VERSION "dbc-export 1 2026.26.6.5"

NS_ :

BS_:

BU_: APP BMS CC CMP CMPD CP DAS DI DIF DIR EPBL EPBR EVSE FC GTW HCML HCMR HVP ICR PCS PCS2 PM PMF PMR PTC SCCM SDCR TAS UMC V2G VC VCBATT VCBATT1 VCBATT2 VCFRONT VCFRONT1 VCLEFT VCRIGHT VCSEC

BO_ 680 EPBL_status: 8 EPBL
 SG_ EPBL_systemStatus : 0|4@1+ (1,0) [0|15] "" Vector__XXX
 SG_ EPBL_freeRollModeStatus : 4|2@1+ (1,0) [0|3] "" Vector__XXX
 SG_ EPBL_driverIsLeaving : 6|1@1+ (1,0) [0|1] "" Vector__XXX
 SG_ EPBL_driverIsLeavingAnySpeed : 7|1@1+ (1,0) [0|1] "" Vector__XXX
 SG_ EPBL_systemCdpAvailable : 8|1@1+ (1,0) [0|1] "" Vector__XXX
 SG_ EPBL_chimeRequest : 9|3@1+ (1,0) [0|7] "" Vector__XXX
 SG_ EPBL_telltale : 12|3@1+ (1,0) [0|6] "" Vector__XXX
 SG_ EPBL_contactorCycleNotNeededForW : 15|1@1+ (1,0) [0|1] "" Vector__XXX
 SG_ EPBL_redundantBrakingEnabled : 16|1@1+ (1,0) [0|1] "" Vector__XXX
 SG_ EPBL_summonEnabled : 17|1@1+ (1,0) [0|1] "" Vector__XXX
 SG_ EPBL_brakeLight : 18|1@1+ (1,0) [0|1] "" Vector__XXX
 SG_ EPBL_epbConfigMismatch : 19|1@1+ (1,0) [0|1] "" Vector__XXX
 SG_ EPBL_brakeConfirmedPressed : 20|1@1+ (1,0) [0|1] "" Vector__XXX
 SG_ EPBL_requestUserConfirmation : 21|1@1+ (1,0) [0|1] "" Vector__XXX
 SG_ EPBL_uiWinchModeMiscBlocking : 22|1@1+ (1,0) [0|1] "" Vector__XXX
 SG_ EPBL_winchModeActive : 23|1@1+ (1,0) [0|1] "" Vector__XXX
 SG_ EPBL_updateMode : 24|1@1+ (1,0) [0|1] "" Vector__XXX
 SG_ EPBL_winchModePermissive : 25|1@1+ (1,0) [0|1] "" Vector__XXX
 SG_ EPBL_winchModePending : 26|1@1+ (1,0) [0|1] "" Vector__XXX
 SG_ EPBL_cdpRequest : 27|1@1+ (1,0) [0|1] "" Vector__XXX
 SG_ EPBL_uiParkAvailable : 28|2@1+ (1,0) [0|3] "" Vector__XXX
 SG_ EPBL_brakeDiscWipeRequest : 30|2@1+ (1,0) [0|2] "" Vector__XXX
 SG_ EPBL_showUiGearShifter : 32|1@1+ (1,0) [0|1] "" Vector__XXX
 SG_ EPBL_uiWinchModeLvStatus : 33|2@1+ (1,0) [0|3] "" Vector__XXX
 SG_ EPBL_autonomyBehavior : 43|2@1+ (1,0) [0|3] "" Vector__XXX
 SG_ EPBL_showStalkFaultedOnUi : 45|1@1+ (1,0) [0|1] "" Vector__XXX
 SG_ EPBL_espPowerRequest : 46|1@1+ (1,0) [0|1] "" Vector__XXX
 SG_ EPBL_okToPark : 47|1@1+ (1,0) [0|1] "" Vector__XXX
 SG_ EPBL_hornRequest : 48|1@1+ (1,0) [0|1] "" Vector__XXX
 SG_ EPBL_winchModeAvailable : 49|1@1+ (1,0) [0|1] "" Vector__XXX
 SG_ EPBL_bothDisconnected : 50|1@1+ (1,0) [0|1] "" Vector__XXX
 SG_ EPBL_blockDrive : 51|1@1+ (1,0) [0|1] "" Vector__XXX
 SG_ EPBL_statusCounter : 52|4@1+ (1,0) [0|15] "" Vector__XXX
 SG_ EPBL_statusChecksum : 56|8@1+ (1,0) [0|255] "" Vector__XXX

BO_ 2024 EPBR_info: 8 EPBR
 SG_ EPBR_infoIndex M : 0|8@1+ (1,0) [0|255] "" Vector__XXX
 SG_ EPBR_infoBuildType m10 : 8|3@1+ (1,0) [0|7] "" Vector__XXX
 SG_ EPBR_infoBuildConfigId m10 : 16|16@1+ (1,0) [0|65535] "" Vector__XXX
 SG_ EPBR_infoHardwareId m10 : 32|16@1+ (1,0) [0|65535] "" Vector__XXX
 SG_ EPBR_infoComponentId m10 : 48|16@1+ (1,0) [0|65535] "" Vector__XXX
 SG_ EPBR_infoPcbaId m11 : 8|8@1+ (1,0) [0|255] "" Vector__XXX
 SG_ EPBR_infoAssemblyId m11 : 16|8@1+ (1,0) [0|254] "" Vector__XXX
 SG_ EPBR_infoUsageId m11 : 24|16@1+ (1,0) [0|65535] "" Vector__XXX
 SG_ EPBR_infoSubUsageId m11 : 40|16@1+ (1,0) [0|65535] "" Vector__XXX
 SG_ EPBR_infoAppCrc m13 : 8|32@1+ (1,0) [0|4294967295] "" Vector__XXX
 SG_ EPBR_infoAppGitHash m17 : 8|56@1+ (1,0) [0|7.20575940379e+16] "" Vector__XXX
 SG_ EPBR_infoBootGitHash m18 : 8|56@1+ (1,0) [0|7.20575940379e+16] "" Vector__XXX
 SG_ EPBR_infoPlatformType m19 : 8|8@1+ (1,0) [0|255] "" Vector__XXX
 SG_ EPBR_infoBootUdsProtoVersion m20 : 8|16@1+ (1,0) [0|65535] "" Vector__XXX
 SG_ EPBR_infoBootCrc m20 : 24|32@1+ (1,0) [0|4294967295] "" Vector__XXX

BO_ 552 EPBR_internalStatus: 8 EPBR
 SG_ EPBR_unitStatus : 0|5@1+ (1,0) [0|31] "" Vector__XXX
 SG_ EPBR_unitFaultStatus : 5|2@1+ (1,0) [0|3] "" Vector__XXX
 SG_ EPBR_summonState : 8|3@1+ (1,0) [0|7] "" Vector__XXX
 SG_ EPBR_disconnected : 11|1@1+ (1,0) [0|1] "" Vector__XXX
 SG_ EPBR_pistonTouchingRotor : 12|1@1+ (1,0) [0|1] "" Vector__XXX
 SG_ EPBR_csmFaultReason : 13|5@1+ (1,0) [0|31] "" Vector__XXX
 SG_ EPBR_esmOperationTrigger : 18|6@1+ (1,0) [0|63] "" Vector__XXX
 SG_ EPBR_summonFaultReason : 24|5@1+ (1,0) [0|31] "" Vector__XXX
 SG_ EPBR_localServiceModeActive : 29|1@1+ (1,0) [0|1] "" Vector__XXX
 SG_ EPBR_localCdpState : 30|2@1+ (1,0) [0|3] "" Vector__XXX
 SG_ EPBR_chimeRequestLocal : 33|3@1+ (1,0) [0|7] "" Vector__XXX
 SG_ EPBR_telltaleLocal : 39|3@1+ (1,0) [0|6] "" Vector__XXX
 SG_ EPBR_driverIsLeavingLocal : 42|1@1+ (1,0) [0|1] "" Vector__XXX
 SG_ EPBR_driverIsLeavingAnySpeedLoca : 43|1@1+ (1,0) [0|1] "" Vector__XXX
 SG_ EPBR_internalCDPRequest : 44|1@1+ (1,0) [0|1] "" Vector__XXX
 SG_ EPBR_esmSpeedClass : 45|3@1+ (1,0) [0|7] "" Vector__XXX
 SG_ EPBR_learnedEpbConfig : 48|4@1+ (1,0) [0|15] "" Vector__XXX
 SG_ EPBR_internalStatusCounter : 52|4@1+ (1,0) [0|15] "" Vector__XXX
 SG_ EPBR_internalStatusChecksum : 56|8@1+ (1,0) [0|255] "" Vector__XXX

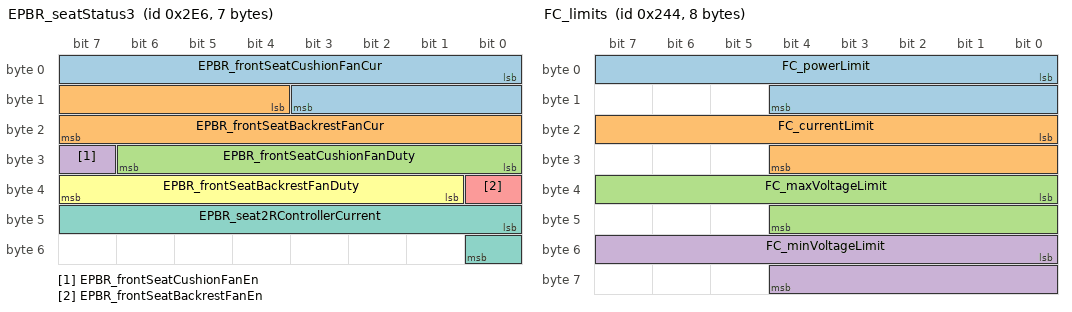
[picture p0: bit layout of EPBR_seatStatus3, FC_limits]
BO_ 742 EPBR_seatStatus3: 7 EPBR
 SG_ EPBR_frontSeatCushionFanCur : 0|12@1+ (0.01,0) [0|40.95] "A" Vector__XXX
 SG_ EPBR_frontSeatBackrestFanCur : 12|12@1+ (0.01,0) [0|40.95] "A" Vector__XXX
 SG_ EPBR_frontSeatCushionFanDuty : 24|7@1+ (1,0) [0|100] "%" Vector__XXX
 SG_ EPBR_frontSeatCushionFanEn : 31|1@1+ (1,0) [0|1] "" Vector__XXX
 SG_ EPBR_frontSeatBackrestFanEn : 32|1@1+ (1,0) [0|1] "" Vector__XXX
 SG_ EPBR_frontSeatBackrestFanDuty : 33|7@1+ (1,0) [0|100] "%" Vector__XXX
 SG_ EPBR_seat2RControllerCurrent : 40|9@1+ (0.2,0) [0|102] "A" Vector__XXX

BO_ 744 EPBR_status: 8 EPBR
 SG_ EPBR_systemStatus : 0|4@1+ (1,0) [0|15] "" Vector__XXX
 SG_ EPBR_freeRollModeStatus : 4|2@1+ (1,0) [0|3] "" Vector__XXX
 SG_ EPBR_driverIsLeaving : 6|1@1+ (1,0) [0|1] "" Vector__XXX
 SG_ EPBR_driverIsLeavingAnySpeed : 7|1@1+ (1,0) [0|1] "" Vector__XXX
 SG_ EPBR_systemCdpAvailable : 8|1@1+ (1,0) [0|1] "" Vector__XXX
 SG_ EPBR_chimeRequest : 9|3@1+ (1,0) [0|7] "" Vector__XXX
 SG_ EPBR_telltale : 12|3@1+ (1,0) [0|6] "" Vector__XXX
 SG_ EPBR_audioCurrentSpikeDetected : 15|1@1+ (1,0) [0|1] "" Vector__XXX
 SG_ EPBR_redundantBrakingEnabled : 16|1@1+ (1,0) [0|1] "" Vector__XXX
 SG_ EPBR_summonEnabled : 17|1@1+ (1,0) [0|1] "" Vector__XXX
 SG_ EPBR_brakeLight : 18|1@1+ (1,0) [0|1] "" Vector__XXX
 SG_ EPBR_epbConfigMismatch : 19|1@1+ (1,0) [0|1] "" Vector__XXX
 SG_ EPBR_brakeConfirmedPressed : 20|1@1+ (1,0) [0|1] "" Vector__XXX
 SG_ EPBR_requestUserConfirmation : 21|1@1+ (1,0) [0|1] "" Vector__XXX
 SG_ EPBR_uiWinchModeMiscBlocking : 22|1@1+ (1,0) [0|1] "" Vector__XXX
 SG_ EPBR_winchModeActive : 23|1@1+ (1,0) [0|1] "" Vector__XXX
 SG_ EPBR_updateMode : 24|1@1+ (1,0) [0|1] "" Vector__XXX
 SG_ EPBR_winchModePermissive : 25|1@1+ (1,0) [0|1] "" Vector__XXX
 SG_ EPBR_winchModePending : 26|1@1+ (1,0) [0|1] "" Vector__XXX
 SG_ EPBR_cdpRequest : 27|1@1+ (1,0) [0|1] "" Vector__XXX
 SG_ EPBR_uiParkAvailable : 28|2@1+ (1,0) [0|3] "" Vector__XXX
 SG_ EPBR_brakeDiscWipeRequest : 30|2@1+ (1,0) [0|2] "" Vector__XXX
 SG_ EPBR_showUiGearShifter : 32|1@1+ (1,0) [0|1] "" Vector__XXX
 SG_ EPBR_uiWinchModeLvStatus : 33|2@1+ (1,0) [0|3] "" Vector__XXX
 SG_ EPBR_contactorCycleNotNeededForW : 35|1@1+ (1,0) [0|1] "" Vector__XXX
 SG_ EPBR_autonomyBehavior : 43|2@1+ (1,0) [0|3] "" Vector__XXX
 SG_ EPBR_showStalkFaultedOnUi : 45|1@1+ (1,0) [0|1] "" Vector__XXX
 SG_ EPBR_espPowerRequest : 46|1@1+ (1,0) [0|1] "" Vector__XXX
 SG_ EPBR_okToPark : 47|1@1+ (1,0) [0|1] "" Vector__XXX
 SG_ EPBR_hornRequest : 48|1@1+ (1,0) [0|1] "" Vector__XXX
 SG_ EPBR_winchModeAvailable : 49|1@1+ (1,0) [0|1] "" Vector__XXX
 SG_ EPBR_bothDisconnected : 50|1@1+ (1,0) [0|1] "" Vector__XXX
 SG_ EPBR_blockDrive : 51|1@1+ (1,0) [0|1] "" Vector__XXX
 SG_ EPBR_statusCounter : 52|4@1+ (1,0) [0|15] "" Vector__XXX
 SG_ EPBR_statusChecksum : 56|8@1+ (1,0) [0|255] "" Vector__XXX

BO_ 1662 EVSE_isoTpToVeh: 8 EVSE
 SG_ EVSE_isoTpToVehData : 0|64@1+ (1,0) [0|1.84467440737e+19] "" Vector__XXX

BO_ 1117 FC_evseBilling: 8 FC
 SG_ FC_evseBillingDataSelect M : 0|1@1+ (1,0) [0|1] "" Vector__XXX
 SG_ FC_evseBillingEnergy m0 : 4|20@1+ (0.001,0) [0|1048.575] "kWh" Vector__XXX
 SG_ FC_evseMeterPower m0 : 24|20@1+ (0.001,0) [0|1048.575] "kW" Vector__XXX
 SG_ FC_evseMeterCurrent m0 : 44|10@1+ (1,0) [0|1023] "A" Vector__XXX
 SG_ FC_evseMeterVoltage m0 : 54|10@1+ (1,0) [0|1023] "V" Vector__XXX
 SG_ FC_evseMeterFwGitHash m1 : 4|56@1+ (1,0) [0|7.20575940379e+16] "" Vector__XXX

BO_ 1334 FC_evseBilling2: 8 FC
 SG_ FC_evseBilling2DataSelect M : 0|4@1+ (1,0) [0|15] "" Vector__XXX
 SG_ FC_evsePpuEnabled m0 : 4|1@1+ (1,0) [0|1] "" Vector__XXX
 SG_ FC_evseBillingEnergyHighRes m0 : 8|24@1+ (0.0001,0) [0|1677.7214] "kWh" Vector__XXX

BO_ 1303 FC_identifier: 8 FC
 SG_ FC_id : 0|32@1+ (1,0) [0|4294967295] "" Vector__XXX
 SG_ FC_sessionId : 32|32@1+ (1,0) [0|4294967295] "" Vector__XXX

BO_ 1310 FC_info: 8 FC
 SG_ FC_infoIndex M : 0|8@1+ (1,0) [0|255] "" Vector__XXX
 SG_ FC_infoBuildType m10 : 8|8@1+ (1,0) [0|255] "" Vector__XXX
 SG_ FC_infoBuildConfigID m10 : 16|16@1+ (1,0) [0|65535] "" Vector__XXX
 SG_ FC_infoHardwareID m10 : 32|16@1+ (1,0) [0|65535] "" Vector__XXX
 SG_ FC_infoComponentID m10 : 48|16@1+ (1,0) [0|65535] "" Vector__XXX
 SG_ FC_infoPcbaID m11 : 16|8@1+ (1,0) [0|255] "" Vector__XXX
 SG_ FC_infoAssemblyID m11 : 24|8@1+ (1,0) [0|255] "" Vector__XXX
 SG_ FC_infoUsageID m11 : 32|16@1+ (1,0) [0|65535] "" Vector__XXX
 SG_ FC_infoSubUsageID m11 : 48|16@1+ (1,0) [0|65535] "" Vector__XXX
 SG_ FC_infoApplicationCRC m13 : 32|32@1+ (1,0) [0|4294967295] "" Vector__XXX
 SG_ FC_infoAppGitHashBytes m17 : 8|56@1+ (1,0) [0|7.20575940379e+16] "" Vector__XXX
 SG_ FC_infoBootGitHashBytes m18 : 8|56@1+ (1,0) [0|7.20575940379e+16] "" Vector__XXX
 SG_ FC_infoPlatformType m19 : 8|8@1+ (1,0) [0|255] "" Vector__XXX
 SG_ FC_infoMajorVersion m19 : 16|8@1+ (1,0) [0|255] "" Vector__XXX
 SG_ FC_infoBranchOrigin m19 : 24|8@1+ (1,0) [0|255] "" Vector__XXX
 SG_ FC_infoMaturity m19 : 32|8@1+ (1,0) [0|255] "" Vector__XXX
 SG_ FC_infoHardwareRevision m19 : 40|8@1+ (1,0) [0|255] "" Vector__XXX
 SG_ FC_partNumChar01 m25 : 8|8@1+ (1,0) [0|255] "" Vector__XXX
 SG_ FC_partNumChar02 m25 : 16|8@1+ (1,0) [0|255] "" Vector__XXX
 SG_ FC_partNumChar03 m25 : 24|8@1+ (1,0) [0|255] "" Vector__XXX
 SG_ FC_partNumChar04 m25 : 32|8@1+ (1,0) [0|255] "" Vector__XXX
 SG_ FC_partNumChar05 m25 : 40|8@1+ (1,0) [0|255] "" Vector__XXX
 SG_ FC_partNumChar06 m25 : 48|8@1+ (1,0) [0|255] "" Vector__XXX
 SG_ FC_partNumChar07 m25 : 56|8@1+ (1,0) [0|255] "" Vector__XXX
 SG_ FC_partNumChar08 m26 : 8|8@1+ (1,0) [0|255] "" Vector__XXX
 SG_ FC_partNumChar09 m26 : 16|8@1+ (1,0) [0|255] "" Vector__XXX
 SG_ FC_partNumChar10 m26 : 24|8@1+ (1,0) [0|255] "" Vector__XXX
 SG_ FC_partNumChar11 m26 : 32|8@1+ (1,0) [0|255] "" Vector__XXX
 SG_ FC_partNumChar12 m26 : 40|8@1+ (1,0) [0|255] "" Vector__XXX
 SG_ FC_partNumChar13 m26 : 48|8@1+ (1,0) [0|255] "" Vector__XXX
 SG_ FC_partNumChar14 m26 : 56|8@1+ (1,0) [0|255] "" Vector__XXX
 SG_ FC_partNumChar15 m27 : 8|8@1+ (1,0) [0|255] "" Vector__XXX
 SG_ FC_partNumChar16 m27 : 16|8@1+ (1,0) [0|255] "" Vector__XXX
 SG_ FC_partNumChar17 m27 : 24|8@1+ (1,0) [0|255] "" Vector__XXX
 SG_ FC_partNumChar18 m27 : 32|8@1+ (1,0) [0|255] "" Vector__XXX
 SG_ FC_partNumChar19 m27 : 40|8@1+ (1,0) [0|255] "" Vector__XXX
 SG_ FC_partNumChar20 m27 : 48|8@1+ (1,0) [0|255] "" Vector__XXX

BO_ 580 FC_limits: 8 FC
 SG_ FC_powerLimit : 0|13@1+ (0.06225586,0) [0|509.8754934] "kW" Vector__XXX
 SG_ FC_currentLimit : 16|13@1+ (0.07324219,0) [0|599.8535361] "A" Vector__XXX
 SG_ FC_maxVoltageLimit : 32|13@1+ (0.07324219,0) [0|599.8535361] "V" Vector__XXX
 SG_ FC_minVoltageLimit : 48|13@1+ (0.07324219,0) [0|599.8535361] "V" Vector__XXX

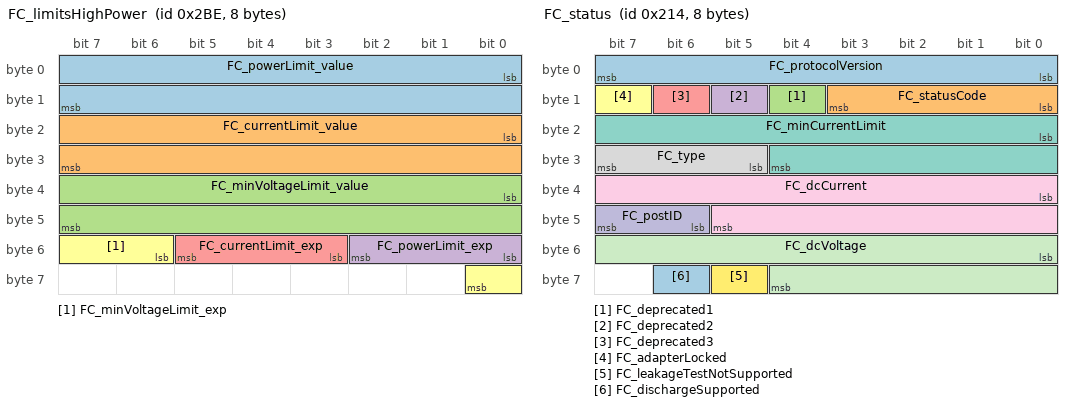
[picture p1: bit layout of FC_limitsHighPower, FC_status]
BO_ 702 FC_limitsHighPower: 8 FC
 SG_ FC_powerLimit_value : 0|16@1- (1,0) [-32767|32767] "*10^exp kW" Vector__XXX
 SG_ FC_currentLimit_value : 16|16@1- (1,0) [-32767|32767] "*10^exp A" Vector__XXX
 SG_ FC_minVoltageLimit_value : 32|16@1- (1,0) [-32767|32767] "*10^exp V" Vector__XXX
 SG_ FC_powerLimit_exp : 48|3@1- (1,0) [-4|3] "" Vector__XXX
 SG_ FC_currentLimit_exp : 51|3@1- (1,0) [-4|3] "" Vector__XXX
 SG_ FC_minVoltageLimit_exp : 54|3@1- (1,0) [-4|3] "" Vector__XXX

BO_ 1345 FC_maxLimits: 8 FC
 SG_ FC_maxPowerLimit : 0|13@1+ (0.06225586,0) [0|509.8754934] "kW" Vector__XXX
 SG_ FC_maxCurrentLimit : 16|13@1+ (0.07324219,0) [0|599.8535361] "A" Vector__XXX

BO_ 1300 FC_serial: 8 FC
 SG_ FC_serialDataSelect M : 0|7@1+ (1,0) [0|127] "" Vector__XXX
 SG_ FC_serialChar01 m0 : 8|8@1+ (1,0) [0|255] "" Vector__XXX
 SG_ FC_serialChar02 m0 : 16|8@1+ (1,0) [0|255] "" Vector__XXX
 SG_ FC_serialChar03 m0 : 24|8@1+ (1,0) [0|255] "" Vector__XXX
 SG_ FC_serialChar04 m0 : 32|8@1+ (1,0) [0|255] "" Vector__XXX
 SG_ FC_serialChar05 m0 : 40|8@1+ (1,0) [0|255] "" Vector__XXX
 SG_ FC_serialChar06 m0 : 48|8@1+ (1,0) [0|255] "" Vector__XXX
 SG_ FC_serialChar07 m0 : 56|8@1+ (1,0) [0|255] "" Vector__XXX
 SG_ FC_serialChar08 m1 : 8|8@1+ (1,0) [0|255] "" Vector__XXX
 SG_ FC_serialChar09 m1 : 16|8@1+ (1,0) [0|255] "" Vector__XXX
 SG_ FC_serialChar10 m1 : 24|8@1+ (1,0) [0|255] "" Vector__XXX
 SG_ FC_serialChar11 m1 : 32|8@1+ (1,0) [0|255] "" Vector__XXX
 SG_ FC_serialChar12 m1 : 40|8@1+ (1,0) [0|255] "" Vector__XXX
 SG_ FC_serialChar13 m1 : 48|8@1+ (1,0) [0|255] "" Vector__XXX
 SG_ FC_serialChar14 m1 : 56|8@1+ (1,0) [0|255] "" Vector__XXX
 SG_ FC_serialChar15 m2 : 8|8@1+ (1,0) [0|255] "" Vector__XXX
 SG_ FC_serialChar16 m2 : 16|8@1+ (1,0) [0|255] "" Vector__XXX
 SG_ FC_serialChar17 m2 : 24|8@1+ (1,0) [0|255] "" Vector__XXX

BO_ 532 FC_status: 8 FC
 SG_ FC_protocolVersion : 0|8@1+ (1,0) [0|255] "" Vector__XXX
 SG_ FC_statusCode : 8|4@1+ (1,0) [1|15] "" Vector__XXX
 SG_ FC_deprecated1 : 12|1@1+ (1,0) [0|1] "" Vector__XXX
 SG_ FC_deprecated2 : 13|1@1+ (1,0) [0|1] "" Vector__XXX
 SG_ FC_deprecated3 : 14|1@1+ (1,0) [0|1] "" Vector__XXX
 SG_ FC_adapterLocked : 15|1@1+ (1,0) [0|1] "" Vector__XXX
 SG_ FC_minCurrentLimit : 16|13@1+ (0.1,0) [0|600] "A" Vector__XXX
 SG_ FC_type : 29|3@1+ (1,0) [0|6] "" Vector__XXX
 SG_ FC_dcCurrent : 32|14@1- (0.07324219,0) [-600|599.92675781] "A" Vector__XXX
 SG_ FC_postID : 46|2@1+ (1,0) [0|2] "" Vector__XXX
 SG_ FC_dcVoltage : 48|13@1+ (0.07324219,0) [0|599.92675822] "V" Vector__XXX
 SG_ FC_leakageTestNotSupported : 61|1@1+ (1,0) [0|1] "" Vector__XXX
 SG_ FC_dischargeSupported : 62|1@1+ (1,0) [0|1] "" Vector__XXX

BO_ 533 FC_status2: 1 FC
 SG_ FC_externalIsolationResistance : 0|8@1+ (40,0) [0|10160] "kOhm" Vector__XXX

BO_ 535 FC_status3: 8 FC
 SG_ FC_status3DataSelect M : 0|7@1+ (1,0) [0|127] "" Vector__XXX
 SG_ FC_status3DummySig : 7|1@1+ (1,0) [0|1] "" Vector__XXX
 SG_ FC_class m0 : 8|8@1+ (1,0) [1|255] "" Vector__XXX
 SG_ FC_brand m0 : 16|4@1+ (1,0) [1|15] "" Vector__XXX
 SG_ FC_coolingType m0 : 20|4@1+ (1,0) [1|15] "" Vector__XXX
 SG_ FC_uiStopType m0 : 24|4@1+ (1,0) [1|15] "" Vector__XXX
 SG_ FC_emergencyShutdownSupported m0 : 28|1@1+ (1,0) [0|1] "" Vector__XXX
 SG_ FC_generation m0 : 32|8@1+ (1,0) [1|255] "" Vector__XXX

BO_ 1650 HCML_info: 8 HCML
 SG_ VC_hcmlInfoIndex M : 0|4@1+ (1,0) [0|15] "" Vector__XXX
 SG_ VC_infoHCMLBuildConfigId m0 : 8|16@1+ (1,0) [0|65535] "" Vector__XXX
 SG_ VC_leftHeadlampLMMVariant m0 : 24|2@1+ (1,0) [1|3] "" Vector__XXX
 SG_ VC_infoHCMLAssemblyId m1 : 8|16@1+ (1,0) [0|65535] "" Vector__XXX
 SG_ VC_infoHCMLPcbaId m1 : 24|16@1+ (1,0) [0|65535] "" Vector__XXX
 SG_ VC_infoHCMLUsageId m1 : 40|16@1+ (1,0) [0|65535] "" Vector__XXX

BO_ 1980 HCMR_info: 8 HCMR
 SG_ VC_hcmrInfoIndex M : 0|4@1+ (1,0) [0|15] "" Vector__XXX
 SG_ VC_infoHCMRBuildConfigId m0 : 8|16@1+ (1,0) [0|65535] "" Vector__XXX
 SG_ VC_rightHeadlampLMMVariant m0 : 24|2@1+ (1,0) [1|3] "" Vector__XXX
 SG_ VC_infoHCMRAssemblyId m1 : 8|16@1+ (1,0) [0|65535] "" Vector__XXX
 SG_ VC_infoHCMRPcbaId m1 : 24|16@1+ (1,0) [0|65535] "" Vector__XXX
 SG_ VC_infoHCMRUsageId m1 : 40|16@1+ (1,0) [0|65535] "" Vector__XXX

BO_ 522 HVP_contactorState: 6 HVP
 SG_ HVP_packContNegativeState : 0|3@1+ (1,0) [1|7] "" Vector__XXX
 SG_ HVP_packContPositiveState : 3|3@1+ (1,0) [1|7] "" Vector__XXX
 SG_ HVP_fcContPositiveAuxOpen : 6|1@1+ (1,0) [0|1] "" Vector__XXX
 SG_ HVP_fcContNegativeAuxOpen : 7|1@1+ (1,0) [0|1] "" Vector__XXX
 SG_ HVP_packContactorSetState : 8|4@1+ (1,0) [1|15] "" Vector__XXX
 SG_ HVP_fcContNegativeState : 12|3@1+ (1,0) [1|7] "" Vector__XXX
 SG_ HVP_contactorsBlocked : 15|1@1+ (1,0) [0|1] "" Vector__XXX
 SG_ HVP_fcContPositiveState : 16|3@1+ (1,0) [1|7] "" Vector__XXX
 SG_ HVP_fcContactorSetState : 19|4@1+ (1,0) [1|15] "" Vector__XXX
 SG_ HVP_fcCtrsRequestStatus : 24|2@1+ (1,0) [0|3] "" Vector__XXX
 SG_ HVP_fcCtrsResetRequestRequired : 26|1@1+ (1,0) [0|1] "" Vector__XXX
 SG_ HVP_fcCtrsOpenNowRequested : 27|1@1+ (1,0) [0|1] "" Vector__XXX
 SG_ HVP_fcCtrsOpenRequested : 28|1@1+ (1,0) [0|1] "" Vector__XXX
 SG_ HVP_fcCtrsClosingAllowed : 29|1@1+ (1,0) [0|1] "" Vector__XXX
 SG_ HVP_packCtrsRequestStatus : 30|2@1+ (1,0) [0|3] "" Vector__XXX
 SG_ HVP_packCtrsResetRequestRequired : 32|1@1+ (1,0) [0|1] "" Vector__XXX
 SG_ HVP_packCtrsOpenNowRequested : 33|1@1+ (1,0) [0|1] "" Vector__XXX
 SG_ HVP_packCtrsOpenRequested : 34|1@1+ (1,0) [0|1] "" Vector__XXX
 SG_ HVP_packCtrsClosingAllowed : 35|1@1+ (1,0) [0|1] "" Vector__XXX
 SG_ HVP_dcLinkAllowedToEnergize : 36|1@1+ (1,0) [0|1] "" Vector__XXX
 SG_ HVP_pyroTestInProgress : 37|1@1+ (1,0) [0|1] "" Vector__XXX
 SG_ HVP_hvilDiag : 40|4@1+ (1,0) [0|15] "" Vector__XXX
 SG_ HVP_fcLinkAllowedToEnergize : 44|2@1+ (1,0) [0|3] "" Vector__XXX

BO_ 1962 HVP_debugMessage: 8 HVP
 SG_ HVP_debugMessageMultiplexer M : 0|4@1+ (1,0) [0|15] "" Vector__XXX
 SG_ HVP_ecuLogUploadRequest m1 : 4|2@1+ (1,0) [0|3] "" Vector__XXX
 SG_ HVP_dcLinkVoltage m1 : 8|16@1- (0.1,0) [-3276.8|3276.7] "V" Vector__XXX
 SG_ HVP_packVoltage m1 : 24|16@1- (0.1,0) [-3276.8|3276.7] "V" Vector__XXX
 SG_ HVP_fcLinkVoltage m1 : 40|16@1- (0.1,0) [-3276.8|3276.7] "V" Vector__XXX
 SG_ HVP_10HzTask_stackUsage m1 : 56|7@1+ (1,0) [0|100] "%" Vector__XXX
 SG_ HVP_packContVoltage m2 : 4|12@1+ (0.1,0) [0|30] "V" Vector__XXX
 SG_ HVP_packNegativeV m2 : 16|16@1- (0.1,0) [-550|550] "V" Vector__XXX
 SG_ HVP_packPositiveV m2 : 32|16@1- (0.1,0) [-550|550] "V" Vector__XXX
 SG_ HVP_pyroAnalog m2 : 48|12@1+ (0.1,0) [0|3] "V" Vector__XXX
 SG_ HVP_shuntSetTCRCoeffA m2 : 60|1@1+ (1,0) [0|1] "" Vector__XXX
 SG_ HVP_shuntSetTCRCoeffB m2 : 61|1@1+ (1,0) [0|1] "" Vector__XXX
 SG_ HVP_shuntSetTCRCoeffC m2 : 62|1@1+ (1,0) [0|1] "" Vector__XXX
 SG_ HVP_shuntSetTCRCoeffD m2 : 63|1@1+ (1,0) [0|1] "" Vector__XXX
 SG_ HVP_fcContCoilCurrent m4 : 4|12@1+ (0.1,0) [0|7.5] "A" Vector__XXX
 SG_ HVP_fcContVoltage m4 : 16|12@1+ (0.1,0) [0|30] "V" Vector__XXX
 SG_ HVP_hvilInVoltage m4 : 28|12@1+ (0.1,0) [0|30] "V" Vector__XXX
 SG_ HVP_hvilOutVoltage m4 : 40|12@1+ (0.1,0) [0|30] "V" Vector__XXX
 SG_ HVP_shuntGainInvalidCountDbg m4 : 56|8@1+ (1,0) [0|255] "counts" Vector__XXX
 SG_ HVP_passivePyroRefVoltageMax m5 : 4|10@1+ (0.001,0.7) [0.7|1.722] "V" Vector__XXX
 SG_ HVP_passivePyroRefVoltageMin m5 : 14|10@1+ (0.001,0.7) [0.7|1.722] "V" Vector__XXX
 SG_ HVP_packContCoilCurrent m5 : 24|12@1+ (0.1,0) [0|7.5] "A" Vector__XXX
 SG_ HVP_battery12V m5 : 36|12@1+ (0.1,0) [0|30] "V" Vector__XXX
 SG_ HVP_fcLinkPositiveV m5 : 48|16@1- (0.1,0) [-550|550] "V" Vector__XXX

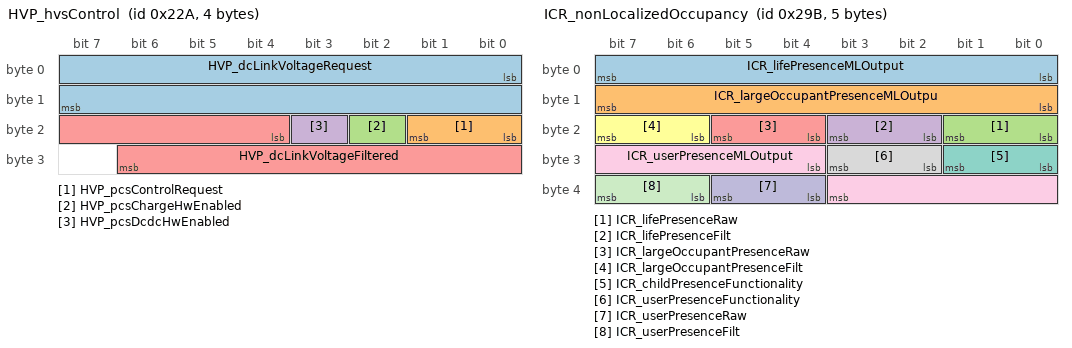
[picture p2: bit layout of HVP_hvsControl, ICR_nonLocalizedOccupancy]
BO_ 554 HVP_hvsControl: 4 HVP
 SG_ HVP_dcLinkVoltageRequest : 0|16@1- (0.1,0) [-550|550] "V" Vector__XXX
 SG_ HVP_pcsControlRequest : 16|2@1+ (1,0) [0|3] "" Vector__XXX
 SG_ HVP_pcsChargeHwEnabled : 18|1@1+ (1,0) [0|1] "" Vector__XXX
 SG_ HVP_pcsDcdcHwEnabled : 19|1@1+ (1,0) [0|1] "" Vector__XXX
 SG_ HVP_dcLinkVoltageFiltered : 20|11@1- (1,0) [-550|550] "V" Vector__XXX

BO_ 784 HVP_info: 8 HVP
 SG_ HVP_infoIndex M : 0|8@1+ (1,0) [0|255] "" Vector__XXX
 SG_ HVP_buildType m10 : 8|3@1+ (1,0) [0|7] "" Vector__XXX
 SG_ HVP_buildConfigId m10 : 16|16@1+ (1,0) [0|65535] "" Vector__XXX
 SG_ HVP_hardwareId m10 : 32|16@1+ (1,0) [0|65535] "" Vector__XXX
 SG_ HVP_componentId m10 : 48|16@1+ (1,0) [0|65535] "" Vector__XXX
 SG_ HVP_pcbaId m11 : 16|8@1+ (1,0) [0|255] "" Vector__XXX
 SG_ HVP_assemblyId m11 : 24|8@1+ (1,0) [0|255] "" Vector__XXX
 SG_ HVP_usageId m11 : 32|16@1+ (1,0) [0|65535] "" Vector__XXX
 SG_ HVP_subUsageId m11 : 48|16@1+ (1,0) [0|65535] "" Vector__XXX
 SG_ HVP_platformType m13 : 8|8@1+ (1,0) [0|255] "" Vector__XXX
 SG_ HVP_appCrc m13 : 32|32@1+ (1,0) [0|4294967295] "" Vector__XXX
 SG_ HVP_appGitHash m17 : 8|56@1+ (1,0) [0|7.20575940379e+16] "" Vector__XXX
 SG_ HVP_bootGitHash m18 : 8|56@1+ (1,0) [0|7.20575940379e+16] "" Vector__XXX
 SG_ HVP_bootUdsProtoVersion m20 : 8|8@1+ (1,0) [0|255] "" Vector__XXX
 SG_ HVP_bootCrc m20 : 32|32@1+ (1,0) [0|4294967295] "" Vector__XXX

BO_ 1914 HVP_log1hz: 8 HVP
 SG_ HVP_log1HzIndex M : 0|3@1+ (1,0) [0|7] "" Vector__XXX
 SG_ HVP_bmbAsicType m0 : 3|2@1+ (1,0) [0|3] "" Vector__XXX
 SG_ HVP_shuntCurrentAuxLog m0 : 8|24@1- (0.001,0) [-8388.607|8388.607] "A" Vector__XXX
 SG_ HVP_pyroSquibResistance m0 : 32|16@1+ (0.001,0) [0|65.534] "Ohm" Vector__XXX
 SG_ HVP_shuntAsicChipXCoordinate m0 : 48|8@1+ (1,0) [0|255] "" Vector__XXX
 SG_ HVP_shuntAsicChipYCoordinate m0 : 56|8@1+ (1,0) [0|255] "" Vector__XXX
 SG_ HVP_hvilCalType m1 : 3|2@1+ (1,0) [0|3] "" Vector__XXX
 SG_ HVP_gpioPcsDcdcPwmEnable m1 : 5|1@1+ (1,0) [0|1] "" Vector__XXX
 SG_ HVP_gpioPcsChargePwmEnable m1 : 6|1@1+ (1,0) [0|1] "" Vector__XXX
 SG_ HVP_gpioPcsEnable m1 : 7|1@1+ (1,0) [0|1] "" Vector__XXX
 SG_ HVP_shuntAsicChipWaferNumber m1 : 8|8@1+ (1,0) [0|255] "" Vector__XXX
 SG_ HVP_energyReserveMin m1 : 16|16@1- (0.001,0) [-32.768|32.767] "V" Vector__XXX
 SG_ HVP_energyReserveMax m1 : 32|16@1- (0.001,0) [-32.768|32.767] "V" Vector__XXX
 SG_ HVP_energyReserveAvg m1 : 48|16@1- (0.001,0) [-32.768|32.767] "V" Vector__XXX

BO_ 941 ICR_info: 8 ICR
 SG_ ICR_infoIndex M : 0|8@1+ (1,0) [0|255] "" Vector__XXX
 SG_ ICR_infoBuildType m10 : 8|3@1+ (1,0) [0|7] "" Vector__XXX
 SG_ ICR_infoPcbaId m11 : 32|8@1+ (1,0) [0|255] "" Vector__XXX
 SG_ ICR_infoAssemblyId m11 : 40|8@1+ (1,0) [0|255] "" Vector__XXX
 SG_ ICR_infoUsageId m11 : 48|16@1+ (1,0) [0|65535] "" Vector__XXX
 SG_ ICR_infoAppCrc m13 : 8|32@1+ (1,0) [0|4294967295] "" Vector__XXX
 SG_ ICR_infoBoardPartNumber17 m25 : 8|56@1+ (1,0) [0|7.20575940379e+16] "" Vector__XXX
 SG_ ICR_infoBoardPartNumber814 m26 : 8|56@1+ (1,0) [0|7.20575940379e+16] "" Vector__XXX
 SG_ ICR_infoBoardPartNumber1520 m27 : 8|48@1+ (1,0) [0|281474976710655] "" Vector__XXX

BO_ 667 ICR_nonLocalizedOccupancy: 5 ICR
 SG_ ICR_lifePresenceMLOutput : 0|8@1+ (0.004,0) [0|1.016] "points" Vector__XXX
 SG_ ICR_largeOccupantPresenceMLOutpu : 8|8@1+ (0.004,0) [0|1.016] "points" Vector__XXX
 SG_ ICR_lifePresenceRaw : 16|2@1+ (1,0) [1|3] "" Vector__XXX
 SG_ ICR_lifePresenceFilt : 18|2@1+ (1,0) [1|3] "" Vector__XXX
 SG_ ICR_largeOccupantPresenceRaw : 20|2@1+ (1,0) [0|2] "" Vector__XXX
 SG_ ICR_largeOccupantPresenceFilt : 22|2@1+ (1,0) [0|2] "" Vector__XXX
 SG_ ICR_childPresenceFunctionality : 24|2@1+ (1,0) [0|3] "" Vector__XXX
 SG_ ICR_userPresenceFunctionality : 26|2@1+ (1,0) [0|3] "" Vector__XXX
 SG_ ICR_userPresenceMLOutput : 28|8@1+ (0.004,0) [0|1.016] "points" Vector__XXX
 SG_ ICR_userPresenceRaw : 36|2@1+ (1,0) [0|2] "" Vector__XXX
 SG_ ICR_userPresenceFilt : 38|2@1+ (1,0) [0|2] "" Vector__XXX

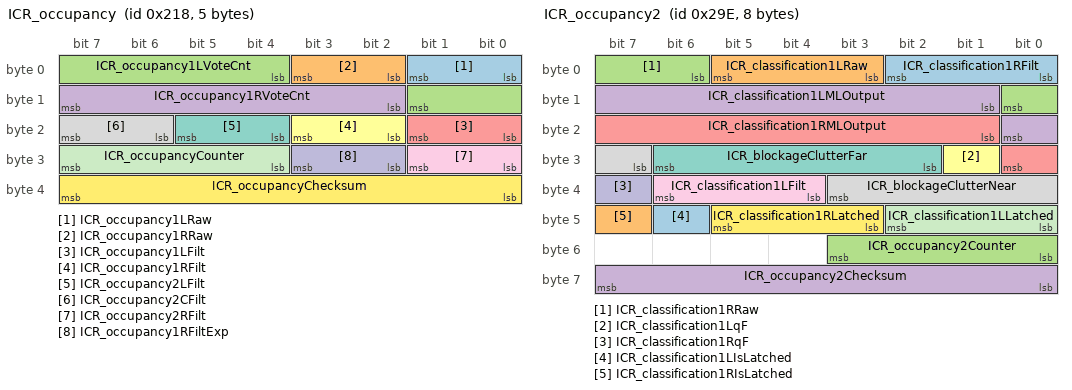
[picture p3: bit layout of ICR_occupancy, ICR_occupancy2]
BO_ 536 ICR_occupancy: 5 ICR
 SG_ ICR_occupancy1LRaw : 0|2@1+ (1,0) [0|2] "" Vector__XXX
 SG_ ICR_occupancy1RRaw : 2|2@1+ (1,0) [0|2] "" Vector__XXX
 SG_ ICR_occupancy1LVoteCnt : 4|6@1- (1,0) [-32|31] "" Vector__XXX
 SG_ ICR_occupancy1RVoteCnt : 10|6@1- (1,0) [-32|31] "" Vector__XXX
 SG_ ICR_occupancy1LFilt : 16|2@1+ (1,0) [0|2] "" Vector__XXX
 SG_ ICR_occupancy1RFilt : 18|2@1+ (1,0) [0|2] "" Vector__XXX
 SG_ ICR_occupancy2LFilt : 20|2@1+ (1,0) [0|2] "" Vector__XXX
 SG_ ICR_occupancy2CFilt : 22|2@1+ (1,0) [0|2] "" Vector__XXX
 SG_ ICR_occupancy2RFilt : 24|2@1+ (1,0) [0|2] "" Vector__XXX
 SG_ ICR_occupancy1RFiltExp : 26|2@1+ (1,0) [0|2] "" Vector__XXX
 SG_ ICR_occupancyCounter : 28|4@1+ (1,0) [0|15] "" Vector__XXX
 SG_ ICR_occupancyChecksum : 32|8@1+ (1,0) [0|255] "" Vector__XXX

BO_ 670 ICR_occupancy2: 8 ICR
 SG_ ICR_classification1RFilt : 0|3@1+ (1,0) [1|7] "" Vector__XXX
 SG_ ICR_classification1LRaw : 3|3@1+ (1,0) [1|7] "" Vector__XXX
 SG_ ICR_classification1RRaw : 6|3@1+ (1,0) [1|7] "" Vector__XXX
 SG_ ICR_classification1LMLOutput : 9|8@1+ (0.004,0) [0|1.016] "points" Vector__XXX
 SG_ ICR_classification1RMLOutput : 17|8@1+ (0.004,0) [0|1.016] "points" Vector__XXX
 SG_ ICR_classification1LqF : 25|1@1+ (1,0) [0|1] "" Vector__XXX
 SG_ ICR_blockageClutterFar : 26|5@1- (0.5,-1.5) [-9|6] "dB" Vector__XXX
 SG_ ICR_blockageClutterNear : 31|5@1- (0.5,-1.5) [-9|6] "dB" Vector__XXX
 SG_ ICR_classification1LFilt : 36|3@1+ (1,0) [1|7] "" Vector__XXX
 SG_ ICR_classification1RqF : 39|1@1+ (1,0) [0|1] "" Vector__XXX
 SG_ ICR_classification1LLatched : 40|3@1+ (1,0) [1|7] "" Vector__XXX
 SG_ ICR_classification1RLatched : 43|3@1+ (1,0) [1|7] "" Vector__XXX
 SG_ ICR_classification1LIsLatched : 46|1@1+ (1,0) [0|1] "" Vector__XXX
 SG_ ICR_classification1RIsLatched : 47|1@1+ (1,0) [0|1] "" Vector__XXX
 SG_ ICR_occupancy2Counter : 48|4@1+ (1,0) [0|15] "" Vector__XXX
 SG_ ICR_occupancy2Checksum : 56|8@1+ (1,0) [0|255] "" Vector__XXX

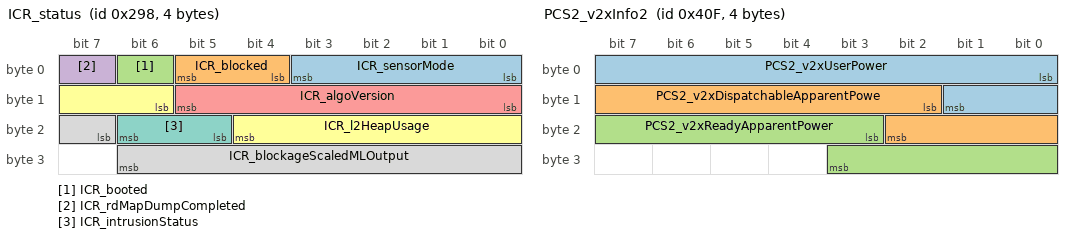
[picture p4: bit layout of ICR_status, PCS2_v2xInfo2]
BO_ 664 ICR_status: 4 ICR
 SG_ ICR_sensorMode : 0|4@1+ (1,0) [0|15] "" Vector__XXX
 SG_ ICR_blocked : 4|2@1+ (1,0) [1|3] "" Vector__XXX
 SG_ ICR_booted : 6|1@1+ (1,0) [0|1] "" Vector__XXX
 SG_ ICR_rdMapDumpCompleted : 7|1@1+ (1,0) [0|1] "" Vector__XXX
 SG_ ICR_algoVersion : 8|6@1+ (1,0) [0|63] "" Vector__XXX
 SG_ ICR_l2HeapUsage : 14|7@1+ (1,0) [0|127] "PCT" Vector__XXX
 SG_ ICR_intrusionStatus : 21|2@1+ (1,0) [0|3] "" Vector__XXX
 SG_ ICR_blockageScaledMLOutput : 23|8@1+ (0.004,0) [0|1.02] "points" Vector__XXX

BO_ 1012 LS_lightShow: 8 GTW
 SG_ LS_lightShowIndex M : 0|5@1+ (1,0) [0|31] "" Vector__XXX
 SG_ LS_lightLeftRampedChannel1Reques m0 : 5|1@1+ (1,0) [0|1] "" Vector__XXX
 SG_ LS_lightLeftRampedChannel1Durati m0 : 6|2@1+ (1,0) [0|3] "" Vector__XXX
 SG_ LS_lightLeftRampedChannel2Reques m0 : 8|1@1+ (1,0) [0|1] "" Vector__XXX
 SG_ LS_lightLeftRampedChannel2Durati m0 : 9|2@1+ (1,0) [0|3] "" Vector__XXX
 SG_ LS_lightLeftRampedChannel3Reques m0 : 11|1@1+ (1,0) [0|1] "" Vector__XXX
 SG_ LS_lightLeftRampedChannel3Durati m0 : 12|2@1+ (1,0) [0|3] "" Vector__XXX
 SG_ LS_lightLeftRampedChannel4Reques m0 : 14|1@1+ (1,0) [0|1] "" Vector__XXX
 SG_ LS_lightLeftRampedChannel4Durati m0 : 16|2@1+ (1,0) [0|3] "" Vector__XXX
 SG_ LS_lightLeftRampedChannel5Reques m0 : 18|1@1+ (1,0) [0|1] "" Vector__XXX
 SG_ LS_lightLeftRampedChannel5Durati m0 : 19|2@1+ (1,0) [0|3] "" Vector__XXX
 SG_ LS_lightLeftRampedChannel6Reques m0 : 21|1@1+ (1,0) [0|1] "" Vector__XXX
 SG_ LS_lightLeftRampedChannel6Durati m0 : 22|2@1+ (1,0) [0|3] "" Vector__XXX
 SG_ LS_lightLeftRampedChannel7Reques m0 : 24|1@1+ (1,0) [0|1] "" Vector__XXX
 SG_ LS_lightLeftRampedChannel7Durati m0 : 25|2@1+ (1,0) [0|3] "" Vector__XXX
 SG_ LS_lightRightRampedChannel1Reque m0 : 27|1@1+ (1,0) [0|1] "" Vector__XXX
 SG_ LS_lightRightRampedChannel1Durat m0 : 28|2@1+ (1,0) [0|3] "" Vector__XXX
 SG_ LS_lightRightRampedChannel2Reque m0 : 30|1@1+ (1,0) [0|1] "" Vector__XXX
 SG_ LS_lightRightRampedChannel2Durat m0 : 31|2@1+ (1,0) [0|3] "" Vector__XXX
 SG_ LS_lightRightRampedChannel3Reque m0 : 33|1@1+ (1,0) [0|1] "" Vector__XXX
 SG_ LS_lightRightRampedChannel3Durat m0 : 34|2@1+ (1,0) [0|3] "" Vector__XXX
 SG_ LS_lightRightRampedChannel4Reque m0 : 36|1@1+ (1,0) [0|1] "" Vector__XXX
 SG_ LS_lightRightRampedChannel4Durat m0 : 37|2@1+ (1,0) [0|3] "" Vector__XXX
 SG_ LS_lightRightRampedChannel5Reque m0 : 39|1@1+ (1,0) [0|1] "" Vector__XXX
 SG_ LS_lightRightRampedChannel5Durat m0 : 40|2@1+ (1,0) [0|3] "" Vector__XXX
 SG_ LS_lightRightRampedChannel6Reque m0 : 42|1@1+ (1,0) [0|1] "" Vector__XXX
 SG_ LS_lightRightRampedChannel6Durat m0 : 43|2@1+ (1,0) [0|3] "" Vector__XXX
 SG_ LS_lightRightRampedChannel7Reque m0 : 45|1@1+ (1,0) [0|1] "" Vector__XXX
 SG_ LS_lightRightRampedChannel7Durat m0 : 46|2@1+ (1,0) [0|3] "" Vector__XXX
 SG_ LS_lightRearTurnLeftRequest m0 : 48|1@1+ (1,0) [0|1] "" Vector__XXX
 SG_ LS_lightRearTurnRightRequest m0 : 49|1@1+ (1,0) [0|1] "" Vector__XXX
 SG_ LS_lightSideRepeaterLeftRequest m0 : 50|1@1+ (1,0) [0|1] "" Vector__XXX
 SG_ LS_lightSideRepeaterRightRequest m0 : 51|1@1+ (1,0) [0|1] "" Vector__XXX
 SG_ LS_lightSideMarkerLeftRequest m0 : 52|1@1+ (1,0) [0|1] "" Vector__XXX
 SG_ LS_lightSideMarkerRightRequest m0 : 53|1@1+ (1,0) [0|1] "" Vector__XXX
 SG_ LS_lightFrontFogLeftRequest m0 : 54|1@1+ (1,0) [0|1] "" Vector__XXX
 SG_ LS_lightFrontFogRightRequest m0 : 55|1@1+ (1,0) [0|1] "" Vector__XXX
 SG_ LS_lightRearFogRequest m0 : 56|1@1+ (1,0) [0|1] "" Vector__XXX
 SG_ LS_lightBrakeRequest m0 : 57|1@1+ (1,0) [0|1] "" Vector__XXX
 SG_ LS_lightTailLeftRequest m0 : 58|1@1+ (1,0) [0|1] "" Vector__XXX
 SG_ LS_lightTailRightRequest m0 : 59|1@1+ (1,0) [0|1] "" Vector__XXX
 SG_ LS_lightLicensePlateRequest m0 : 60|1@1+ (1,0) [0|1] "" Vector__XXX
 SG_ LS_lightReverseRequest m0 : 61|1@1+ (1,0) [0|1] "" Vector__XXX
 SG_ LS_lightAuxParkLeftRequest m0 : 62|1@1+ (1,0) [0|1] "" Vector__XXX
 SG_ LS_lightAuxParkRightRequest m0 : 63|1@1+ (1,0) [0|1] "" Vector__XXX
 SG_ LS_mirrorRequestLeft m1 : 5|3@1+ (1,0) [0|7] "" Vector__XXX
 SG_ LS_mirrorRequestRight m1 : 8|3@1+ (1,0) [0|7] "" Vector__XXX
 SG_ LS_liftgateRequest m1 : 11|3@1+ (1,0) [0|7] "" Vector__XXX
 SG_ LS_windowRequestLF m1 : 16|3@1+ (1,0) [0|7] "" Vector__XXX
 SG_ LS_windowRequestLR m1 : 19|3@1+ (1,0) [0|7] "" Vector__XXX
 SG_ LS_windowRequestRF m1 : 24|3@1+ (1,0) [0|7] "" Vector__XXX
 SG_ LS_windowRequestRR m1 : 27|3@1+ (1,0) [0|7] "" Vector__XXX
 SG_ LS_presentingHandleRequestLF m1 : 32|3@1+ (1,0) [0|7] "" Vector__XXX
 SG_ LS_presentingHandleRequestLR m1 : 35|3@1+ (1,0) [0|7] "" Vector__XXX
 SG_ LS_presentingHandleRequestRF m1 : 40|3@1+ (1,0) [0|7] "" Vector__XXX
 SG_ LS_presentingHandleRequestRR m1 : 43|3@1+ (1,0) [0|7] "" Vector__XXX
 SG_ LS_powerFrontDoorRequestLeft m1 : 46|3@1+ (1,0) [0|7] "" Vector__XXX
 SG_ LS_powerFrontDoorRequestRight m1 : 49|3@1+ (1,0) [0|7] "" Vector__XXX
 SG_ LS_falconDoorRequestLeft m1 : 52|3@1+ (1,0) [0|7] "" Vector__XXX
 SG_ LS_falconDoorRequestRight m1 : 55|3@1+ (1,0) [0|7] "" Vector__XXX
 SG_ LS_chargePortRequest m1 : 58|2@1+ (1,0) [0|2] "" Vector__XXX
 SG_ LS_chargePortRaveRequest m1 : 60|1@1+ (1,0) [0|1] "" Vector__XXX
 SG_ LS_suspensionRequest m1 : 61|2@1+ (1,0) [0|2] "" Vector__XXX
 SG_ LS_rgbIPFLRed m2 : 8|8@1+ (1,0) [0|255] "" Vector__XXX
 SG_ LS_rgbIPFLGreen m2 : 16|8@1+ (1,0) [0|255] "" Vector__XXX
 SG_ LS_rgbIPFLBlue m2 : 24|8@1+ (1,0) [0|255] "" Vector__XXX
 SG_ LS_rgbIPFRRed m2 : 32|8@1+ (1,0) [0|255] "" Vector__XXX
 SG_ LS_rgbIPFRGreen m2 : 40|8@1+ (1,0) [0|255] "" Vector__XXX
 SG_ LS_rgbIPFRBlue m2 : 48|8@1+ (1,0) [0|255] "" Vector__XXX
 SG_ LS_rgbDoorFLForeRed m3 : 8|8@1+ (1,0) [0|255] "" Vector__XXX
 SG_ LS_rgbDoorFLForeGreen m3 : 16|8@1+ (1,0) [0|255] "" Vector__XXX
 SG_ LS_rgbDoorFLForeBlue m3 : 24|8@1+ (1,0) [0|255] "" Vector__XXX
 SG_ LS_rgbDoorFLAftRed m3 : 32|8@1+ (1,0) [0|255] "" Vector__XXX
 SG_ LS_rgbDoorFLAftGreen m3 : 40|8@1+ (1,0) [0|255] "" Vector__XXX
 SG_ LS_rgbDoorFLAftBlue m3 : 48|8@1+ (1,0) [0|255] "" Vector__XXX
 SG_ LS_rgbDoorFRForeRed m4 : 8|8@1+ (1,0) [0|255] "" Vector__XXX
 SG_ LS_rgbDoorFRForeGreen m4 : 16|8@1+ (1,0) [0|255] "" Vector__XXX
 SG_ LS_rgbDoorFRForeBlue m4 : 24|8@1+ (1,0) [0|255] "" Vector__XXX
 SG_ LS_rgbDoorFRAftRed m4 : 32|8@1+ (1,0) [0|255] "" Vector__XXX
 SG_ LS_rgbDoorFRAftGreen m4 : 40|8@1+ (1,0) [0|255] "" Vector__XXX
 SG_ LS_rgbDoorFRAftBlue m4 : 48|8@1+ (1,0) [0|255] "" Vector__XXX
 SG_ LS_rgbDoorRLForeRed m5 : 8|8@1+ (1,0) [0|255] "" Vector__XXX
 SG_ LS_rgbDoorRLForeGreen m5 : 16|8@1+ (1,0) [0|255] "" Vector__XXX
 SG_ LS_rgbDoorRLForeBlue m5 : 24|8@1+ (1,0) [0|255] "" Vector__XXX
 SG_ LS_rgbDoorRLAftRed m5 : 32|8@1+ (1,0) [0|255] "" Vector__XXX
 SG_ LS_rgbDoorRLAftGreen m5 : 40|8@1+ (1,0) [0|255] "" Vector__XXX
 SG_ LS_rgbDoorRLAftBlue m5 : 48|8@1+ (1,0) [0|255] "" Vector__XXX
 SG_ LS_rgbDoorRRForeRed m6 : 8|8@1+ (1,0) [0|255] "" Vector__XXX
 SG_ LS_rgbDoorRRForeGreen m6 : 16|8@1+ (1,0) [0|255] "" Vector__XXX
 SG_ LS_rgbDoorRRForeBlue m6 : 24|8@1+ (1,0) [0|255] "" Vector__XXX
 SG_ LS_rgbDoorRRAftRed m6 : 32|8@1+ (1,0) [0|255] "" Vector__XXX
 SG_ LS_rgbDoorRRAftGreen m6 : 40|8@1+ (1,0) [0|255] "" Vector__XXX
 SG_ LS_rgbDoorRRAftBlue m6 : 48|8@1+ (1,0) [0|255] "" Vector__XXX
 SG_ LS_frontMatrix0 m7 : 8|8@1+ (1,0) [0|255] "" Vector__XXX
 SG_ LS_frontMatrix1 m7 : 16|8@1+ (1,0) [0|255] "" Vector__XXX
 SG_ LS_frontMatrix2 m7 : 24|8@1+ (1,0) [0|255] "" Vector__XXX
 SG_ LS_frontMatrix3 m7 : 32|8@1+ (1,0) [0|255] "" Vector__XXX
 SG_ LS_frontMatrix4 m7 : 40|8@1+ (1,0) [0|255] "" Vector__XXX
 SG_ LS_frontMatrix5 m7 : 48|8@1+ (1,0) [0|255] "" Vector__XXX
 SG_ LS_frontMatrix6 m7 : 56|8@1+ (1,0) [0|255] "" Vector__XXX
 SG_ LS_frontMatrix7 m8 : 8|8@1+ (1,0) [0|255] "" Vector__XXX
 SG_ LS_frontMatrix8 m8 : 16|8@1+ (1,0) [0|255] "" Vector__XXX
 SG_ LS_frontMatrix9 m8 : 24|8@1+ (1,0) [0|255] "" Vector__XXX
 SG_ LS_frontMatrix10 m8 : 32|8@1+ (1,0) [0|255] "" Vector__XXX
 SG_ LS_frontMatrix11 m8 : 40|8@1+ (1,0) [0|255] "" Vector__XXX
 SG_ LS_frontMatrix12 m8 : 48|8@1+ (1,0) [0|255] "" Vector__XXX
 SG_ LS_frontMatrix13 m8 : 56|8@1+ (1,0) [0|255] "" Vector__XXX
 SG_ LS_frontMatrix14 m9 : 8|8@1+ (1,0) [0|255] "" Vector__XXX
 SG_ LS_frontMatrix15 m9 : 16|8@1+ (1,0) [0|255] "" Vector__XXX
 SG_ LS_frontMatrix16 m9 : 24|8@1+ (1,0) [0|255] "" Vector__XXX
 SG_ LS_frontMatrix17 m9 : 32|8@1+ (1,0) [0|255] "" Vector__XXX
 SG_ LS_frontMatrix18 m9 : 40|8@1+ (1,0) [0|255] "" Vector__XXX
 SG_ LS_frontMatrix19 m9 : 48|8@1+ (1,0) [0|255] "" Vector__XXX
 SG_ LS_frontMatrix20 m9 : 56|8@1+ (1,0) [0|255] "" Vector__XXX
 SG_ LS_frontMatrix21 m10 : 8|8@1+ (1,0) [0|255] "" Vector__XXX
 SG_ LS_frontMatrix22 m10 : 16|8@1+ (1,0) [0|255] "" Vector__XXX
 SG_ LS_frontMatrix23 m10 : 24|8@1+ (1,0) [0|255] "" Vector__XXX
 SG_ LS_frontMatrix24 m10 : 32|8@1+ (1,0) [0|255] "" Vector__XXX
 SG_ LS_frontMatrix25 m10 : 40|8@1+ (1,0) [0|255] "" Vector__XXX
 SG_ LS_frontMatrix26 m10 : 48|8@1+ (1,0) [0|255] "" Vector__XXX
 SG_ LS_frontMatrix27 m10 : 56|8@1+ (1,0) [0|255] "" Vector__XXX
 SG_ LS_frontMatrix28 m11 : 8|8@1+ (1,0) [0|255] "" Vector__XXX
 SG_ LS_frontMatrix29 m11 : 16|8@1+ (1,0) [0|255] "" Vector__XXX
 SG_ LS_frontMatrix30 m11 : 24|8@1+ (1,0) [0|255] "" Vector__XXX
 SG_ LS_frontMatrix31 m11 : 32|8@1+ (1,0) [0|255] "" Vector__XXX
 SG_ LS_frontMatrix32 m11 : 40|8@1+ (1,0) [0|255] "" Vector__XXX
 SG_ LS_frontMatrix33 m11 : 48|8@1+ (1,0) [0|255] "" Vector__XXX
 SG_ LS_frontMatrix34 m11 : 56|8@1+ (1,0) [0|255] "" Vector__XXX
 SG_ LS_frontMatrix35 m12 : 8|8@1+ (1,0) [0|255] "" Vector__XXX
 SG_ LS_frontMatrix36 m12 : 16|8@1+ (1,0) [0|255] "" Vector__XXX
 SG_ LS_frontMatrix37 m12 : 24|8@1+ (1,0) [0|255] "" Vector__XXX
 SG_ LS_frontMatrix38 m12 : 32|8@1+ (1,0) [0|255] "" Vector__XXX
 SG_ LS_frontMatrix39 m12 : 40|8@1+ (1,0) [0|255] "" Vector__XXX
 SG_ LS_frontMatrix40 m12 : 48|8@1+ (1,0) [0|255] "" Vector__XXX
 SG_ LS_frontMatrix41 m12 : 56|8@1+ (1,0) [0|255] "" Vector__XXX
 SG_ LS_frontMatrix42 m13 : 8|8@1+ (1,0) [0|255] "" Vector__XXX
 SG_ LS_frontMatrix43 m13 : 16|8@1+ (1,0) [0|255] "" Vector__XXX
 SG_ LS_frontMatrix44 m13 : 24|8@1+ (1,0) [0|255] "" Vector__XXX
 SG_ LS_frontMatrix45 m13 : 32|8@1+ (1,0) [0|255] "" Vector__XXX
 SG_ LS_frontMatrix46 m13 : 40|8@1+ (1,0) [0|255] "" Vector__XXX
 SG_ LS_frontMatrix47 m13 : 48|8@1+ (1,0) [0|255] "" Vector__XXX
 SG_ LS_frontMatrix48 m13 : 56|8@1+ (1,0) [0|255] "" Vector__XXX
 SG_ LS_frontMatrix49 m14 : 8|8@1+ (1,0) [0|255] "" Vector__XXX
 SG_ LS_frontMatrix50 m14 : 16|8@1+ (1,0) [0|255] "" Vector__XXX
 SG_ LS_frontMatrix51 m14 : 24|8@1+ (1,0) [0|255] "" Vector__XXX
 SG_ LS_frontMatrix52 m14 : 32|8@1+ (1,0) [0|255] "" Vector__XXX
 SG_ LS_frontMatrix53 m14 : 40|8@1+ (1,0) [0|255] "" Vector__XXX
 SG_ LS_frontMatrix54 m14 : 48|8@1+ (1,0) [0|255] "" Vector__XXX
 SG_ LS_frontMatrix55 m14 : 56|8@1+ (1,0) [0|255] "" Vector__XXX
 SG_ LS_frontMatrix56 m15 : 8|8@1+ (1,0) [0|255] "" Vector__XXX
 SG_ LS_frontMatrix57 m15 : 16|8@1+ (1,0) [0|255] "" Vector__XXX
 SG_ LS_frontMatrix58 m15 : 24|8@1+ (1,0) [0|255] "" Vector__XXX
 SG_ LS_frontMatrix59 m15 : 32|8@1+ (1,0) [0|255] "" Vector__XXX
 SG_ LS_rearMatrix0 m15 : 40|8@1+ (1,0) [0|255] "" Vector__XXX
 SG_ LS_rearMatrix1 m15 : 48|8@1+ (1,0) [0|255] "" Vector__XXX
 SG_ LS_rearMatrix2 m15 : 56|8@1+ (1,0) [0|255] "" Vector__XXX
 SG_ LS_rearMatrix3 m16 : 8|8@1+ (1,0) [0|255] "" Vector__XXX
 SG_ LS_rearMatrix4 m16 : 16|8@1+ (1,0) [0|255] "" Vector__XXX
 SG_ LS_rearMatrix5 m16 : 24|8@1+ (1,0) [0|255] "" Vector__XXX
 SG_ LS_rearMatrix6 m16 : 32|8@1+ (1,0) [0|255] "" Vector__XXX
 SG_ LS_rearMatrix7 m16 : 40|8@1+ (1,0) [0|255] "" Vector__XXX
 SG_ LS_rearMatrix8 m16 : 48|8@1+ (1,0) [0|255] "" Vector__XXX
 SG_ LS_rearMatrix9 m16 : 56|8@1+ (1,0) [0|255] "" Vector__XXX
 SG_ LS_rearMatrix10 m17 : 8|8@1+ (1,0) [0|255] "" Vector__XXX
 SG_ LS_rearMatrix11 m17 : 16|8@1+ (1,0) [0|255] "" Vector__XXX
 SG_ LS_rearMatrix12 m17 : 24|8@1+ (1,0) [0|255] "" Vector__XXX
 SG_ LS_rearMatrix13 m17 : 32|8@1+ (1,0) [0|255] "" Vector__XXX
 SG_ LS_rearMatrix14 m17 : 40|8@1+ (1,0) [0|255] "" Vector__XXX
 SG_ LS_rearMatrix15 m17 : 48|8@1+ (1,0) [0|255] "" Vector__XXX
 SG_ LS_rearMatrix16 m17 : 56|8@1+ (1,0) [0|255] "" Vector__XXX
 SG_ LS_rearMatrix17 m18 : 8|8@1+ (1,0) [0|255] "" Vector__XXX
 SG_ LS_rearMatrix18 m18 : 16|8@1+ (1,0) [0|255] "" Vector__XXX
 SG_ LS_rearMatrix19 m18 : 24|8@1+ (1,0) [0|255] "" Vector__XXX
 SG_ LS_rearMatrix20 m18 : 32|8@1+ (1,0) [0|255] "" Vector__XXX
 SG_ LS_rearMatrix21 m18 : 40|8@1+ (1,0) [0|255] "" Vector__XXX
 SG_ LS_rearMatrix22 m18 : 48|8@1+ (1,0) [0|255] "" Vector__XXX
 SG_ LS_rearMatrix23 m18 : 56|8@1+ (1,0) [0|255] "" Vector__XXX
 SG_ LS_rearMatrix24 m19 : 8|8@1+ (1,0) [0|255] "" Vector__XXX
 SG_ LS_rearMatrix25 m19 : 16|8@1+ (1,0) [0|255] "" Vector__XXX
 SG_ LS_rearMatrix26 m19 : 24|8@1+ (1,0) [0|255] "" Vector__XXX
 SG_ LS_rearMatrix27 m19 : 32|8@1+ (1,0) [0|255] "" Vector__XXX
 SG_ LS_rearMatrix28 m19 : 40|8@1+ (1,0) [0|255] "" Vector__XXX
 SG_ LS_rearMatrix29 m19 : 48|8@1+ (1,0) [0|255] "" Vector__XXX
 SG_ LS_rearMatrix30 m19 : 56|8@1+ (1,0) [0|255] "" Vector__XXX
 SG_ LS_rearMatrix31 m20 : 8|8@1+ (1,0) [0|255] "" Vector__XXX
 SG_ LS_rearMatrix32 m20 : 16|8@1+ (1,0) [0|255] "" Vector__XXX
 SG_ LS_rearMatrix33 m20 : 24|8@1+ (1,0) [0|255] "" Vector__XXX
 SG_ LS_rearMatrix34 m20 : 32|8@1+ (1,0) [0|255] "" Vector__XXX
 SG_ LS_rearMatrix35 m20 : 40|8@1+ (1,0) [0|255] "" Vector__XXX
 SG_ LS_rearMatrix36 m20 : 48|8@1+ (1,0) [0|255] "" Vector__XXX
 SG_ LS_rearMatrix37 m20 : 56|8@1+ (1,0) [0|255] "" Vector__XXX
 SG_ LS_rearMatrix38 m21 : 8|8@1+ (1,0) [0|255] "" Vector__XXX
 SG_ LS_rearMatrix39 m21 : 16|8@1+ (1,0) [0|255] "" Vector__XXX
 SG_ LS_rearMatrix40 m21 : 24|8@1+ (1,0) [0|255] "" Vector__XXX
 SG_ LS_rearMatrix41 m21 : 32|8@1+ (1,0) [0|255] "" Vector__XXX
 SG_ LS_rearMatrix42 m21 : 40|8@1+ (1,0) [0|255] "" Vector__XXX
 SG_ LS_rearMatrix43 m21 : 48|8@1+ (1,0) [0|255] "" Vector__XXX
 SG_ LS_rearMatrix44 m21 : 56|8@1+ (1,0) [0|255] "" Vector__XXX
 SG_ LS_rearMatrix45 m22 : 8|8@1+ (1,0) [0|255] "" Vector__XXX
 SG_ LS_rearMatrix46 m22 : 16|8@1+ (1,0) [0|255] "" Vector__XXX
 SG_ LS_rearMatrix47 m22 : 24|8@1+ (1,0) [0|255] "" Vector__XXX
 SG_ LS_rearMatrix48 m22 : 32|8@1+ (1,0) [0|255] "" Vector__XXX
 SG_ LS_rearMatrix49 m22 : 40|8@1+ (1,0) [0|255] "" Vector__XXX
 SG_ LS_rearMatrix50 m22 : 48|8@1+ (1,0) [0|255] "" Vector__XXX
 SG_ LS_rearMatrix51 m22 : 56|8@1+ (1,0) [0|255] "" Vector__XXX
 SG_ LS_rearMatrix52 m23 : 8|8@1+ (1,0) [0|255] "" Vector__XXX
 SG_ LS_rearMatrix53 m23 : 16|8@1+ (1,0) [0|255] "" Vector__XXX
 SG_ LS_rearMatrix54 m23 : 24|8@1+ (1,0) [0|255] "" Vector__XXX
 SG_ LS_rearMatrix55 m23 : 32|8@1+ (1,0) [0|255] "" Vector__XXX
 SG_ LS_rearMatrix56 m23 : 40|8@1+ (1,0) [0|255] "" Vector__XXX
 SG_ LS_rearMatrix57 m23 : 48|8@1+ (1,0) [0|255] "" Vector__XXX
 SG_ LS_rearMatrix58 m23 : 56|8@1+ (1,0) [0|255] "" Vector__XXX
 SG_ LS_rearMatrix59 m24 : 8|8@1+ (1,0) [0|255] "" Vector__XXX
 SG_ LS_offroadLightBar0 m24 : 16|8@1+ (1,0) [0|255] "" Vector__XXX
 SG_ LS_offroadLightBar1 m24 : 24|8@1+ (1,0) [0|255] "" Vector__XXX
 SG_ LS_offroadLightBar2 m24 : 32|8@1+ (1,0) [0|255] "" Vector__XXX
 SG_ LS_offroadLightBar3 m24 : 40|8@1+ (1,0) [0|255] "" Vector__XXX
 SG_ LS_offroadLightBar4 m24 : 48|8@1+ (1,0) [0|255] "" Vector__XXX
 SG_ LS_offroadLightBar5 m24 : 56|8@1+ (1,0) [0|255] "" Vector__XXX

BO_ 740 PCS2_logging: 8 PCS2
 SG_ PCS2_logMessageSelect M : 0|8@1+ (1,0) [0|255] "" Vector__XXX
 SG_ PCS2_dcdcUsingInternalDefLvTarge m1 : 8|1@1+ (1,0) [0|1] "" Vector__XXX
 SG_ PCS2_dcdcAStateMachineState m1 : 9|3@1+ (1,0) [0|7] "" Vector__XXX
 SG_ PCS2_dcdcBStateMachineState m1 : 12|3@1+ (1,0) [0|7] "" Vector__XXX
 SG_ PCS2_dcdcAStageModeRequest m1 : 16|2@1+ (1,0) [0|3] "" Vector__XXX
 SG_ PCS2_dcdcBStageModeRequest m1 : 18|2@1+ (1,0) [0|3] "" Vector__XXX
 SG_ PCS2_dcdcAHvCurrentCommand m2 : 8|13@1- (0.01,0) [-30|30] "A" Vector__XXX
 SG_ PCS2_dcdcALvCurrentCommand m2 : 24|13@1- (0.1,0) [-409|409] "A" Vector__XXX
 SG_ PCS2_dcdcAPowerLimit m2 : 37|12@1+ (1,0) [0|4095] "W" Vector__XXX
 SG_ PCS2_dcdcALvCurrentEstimated m2 : 49|13@1- (0.1,0) [-400|400] "A" Vector__XXX
 SG_ PCS2_dcdcLvBusVoltageFiltered m3 : 8|13@1+ (0.01,0) [0|81.9] "V" Vector__XXX
 SG_ PCS2_dcdcALifetimekWh m10 : 8|24@1+ (0.01,0) [0|167772.14] "kWh" Vector__XXX
 SG_ PCS2_dcdcBHvCurrentCommand m65 : 8|13@1- (0.01,0) [-30|30] "A" Vector__XXX
 SG_ PCS2_dcdcBLvCurrentCommand m65 : 24|13@1- (0.1,0) [-409|409] "A" Vector__XXX
 SG_ PCS2_dcdcBPowerLimit m65 : 37|12@1+ (1,0) [0|4095] "W" Vector__XXX
 SG_ PCS2_dcdcBLvCurrentEstimated m65 : 49|13@1- (0.1,0) [-400|400] "A" Vector__XXX
 SG_ PCS2_dcdcBLifetimekWh m71 : 8|24@1+ (0.01,0) [0|167772.14] "kWh" Vector__XXX
 SG_ PCS2_dcdcA_lv2Temp m88 : 8|11@1- (0.15,70.05) [-60|200] "C" Vector__XXX
 SG_ PCS2_dcdcA_lv2TempIrrational m88 : 19|1@1+ (1,0) [0|1] "" Vector__XXX
 SG_ PCS2_dcdcB_lv2Temp m88 : 20|11@1- (0.15,70.05) [-60|200] "C" Vector__XXX
 SG_ PCS2_dcdcB_lv2TempIrrational m88 : 31|1@1+ (1,0) [0|1] "" Vector__XXX
 SG_ PCS2_dcdcA_hvTemp m88 : 32|11@1- (0.15,70.05) [-60|200] "C" Vector__XXX
 SG_ PCS2_dcdcA_hvTempIrrational m88 : 43|1@1+ (1,0) [0|1] "" Vector__XXX
 SG_ PCS2_dcdcB_hvTemp m88 : 44|11@1- (0.15,70.05) [-60|200] "C" Vector__XXX
 SG_ PCS2_dcdcB_hvTempIrrational m88 : 55|1@1+ (1,0) [0|1] "" Vector__XXX
 SG_ PCS2_acChargeLifetimekVAh m151 : 8|24@1+ (0.01,0) [0|167772.14] "kVAh" Vector__XXX
 SG_ PCS2_v2xGridFormLifetimekVAh m151 : 32|24@1+ (0.01,0) [0|167772.14] "kVAh" Vector__XXX
 SG_ PCS2_cabinOnlyL2L3LifetimekVAh m152 : 8|24@1+ (0.01,0) [0|167772.14] "kVAh" Vector__XXX
 SG_ PCS2_totalOutletLifetimekVAh m152 : 32|24@1+ (0.01,0) [0|167772.14] "kVAh" Vector__XXX
 SG_ PCS2_cabinAndBedL1L2LifetimekVAh m153 : 8|24@1+ (0.01,0) [0|167772.14] "kVAh" Vector__XXX
 SG_ PCS2_cabinAndBedL2L3LifetimekVAh m153 : 32|24@1+ (0.01,0) [0|167772.14] "kVAh" Vector__XXX

BO_ 1039 PCS2_v2xInfo2: 4 PCS2
 SG_ PCS2_v2xUserPower : 0|10@1- (0.05,0) [-20|20] "kW" Vector__XXX
 SG_ PCS2_v2xDispatchableApparentPowe : 10|9@1+ (0.05,0) [0|20] "kVA" Vector__XXX
 SG_ PCS2_v2xReadyApparentPower : 19|9@1+ (0.05,0) [0|20] "kVA" Vector__XXX

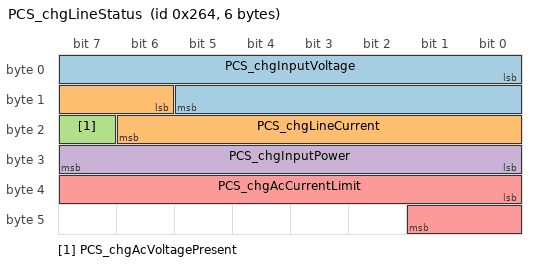
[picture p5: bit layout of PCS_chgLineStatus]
BO_ 612 PCS_chgLineStatus: 6 PCS
 SG_ PCS_chgInputVoltage : 0|14@1+ (0.033,0) [0|540.639] "V" Vector__XXX
 SG_ PCS_chgLineCurrent : 14|9@1+ (0.1,0) [0|50] "A" Vector__XXX
 SG_ PCS_chgAcVoltagePresent : 23|1@1+ (1,0) [0|1] "" Vector__XXX
 SG_ PCS_chgInputPower : 24|8@1+ (0.1,0) [0|20] "kW" Vector__XXX
 SG_ PCS_chgAcCurrentLimit : 32|10@1+ (0.1,0) [0|102.3] "A" Vector__XXX

BO_ 516 PCS_chgStatus: 8 PCS
 SG_ PCS_chgMainState : 0|4@1+ (1,0) [0|15] "" Vector__XXX
 SG_ PCS_powerTransferStatus : 4|2@1+ (1,0) [0|3] "" Vector__XXX
 SG_ PCS_gridConfig : 6|2@1+ (1,0) [1|3] "" Vector__XXX
 SG_ PCS_chgPHAEnable : 8|1@1+ (1,0) [0|1] "" Vector__XXX
 SG_ PCS_chgPHBEnable : 9|1@1+ (1,0) [0|1] "" Vector__XXX
 SG_ PCS_hvInletConductorEnergizedAc : 10|1@1+ (1,0) [0|1] "" Vector__XXX
 SG_ PCS_chgHighPowerActive : 11|1@1+ (1,0) [0|1] "" Vector__XXX
 SG_ PCS_chgPHCEnable : 12|1@1+ (1,0) [0|1] "" Vector__XXX
 SG_ PCS_chgInstantAcPowerAvailable : 16|8@1+ (0.1,0) [0|20] "kW" Vector__XXX
 SG_ PCS_chgMaxAcPowerAvailable : 24|8@1+ (0.1,0) [0|20] "kW" Vector__XXX
 SG_ PCS_chgPHALineCurrentRequest : 32|8@1+ (0.1,0) [0|20] "A" Vector__XXX
 SG_ PCS_chgPHBLineCurrentRequest : 40|8@1+ (0.1,0) [0|20] "A" Vector__XXX
 SG_ PCS_chgPHCLineCurrentRequest : 48|8@1+ (0.1,0) [0|20] "A" Vector__XXX
 SG_ PCS_chgPwmEnableLine : 56|1@1+ (1,0) [0|1] "" Vector__XXX
 SG_ PCS_powerTransferShutdownRequest : 57|2@1+ (1,0) [0|3] "" Vector__XXX
 SG_ PCS_hwVariantType : 59|2@1+ (1,0) [0|2] "" Vector__XXX
 SG_ PCS_dcacBidirectionalAllowed : 61|1@1+ (1,0) [0|1] "" Vector__XXX

BO_TX_BU_ 680 : EPBL;
BO_TX_BU_ 2024 : EPBR;
BO_TX_BU_ 552 : EPBR;
BO_TX_BU_ 742 : EPBR;
BO_TX_BU_ 744 : EPBR;
BO_TX_BU_ 1662 : EVSE;
BO_TX_BU_ 1117 : FC;
BO_TX_BU_ 1334 : FC;
BO_TX_BU_ 1303 : FC;
BO_TX_BU_ 1310 : FC;
BO_TX_BU_ 580 : FC;
BO_TX_BU_ 702 : FC;
BO_TX_BU_ 1345 : FC;
BO_TX_BU_ 1300 : FC;
BO_TX_BU_ 532 : FC;
BO_TX_BU_ 533 : FC;
BO_TX_BU_ 535 : FC;
BO_TX_BU_ 1650 : HCML;
BO_TX_BU_ 1980 : HCMR;
BO_TX_BU_ 522 : HVP;
BO_TX_BU_ 1962 : HVP;
BO_TX_BU_ 554 : HVP;
BO_TX_BU_ 784 : HVP;
BO_TX_BU_ 1914 : HVP;
BO_TX_BU_ 941 : ICR;
BO_TX_BU_ 667 : ICR;
BO_TX_BU_ 536 : ICR;
BO_TX_BU_ 670 : ICR;
BO_TX_BU_ 664 : ICR;
BO_TX_BU_ 1012 : GTW;
BO_TX_BU_ 740 : PCS2;
BO_TX_BU_ 1039 : PCS2;
BO_TX_BU_ 612 : PCS;
BO_TX_BU_ 516 : PCS;
CM_ BO_ 680 "Left electric parking brake message: status";
CM_ SG_ 680 EPBL_systemStatus "Coordinated state representing the vehicle level parking brake state.";
CM_ SG_ 680 EPBL_freeRollModeStatus "Left electric parking brake: free roll mode status";
CM_ SG_ 680 EPBL_driverIsLeaving "Left electric parking brake: driver is leaving";
CM_ SG_ 680 EPBL_driverIsLeavingAnySpeed "Left electric parking brake: driver is leaving any speed";
CM_ SG_ 680 EPBL_systemCdpAvailable "Left electric parking brake: system cdp available";
CM_ SG_ 680 EPBL_chimeRequest "Left electric parking brake: chime request";
CM_ SG_ 680 EPBL_telltale "Controls the telltale illumination on the instrument cluster.; raw 7 = signal not available (SNA)";
CM_ SG_ 680 EPBL_contactorCycleNotNeededForW "Left electric parking brake: contactor cycle not needed for winch entry";
CM_ SG_ 680 EPBL_redundantBrakingEnabled "Left electric parking brake: redundant braking enabled";
CM_ SG_ 680 EPBL_summonEnabled "Left electric parking brake: summon enabled";
CM_ SG_ 680 EPBL_brakeLight "Left electric parking brake: brake light";
CM_ SG_ 680 EPBL_epbConfigMismatch "Left electric parking brake: epb config mismatch";
CM_ SG_ 680 EPBL_brakeConfirmedPressed "Left electric parking brake: brake confirmed pressed";
CM_ SG_ 680 EPBL_requestUserConfirmation "Left electric parking brake: request user confirmation";
CM_ SG_ 680 EPBL_uiWinchModeMiscBlocking "Reports the expected appearance of system error message on User Interface (UI) winch mode panel.";
CM_ SG_ 680 EPBL_winchModeActive "Left electric parking brake: winch mode active";
CM_ SG_ 680 EPBL_updateMode "Left electric parking brake: update mode";
CM_ SG_ 680 EPBL_winchModePermissive "Left electric parking brake: winch mode permissive";
CM_ SG_ 680 EPBL_winchModePending "Left electric parking brake: winch mode pending";
CM_ SG_ 680 EPBL_cdpRequest "Left electric parking brake: cdp request";
CM_ SG_ 680 EPBL_uiParkAvailable "Reports the expected availability and appearance of the park button on User Interface (UI) safety panel.";
CM_ SG_ 680 EPBL_brakeDiscWipeRequest "Left electric parking brake: brake disc wipe request; raw 3 = signal not available (SNA)";
CM_ SG_ 680 EPBL_showUiGearShifter "Left electric parking brake: show ui gear shifter";
CM_ SG_ 680 EPBL_uiWinchModeLvStatus "Reports the expected availability and appearance of Low Voltage (LV) system status on UI winch mode panel.";
CM_ SG_ 680 EPBL_autonomyBehavior "Left electric parking brake: autonomy behavior";
CM_ SG_ 680 EPBL_showStalkFaultedOnUi "Left electric parking brake: show stalk faulted on ui";
CM_ SG_ 680 EPBL_espPowerRequest "Left electric parking brake: esp power request";
CM_ SG_ 680 EPBL_okToPark "Left electric parking brake: ok to park";
CM_ SG_ 680 EPBL_hornRequest "Left electric parking brake: horn request";
CM_ SG_ 680 EPBL_winchModeAvailable "Left electric parking brake: winch mode available";
CM_ SG_ 680 EPBL_bothDisconnected "Left electric parking brake: both disconnected";
CM_ SG_ 680 EPBL_blockDrive "Left electric parking brake: block drive";
CM_ SG_ 680 EPBL_statusCounter "Left electric parking brake: status counter";
CM_ SG_ 680 EPBL_statusChecksum "Left electric parking brake: status checksum";
CM_ BO_ 2024 "Right electric parking brake message: info";
CM_ SG_ 2024 EPBR_infoIndex "Right electric parking brake: info index";
CM_ SG_ 2024 EPBR_infoBuildType "Right electric parking brake: info build type";
CM_ SG_ 2024 EPBR_infoBuildConfigId "Right electric parking brake: info build config id";
CM_ SG_ 2024 EPBR_infoHardwareId "Right electric parking brake: info hardware id";
CM_ SG_ 2024 EPBR_infoComponentId "Right electric parking brake: info component id";
CM_ SG_ 2024 EPBR_infoPcbaId "Right electric parking brake: info pcba id";
CM_ SG_ 2024 EPBR_infoAssemblyId "Right electric parking brake: info assembly id; raw 255 = signal not available (SNA)";
CM_ SG_ 2024 EPBR_infoUsageId "Right electric parking brake: info usage id";
CM_ SG_ 2024 EPBR_infoSubUsageId "Right electric parking brake: info sub usage id";
CM_ SG_ 2024 EPBR_infoAppCrc "Right electric parking brake: info app crc";
CM_ SG_ 2024 EPBR_infoAppGitHash "Right electric parking brake: info app git hash";
CM_ SG_ 2024 EPBR_infoBootGitHash "Right electric parking brake: info boot git hash";
CM_ SG_ 2024 EPBR_infoPlatformType "Right electric parking brake: info platform type";
CM_ SG_ 2024 EPBR_infoBootUdsProtoVersion "Right electric parking brake: info boot uds proto version";
CM_ SG_ 2024 EPBR_infoBootCrc "Right electric parking brake: info boot crc";
CM_ BO_ 552 "Right electric parking brake message: internal status";
CM_ SG_ 552 EPBR_unitStatus "Electronic Parking Brake's unit state.";
CM_ SG_ 552 EPBR_unitFaultStatus "Right electric parking brake: unit fault status";
CM_ SG_ 552 EPBR_summonState "Right electric parking brake: summon state";
CM_ SG_ 552 EPBR_disconnected "Right electric parking brake: disconnected";
CM_ SG_ 552 EPBR_pistonTouchingRotor "Right electric parking brake: piston touching rotor";
CM_ SG_ 552 EPBR_csmFaultReason "Right electric parking brake: csm fault reason";
CM_ SG_ 552 EPBR_esmOperationTrigger "Right electric parking brake: esm operation trigger";
CM_ SG_ 552 EPBR_summonFaultReason "Error code associated with previous summon failure.";
CM_ SG_ 552 EPBR_localServiceModeActive "Signal reported by Right electric parking brake";
CM_ SG_ 552 EPBR_localCdpState "Right electric parking brake: local cdp state";
CM_ SG_ 552 EPBR_chimeRequestLocal "Right electric parking brake: chime request local";
CM_ SG_ 552 EPBR_telltaleLocal "Right electric parking brake: telltale local; raw 7 = signal not available (SNA)";
CM_ SG_ 552 EPBR_driverIsLeavingLocal "Right electric parking brake: driver is leaving local";
CM_ SG_ 552 EPBR_driverIsLeavingAnySpeedLoca "Right electric parking brake: driver is leaving any speed local";
CM_ SG_ 552 EPBR_internalCDPRequest "Right electric parking brake: internal CDP request";
CM_ SG_ 552 EPBR_esmSpeedClass "Right electric parking brake: esm speed class";
CM_ SG_ 552 EPBR_learnedEpbConfig "Right electric parking brake: learned epb config";
CM_ SG_ 552 EPBR_internalStatusCounter "Right electric parking brake: internal status counter";
CM_ SG_ 552 EPBR_internalStatusChecksum "Right electric parking brake: internal status checksum";
CM_ BO_ 742 "Right electric parking brake message: seat status3";
CM_ SG_ 742 EPBR_frontSeatCushionFanCur "Right electric parking brake: front seat cushion fan cur";
CM_ SG_ 742 EPBR_frontSeatBackrestFanCur "Right electric parking brake: front seat backrest fan cur";
CM_ SG_ 742 EPBR_frontSeatCushionFanDuty "Right electric parking brake: front seat cushion fan duty";
CM_ SG_ 742 EPBR_frontSeatCushionFanEn "Right electric parking brake: front seat cushion fan en";
CM_ SG_ 742 EPBR_frontSeatBackrestFanEn "Right electric parking brake: front seat backrest fan en";
CM_ SG_ 742 EPBR_frontSeatBackrestFanDuty "Right electric parking brake: front seat backrest fan duty";
CM_ SG_ 742 EPBR_seat2RControllerCurrent "Right electric parking brake: seat2 r controller current";
CM_ BO_ 744 "Right electric parking brake message: status";
CM_ SG_ 744 EPBR_systemStatus "Coordinated state representing the vehicle level parking brake state.";
CM_ SG_ 744 EPBR_freeRollModeStatus "Right electric parking brake: free roll mode status";
CM_ SG_ 744 EPBR_driverIsLeaving "Right electric parking brake: driver is leaving";
CM_ SG_ 744 EPBR_driverIsLeavingAnySpeed "Right electric parking brake: driver is leaving any speed";
CM_ SG_ 744 EPBR_systemCdpAvailable "Right electric parking brake: system cdp available";
CM_ SG_ 744 EPBR_chimeRequest "Right electric parking brake: chime request";
CM_ SG_ 744 EPBR_telltale "Controls the telltale illumination on the instrument cluster.; raw 7 = signal not available (SNA)";
CM_ SG_ 744 EPBR_audioCurrentSpikeDetected "Right electric parking brake: audio current spike detected";
CM_ SG_ 744 EPBR_redundantBrakingEnabled "Right electric parking brake: redundant braking enabled";
CM_ SG_ 744 EPBR_summonEnabled "Right electric parking brake: summon enabled";
CM_ SG_ 744 EPBR_brakeLight "Right electric parking brake: brake light";
CM_ SG_ 744 EPBR_epbConfigMismatch "Right electric parking brake: epb config mismatch";
CM_ SG_ 744 EPBR_brakeConfirmedPressed "Right electric parking brake: brake confirmed pressed";
CM_ SG_ 744 EPBR_requestUserConfirmation "Right electric parking brake: request user confirmation";
CM_ SG_ 744 EPBR_uiWinchModeMiscBlocking "Reports the expected appearance of system error message on User Interface (UI) winch mode panel.";
CM_ SG_ 744 EPBR_winchModeActive "Right electric parking brake: winch mode active";
CM_ SG_ 744 EPBR_updateMode "Right electric parking brake: update mode";
CM_ SG_ 744 EPBR_winchModePermissive "Right electric parking brake: winch mode permissive";
CM_ SG_ 744 EPBR_winchModePending "Right electric parking brake: winch mode pending";
CM_ SG_ 744 EPBR_cdpRequest "Right electric parking brake: cdp request";
CM_ SG_ 744 EPBR_uiParkAvailable "Reports the expected availability and appearance of the park button on User Interface (UI) safety panel.";
CM_ SG_ 744 EPBR_brakeDiscWipeRequest "Right electric parking brake: brake disc wipe request; raw 3 = signal not available (SNA)";
CM_ SG_ 744 EPBR_showUiGearShifter "Right electric parking brake: show ui gear shifter";
CM_ SG_ 744 EPBR_uiWinchModeLvStatus "Reports the expected availability and appearance of Low Voltage (LV) system status on UI winch mode panel.";
CM_ SG_ 744 EPBR_contactorCycleNotNeededForW "Right electric parking brake: contactor cycle not needed for winch entry";
CM_ SG_ 744 EPBR_autonomyBehavior "Right electric parking brake: autonomy behavior";
CM_ SG_ 744 EPBR_showStalkFaultedOnUi "Right electric parking brake: show stalk faulted on ui";
CM_ SG_ 744 EPBR_espPowerRequest "Right electric parking brake: esp power request";
CM_ SG_ 744 EPBR_okToPark "Right electric parking brake: ok to park";
CM_ SG_ 744 EPBR_hornRequest "Right electric parking brake: horn request";
CM_ SG_ 744 EPBR_winchModeAvailable "Right electric parking brake: winch mode available";
CM_ SG_ 744 EPBR_bothDisconnected "Right electric parking brake: both disconnected";
CM_ SG_ 744 EPBR_blockDrive "Right electric parking brake: block drive";
CM_ SG_ 744 EPBR_statusCounter "Right electric parking brake: status counter";
CM_ SG_ 744 EPBR_statusChecksum "Right electric parking brake: status checksum";
CM_ BO_ 1662 "EVSE ECU message: iso tp to veh";
CM_ SG_ 1662 EVSE_isoTpToVehData "EVSE ECU: iso tp to veh data";
CM_ BO_ 1117 "FC ECU message: evse billing";
CM_ SG_ 1117 FC_evseBillingDataSelect "FC ECU: evse billing data select";
CM_ SG_ 1117 FC_evseBillingEnergy "FC ECU: evse billing energy";
CM_ SG_ 1117 FC_evseMeterPower "FC ECU: evse meter power";
CM_ SG_ 1117 FC_evseMeterCurrent "FC ECU: evse meter current";
CM_ SG_ 1117 FC_evseMeterVoltage "FC ECU: evse meter voltage";
CM_ SG_ 1117 FC_evseMeterFwGitHash "FC ECU: evse meter fw git hash";
CM_ BO_ 1334 "FC ECU message: evse billing2";
CM_ SG_ 1334 FC_evseBilling2DataSelect "FC ECU: evse billing2 data select";
CM_ SG_ 1334 FC_evsePpuEnabled "FC ECU: evse ppu enabled";
CM_ SG_ 1334 FC_evseBillingEnergyHighRes "FC ECU: evse billing energy high res; raw 16777215 = signal not available (SNA)";
CM_ BO_ 1303 "FC ECU message: identifier";
CM_ SG_ 1303 FC_id "Fast charger identifying number";
CM_ SG_ 1303 FC_sessionId "Fast charge session ID";
CM_ BO_ 1310 "FC ECU message: info";
CM_ SG_ 1310 FC_infoIndex "FC ECU: info index";
CM_ SG_ 1310 FC_infoBuildType "FC ECU: info build type";
CM_ SG_ 1310 FC_infoBuildConfigID "FC ECU: info build config ID";
CM_ SG_ 1310 FC_infoHardwareID "FC ECU: info hardware ID";
CM_ SG_ 1310 FC_infoComponentID "FC ECU: info component ID";
CM_ SG_ 1310 FC_infoPcbaID "FC ECU: info pcba ID";
CM_ SG_ 1310 FC_infoAssemblyID "FC ECU: info assembly ID";
CM_ SG_ 1310 FC_infoUsageID "FC ECU: info usage ID";
CM_ SG_ 1310 FC_infoSubUsageID "FC ECU: info sub usage ID";
CM_ SG_ 1310 FC_infoApplicationCRC "FC ECU: info application CRC";
CM_ SG_ 1310 FC_infoAppGitHashBytes "FC ECU: info app git hash bytes";
CM_ SG_ 1310 FC_infoBootGitHashBytes "FC ECU: info boot git hash bytes";
CM_ SG_ 1310 FC_infoPlatformType "FC ECU: info platform type";
CM_ SG_ 1310 FC_infoMajorVersion "Fast charger firmware major version number";
CM_ SG_ 1310 FC_infoBranchOrigin "Fast charger branch origin";
CM_ SG_ 1310 FC_infoMaturity "Fast charger firmware info";
CM_ SG_ 1310 FC_infoHardwareRevision "FC ECU: info hardware revision";
CM_ SG_ 1310 FC_partNumChar01 "FC ECU: part num char01";
CM_ SG_ 1310 FC_partNumChar02 "FC ECU: part num char02";
CM_ SG_ 1310 FC_partNumChar03 "FC ECU: part num char03";
CM_ SG_ 1310 FC_partNumChar04 "FC ECU: part num char04";
CM_ SG_ 1310 FC_partNumChar05 "FC ECU: part num char05";
CM_ SG_ 1310 FC_partNumChar06 "FC ECU: part num char06";
CM_ SG_ 1310 FC_partNumChar07 "FC ECU: part num char07";
CM_ SG_ 1310 FC_partNumChar08 "FC ECU: part num char08";
CM_ SG_ 1310 FC_partNumChar09 "FC ECU: part num char09";
CM_ SG_ 1310 FC_partNumChar10 "FC ECU: part num char10";
CM_ SG_ 1310 FC_partNumChar11 "FC ECU: part num char11";
CM_ SG_ 1310 FC_partNumChar12 "FC ECU: part num char12";
CM_ SG_ 1310 FC_partNumChar13 "FC ECU: part num char13";
CM_ SG_ 1310 FC_partNumChar14 "FC ECU: part num char14";
CM_ SG_ 1310 FC_partNumChar15 "FC ECU: part num char15";
CM_ SG_ 1310 FC_partNumChar16 "FC ECU: part num char16";
CM_ SG_ 1310 FC_partNumChar17 "FC ECU: part num char17";
CM_ SG_ 1310 FC_partNumChar18 "FC ECU: part num char18";
CM_ SG_ 1310 FC_partNumChar19 "FC ECU: part num char19";
CM_ SG_ 1310 FC_partNumChar20 "FC ECU: part num char20";
CM_ BO_ 580 "FC ECU message: limits";
CM_ SG_ 580 FC_powerLimit "Instantaneous power charger can deliver.; raw 8191 = signal not available (SNA)";
CM_ SG_ 580 FC_currentLimit "Instantaneous current charger can deliver.; raw 8191 = signal not available (SNA)";
CM_ SG_ 580 FC_maxVoltageLimit "Max voltage charger can deliver. 600/65536; raw 8191 = signal not available (SNA)";
CM_ SG_ 580 FC_minVoltageLimit "Measures Electric Vehicle Supply Equipment (EVSE) minimum current limit.; raw 8191 = signal not available (SNA)";
CM_ BO_ 702 "FC ECU message: limits high power";
CM_ SG_ 702 FC_powerLimit_value "Instantaneous power charger can deliver. Mantissa portion of extended range version of legacy signal, used with protocol versions 9+. FC_powerLimit = value * 10^exp; raw 32768 = signal not available (SNA)";
CM_ SG_ 702 FC_currentLimit_value "FC ECU: current limit value; raw 32768 = signal not available (SNA)";
CM_ SG_ 702 FC_minVoltageLimit_value "FC ECU: min voltage limit value; raw 32768 = signal not available (SNA)";
CM_ SG_ 702 FC_powerLimit_exp "Instantaneous power charger can deliver. Exponent portion of extended ragne version of legacy signal, used with protocol versions 9+. FC_powerLimit = value * 10^exp.";
CM_ SG_ 702 FC_currentLimit_exp "FC ECU: current limit exp";
CM_ SG_ 702 FC_minVoltageLimit_exp "FC ECU: min voltage limit exp";
CM_ BO_ 1345 "FC ECU message: max limits";
CM_ SG_ 1345 FC_maxPowerLimit "Max power charger can deliver.; raw 8191 = signal not available (SNA)";
CM_ SG_ 1345 FC_maxCurrentLimit "Max current charger can deliver.; raw 8191 = signal not available (SNA)";
CM_ BO_ 1300 "FC ECU message: serial";
CM_ SG_ 1300 FC_serialDataSelect "FC ECU: serial data select";
CM_ SG_ 1300 FC_serialChar01 "FC ECU: serial char01";
CM_ SG_ 1300 FC_serialChar02 "FC ECU: serial char02";
CM_ SG_ 1300 FC_serialChar03 "FC ECU: serial char03";
CM_ SG_ 1300 FC_serialChar04 "FC ECU: serial char04";
CM_ SG_ 1300 FC_serialChar05 "FC ECU: serial char05";
CM_ SG_ 1300 FC_serialChar06 "FC ECU: serial char06";
CM_ SG_ 1300 FC_serialChar07 "FC ECU: serial char07";
CM_ SG_ 1300 FC_serialChar08 "FC ECU: serial char08";
CM_ SG_ 1300 FC_serialChar09 "FC ECU: serial char09";
CM_ SG_ 1300 FC_serialChar10 "FC ECU: serial char10";
CM_ SG_ 1300 FC_serialChar11 "FC ECU: serial char11";
CM_ SG_ 1300 FC_serialChar12 "FC ECU: serial char12";
CM_ SG_ 1300 FC_serialChar13 "FC ECU: serial char13";
CM_ SG_ 1300 FC_serialChar14 "FC ECU: serial char14";
CM_ SG_ 1300 FC_serialChar15 "FC ECU: serial char15";
CM_ SG_ 1300 FC_serialChar16 "FC ECU: serial char16";
CM_ SG_ 1300 FC_serialChar17 "FC ECU: serial char17";
CM_ BO_ 532 "FC ECU message: status";
CM_ SG_ 532 FC_protocolVersion "FC ECU: protocol version";
CM_ SG_ 532 FC_statusCode "Fast charger status code; raw 0 = signal not available (SNA)";
CM_ SG_ 532 FC_deprecated1 "FC ECU: deprecated1";
CM_ SG_ 532 FC_deprecated2 "FC ECU: deprecated2";
CM_ SG_ 532 FC_deprecated3 "FC ECU: deprecated3";
CM_ SG_ 532 FC_adapterLocked "Indicates if the DC adapter is secure or not";
CM_ SG_ 532 FC_minCurrentLimit "Fast charger min current limit";
CM_ SG_ 532 FC_type "Type of EVSE connected that supports digital communication; raw 7 = signal not available (SNA)";
CM_ SG_ 532 FC_dcCurrent "Fast charger DC output current";
CM_ SG_ 532 FC_postID "Fast charger charging post ID; raw 3 = signal not available (SNA)";
CM_ SG_ 532 FC_dcVoltage "Fast charger DC voltage";
CM_ SG_ 532 FC_leakageTestNotSupported "Indicates if the S/X leakage test can be run on this supercharger";
CM_ SG_ 532 FC_dischargeSupported "FC ECU: discharge supported";
CM_ BO_ 533 "FC ECU message: status2";
CM_ SG_ 533 FC_externalIsolationResistance "Fast charger external isolation resistance; raw 255 = signal not available (SNA)";
CM_ BO_ 535 "FC ECU message: status3";
CM_ SG_ 535 FC_status3DataSelect "FC ECU: status3 data select";
CM_ SG_ 535 FC_status3DummySig "FC ECU: status3 dummy sig";
CM_ SG_ 535 FC_class "FC ECU: class; raw 0 = signal not available (SNA)";
CM_ SG_ 535 FC_brand "Fast charger brand; raw 0 = signal not available (SNA)";
CM_ SG_ 535 FC_coolingType "Type of cooling used for the supercharger; raw 0 = signal not available (SNA)";
CM_ SG_ 535 FC_uiStopType "Type of stop type supported from the UI; raw 0 = signal not available (SNA)";
CM_ SG_ 535 FC_emergencyShutdownSupported "Indicates if the supercharger supports fast emergency shutdown requests from vehicle";
CM_ SG_ 535 FC_generation "Hardware generation of the Tesla EVSE.; raw 0 = signal not available (SNA)";
CM_ BO_ 1650 "HCML ECU message: info";
CM_ SG_ 1650 VC_hcmlInfoIndex "HCML ECU: hcml info index";
CM_ SG_ 1650 VC_infoHCMLBuildConfigId "HCM Diagnostic Field.";
CM_ SG_ 1650 VC_leftHeadlampLMMVariant "Reports the detected left headlamp LED Matrix Manager (LMM) variant.; raw 0 = signal not available (SNA)";
CM_ SG_ 1650 VC_infoHCMLAssemblyId "HCM Diagnostic Field.";
CM_ SG_ 1650 VC_infoHCMLPcbaId "HCM Diagnostic Field.";
CM_ SG_ 1650 VC_infoHCMLUsageId "HCM Diagnostic Field.";
CM_ BO_ 1980 "HCMR ECU message: info";
CM_ SG_ 1980 VC_hcmrInfoIndex "HCMR ECU: hcmr info index";
CM_ SG_ 1980 VC_infoHCMRBuildConfigId "HCM Diagnostic Field.";
CM_ SG_ 1980 VC_rightHeadlampLMMVariant "Reports the detected right headlamp LED Matrix Manager (LMM) variant.; raw 0 = signal not available (SNA)";
CM_ SG_ 1980 VC_infoHCMRAssemblyId "HCM Diagnostic Field.";
CM_ SG_ 1980 VC_infoHCMRPcbaId "HCM Diagnostic Field.";
CM_ SG_ 1980 VC_infoHCMRUsageId "HCM Diagnostic Field.";
CM_ BO_ 522 "High-voltage processor (pack contactor and isolation controller) message: contactor state";
CM_ SG_ 522 HVP_packContNegativeState "High-voltage processor (pack contactor and isolation controller): pack cont negative state; raw 0 = signal not available (SNA)";
CM_ SG_ 522 HVP_packContPositiveState "Current state of positive pack contactor; raw 0 = signal not available (SNA)";
CM_ SG_ 522 HVP_fcContPositiveAuxOpen "High-voltage processor (pack contactor and isolation controller): fc cont positive aux open";
CM_ SG_ 522 HVP_fcContNegativeAuxOpen "High-voltage processor (pack contactor and isolation controller): fc cont negative aux open";
CM_ SG_ 522 HVP_packContactorSetState "The current state of the pack contactors; raw 0 = signal not available (SNA)";
CM_ SG_ 522 HVP_fcContNegativeState "Current state of the negative FC contactor; raw 0 = signal not available (SNA)";
CM_ SG_ 522 HVP_contactorsBlocked "High-voltage processor (pack contactor and isolation controller): contactors blocked";
CM_ SG_ 522 HVP_fcContPositiveState "Current state of the positive FC contactor; raw 0 = signal not available (SNA)";
CM_ SG_ 522 HVP_fcContactorSetState "The current state of the fast charge contactors; raw 0 = signal not available (SNA)";
CM_ SG_ 522 HVP_fcCtrsRequestStatus "Current status of FC contactor request";
CM_ SG_ 522 HVP_fcCtrsResetRequestRequired "High-voltage processor (pack contactor and isolation controller): fc ctrs reset request required";
CM_ SG_ 522 HVP_fcCtrsOpenNowRequested "Flag indicated immediate-opening request of FC contactors";
CM_ SG_ 522 HVP_fcCtrsOpenRequested "Flag indicating opening request of FC contactors";
CM_ SG_ 522 HVP_fcCtrsClosingAllowed "Flag indicating closure allowance of FC contactors";
CM_ SG_ 522 HVP_packCtrsRequestStatus "Current request status of pack contactors";
CM_ SG_ 522 HVP_packCtrsResetRequestRequired "High-voltage processor (pack contactor and isolation controller): pack ctrs reset request required";
CM_ SG_ 522 HVP_packCtrsOpenNowRequested "Flag indicating immediate-opening request of pack contactors";
CM_ SG_ 522 HVP_packCtrsOpenRequested "Flag indicating opening request of pack contactors";
CM_ SG_ 522 HVP_packCtrsClosingAllowed "Flag indicating closure allowance of pack contactors";
CM_ SG_ 522 HVP_dcLinkAllowedToEnergize "Indicates there should be no HV exposure if the FC link is energized by an internal or external source";
CM_ SG_ 522 HVP_pyroTestInProgress "High-voltage processor (pack contactor and isolation controller): pyro test in progress";
CM_ SG_ 522 HVP_hvilDiag "Diagnostic status of HVIL circuit, including specific FAULT types; raw 14 = signal not available (SNA)";
CM_ SG_ 522 HVP_fcLinkAllowedToEnergize "The type of charge that is allowed to energize the FC link. Indicates that the HVP has disabled the dynamic FC weld check for DC charge, or has enabled the PCS charging hardware for AC charge";
CM_ BO_ 1962 "High-voltage processor (pack contactor and isolation controller) message: debug message";
CM_ SG_ 1962 HVP_debugMessageMultiplexer "High-voltage processor (pack contactor and isolation controller): debug message multiplexer";
CM_ SG_ 1962 HVP_ecuLogUploadRequest "High-voltage processor (pack contactor and isolation controller): ecu log upload request";
CM_ SG_ 1962 HVP_dcLinkVoltage "The HVP's measurement of the DC link voltage";
CM_ SG_ 1962 HVP_packVoltage "High-voltage processor (pack contactor and isolation controller): pack voltage";
CM_ SG_ 1962 HVP_fcLinkVoltage "Measured voltage on FC link";
CM_ SG_ 1962 HVP_10HzTask_stackUsage "High-voltage processor (pack contactor and isolation controller): 10 hz task stack usage";
CM_ SG_ 1962 HVP_packContVoltage "High-voltage processor (pack contactor and isolation controller): pack cont voltage";
CM_ SG_ 1962 HVP_packNegativeV "The HVP's common-mode measurement of PACK-HV-SENSE-NEG relative to chassis ground";
CM_ SG_ 1962 HVP_packPositiveV "The HVP's common-mode measurement of PACK-HV-SENSE-POS relative to chassis ground";
CM_ SG_ 1962 HVP_pyroAnalog "High-voltage processor (pack contactor and isolation controller): pyro analog";
CM_ SG_ 1962 HVP_shuntSetTCRCoeffA "High-voltage processor (pack contactor and isolation controller): shunt set TCR coeff a";
CM_ SG_ 1962 HVP_shuntSetTCRCoeffB "High-voltage processor (pack contactor and isolation controller): shunt set TCR coeff b";
CM_ SG_ 1962 HVP_shuntSetTCRCoeffC "High-voltage processor (pack contactor and isolation controller): shunt set TCR coeff c";
CM_ SG_ 1962 HVP_shuntSetTCRCoeffD "High-voltage processor (pack contactor and isolation controller): shunt set TCR coeff d";
CM_ SG_ 1962 HVP_fcContCoilCurrent "High-voltage processor (pack contactor and isolation controller): fc cont coil current";
CM_ SG_ 1962 HVP_fcContVoltage "High-voltage processor (pack contactor and isolation controller): fc cont voltage";
CM_ SG_ 1962 HVP_hvilInVoltage "Measured HVIL input voltage";
CM_ SG_ 1962 HVP_hvilOutVoltage "Measured HVIL output voltage";
CM_ SG_ 1962 HVP_shuntGainInvalidCountDbg "High-voltage processor (pack contactor and isolation controller): shunt gain invalid count dbg";
CM_ SG_ 1962 HVP_passivePyroRefVoltageMax "High-voltage processor (pack contactor and isolation controller): passive pyro ref voltage max; raw 1023 = signal not available (SNA)";
CM_ SG_ 1962 HVP_passivePyroRefVoltageMin "High-voltage processor (pack contactor and isolation controller): passive pyro ref voltage min; raw 1023 = signal not available (SNA)";
CM_ SG_ 1962 HVP_packContCoilCurrent "High-voltage processor (pack contactor and isolation controller): pack cont coil current";
CM_ SG_ 1962 HVP_battery12V "Monitored voltage sense of 12V battery";
CM_ SG_ 1962 HVP_fcLinkPositiveV "High-voltage processor (pack contactor and isolation controller): fc link positive v";
CM_ BO_ 554 "High-voltage processor (pack contactor and isolation controller) message: hvs control";
CM_ SG_ 554 HVP_dcLinkVoltageRequest "High-voltage processor (pack contactor and isolation controller): dc link voltage request";
CM_ SG_ 554 HVP_pcsControlRequest "The operating state that the HVP would like the PCS to be in";
CM_ SG_ 554 HVP_pcsChargeHwEnabled "The state of the PCS's charge enable line";
CM_ SG_ 554 HVP_pcsDcdcHwEnabled "The state of the PCS's DCDC enable line";
CM_ SG_ 554 HVP_dcLinkVoltageFiltered "High-voltage processor (pack contactor and isolation controller): dc link voltage filtered; raw 1498 = signal not available (SNA)";
CM_ BO_ 784 "High-voltage processor (pack contactor and isolation controller) message: info";
CM_ SG_ 784 HVP_infoIndex "High-voltage processor (pack contactor and isolation controller): info index";
CM_ SG_ 784 HVP_buildType "High-voltage processor (pack contactor and isolation controller): build type";
CM_ SG_ 784 HVP_buildConfigId "High-voltage processor (pack contactor and isolation controller): build config id";
CM_ SG_ 784 HVP_hardwareId "High-voltage processor (pack contactor and isolation controller): hardware id";
CM_ SG_ 784 HVP_componentId "High-voltage processor (pack contactor and isolation controller): component id";
CM_ SG_ 784 HVP_pcbaId "High-voltage processor (pack contactor and isolation controller): pcba id";
CM_ SG_ 784 HVP_assemblyId "HVP's assigned assembly ID";
CM_ SG_ 784 HVP_usageId "HVP's assigned usage ID";
CM_ SG_ 784 HVP_subUsageId "HVP's assigned subusage ID";
CM_ SG_ 784 HVP_platformType "High-voltage processor (pack contactor and isolation controller): platform type";
CM_ SG_ 784 HVP_appCrc "High-voltage processor (pack contactor and isolation controller): app crc";
CM_ SG_ 784 HVP_appGitHash "High-voltage processor (pack contactor and isolation controller): app git hash";
CM_ SG_ 784 HVP_bootGitHash "High-voltage processor (pack contactor and isolation controller): boot git hash";
CM_ SG_ 784 HVP_bootUdsProtoVersion "High-voltage processor (pack contactor and isolation controller): boot uds proto version";
CM_ SG_ 784 HVP_bootCrc "High-voltage processor (pack contactor and isolation controller): boot crc";
CM_ BO_ 1914 "High-voltage processor (pack contactor and isolation controller) message: log1hz";
CM_ SG_ 1914 HVP_log1HzIndex "High-voltage processor (pack contactor and isolation controller): log1 hz index";
CM_ SG_ 1914 HVP_bmbAsicType "The BMB Asic type being used by this battery pack for reading brick data";
CM_ SG_ 1914 HVP_shuntCurrentAuxLog "High-voltage processor (pack contactor and isolation controller): shunt current aux log";
CM_ SG_ 1914 HVP_pyroSquibResistance "The pyro resistance measured on attempt to close contactor or by the Pyro selftest; raw 65535 = signal not available (SNA)";
CM_ SG_ 1914 HVP_shuntAsicChipXCoordinate "High-voltage processor (pack contactor and isolation controller): shunt asic chip x coordinate";
CM_ SG_ 1914 HVP_shuntAsicChipYCoordinate "High-voltage processor (pack contactor and isolation controller): shunt asic chip y coordinate";
CM_ SG_ 1914 HVP_hvilCalType "High-voltage processor (pack contactor and isolation controller): hvil cal type";
CM_ SG_ 1914 HVP_gpioPcsDcdcPwmEnable "High-voltage processor (pack contactor and isolation controller): gpio pcs dcdc pwm enable";
CM_ SG_ 1914 HVP_gpioPcsChargePwmEnable "High-voltage processor (pack contactor and isolation controller): gpio pcs charge pwm enable";
CM_ SG_ 1914 HVP_gpioPcsEnable "HVP GPIO control for PCS logic power enable line";
CM_ SG_ 1914 HVP_shuntAsicChipWaferNumber "High-voltage processor (pack contactor and isolation controller): shunt asic chip wafer number";
CM_ SG_ 1914 HVP_energyReserveMin "a lowest energy reserve value measured over sliding window";
CM_ SG_ 1914 HVP_energyReserveMax "a highest energy reserve value measured over sliding window";
CM_ SG_ 1914 HVP_energyReserveAvg "an average energy reserve value measured over sliding window";
CM_ BO_ 941 "ICR ECU message: info";
CM_ SG_ 941 ICR_infoIndex "ICR ECU: info index";
CM_ SG_ 941 ICR_infoBuildType "ICR ECU: info build type";
CM_ SG_ 941 ICR_infoPcbaId "ICR ECU: info pcba id";
CM_ SG_ 941 ICR_infoAssemblyId "ICR ECU: info assembly id";
CM_ SG_ 941 ICR_infoUsageId "ICR ECU: info usage id";
CM_ SG_ 941 ICR_infoAppCrc "ICR ECU: info app crc";
CM_ SG_ 941 ICR_infoBoardPartNumber17 "ICR ECU: info board part number17";
CM_ SG_ 941 ICR_infoBoardPartNumber814 "ICR ECU: info board part number814";
CM_ SG_ 941 ICR_infoBoardPartNumber1520 "ICR ECU: info board part number1520";
CM_ BO_ 667 "ICR ECU message: non localized occupancy";
CM_ SG_ 667 ICR_lifePresenceMLOutput "ICR ECU: life presence ML output; raw 255 = signal not available (SNA)";
CM_ SG_ 667 ICR_largeOccupantPresenceMLOutpu "ICR ECU: large occupant presence ML output; raw 255 = signal not available (SNA)";
CM_ SG_ 667 ICR_lifePresenceRaw "ICR ECU: life presence raw; raw 0 = signal not available (SNA)";
CM_ SG_ 667 ICR_lifePresenceFilt "ICR ECU: life presence filt; raw 0 = signal not available (SNA)";
CM_ SG_ 667 ICR_largeOccupantPresenceRaw "ICR ECU: large occupant presence raw; raw 3 = signal not available (SNA)";
CM_ SG_ 667 ICR_largeOccupantPresenceFilt "Indicates the filtered detection status of the Large Occupant Presence Detection feature.; raw 3 = signal not available (SNA)";
CM_ SG_ 667 ICR_childPresenceFunctionality "The functionality of the child presence detection app on ICR; raw 2 = signal not available (SNA)";
CM_ SG_ 667 ICR_userPresenceFunctionality "ICR ECU: user presence functionality; raw 2 = signal not available (SNA)";
CM_ SG_ 667 ICR_userPresenceMLOutput "ICR ECU: user presence ML output; raw 255 = signal not available (SNA)";
CM_ SG_ 667 ICR_userPresenceRaw "ICR ECU: user presence raw; raw 3 = signal not available (SNA)";
CM_ SG_ 667 ICR_userPresenceFilt "Detection status of User Presence Detection feature; raw 3 = signal not available (SNA)";
CM_ BO_ 536 "ICR ECU message: occupancy";
CM_ SG_ 536 ICR_occupancy1LRaw "(Non-Functional Interface) Occupancy detection status of First Row left seat; raw 3 = signal not available (SNA)";
CM_ SG_ 536 ICR_occupancy1RRaw "(Non-Functional Interface) Occupancy detection status of First Row right seat; raw 3 = signal not available (SNA)";
CM_ SG_ 536 ICR_occupancy1LVoteCnt "ICR ECU: occupancy1 l vote cnt";
CM_ SG_ 536 ICR_occupancy1RVoteCnt "ICR ECU: occupancy1 r vote cnt";
CM_ SG_ 536 ICR_occupancy1LFilt "(Non-Functional Interface) Occupancy detection status of First Row left seat; raw 3 = signal not available (SNA)";
CM_ SG_ 536 ICR_occupancy1RFilt "(Non-Functional Interface) Occupancy detection status of First Row right seat; raw 3 = signal not available (SNA)";
CM_ SG_ 536 ICR_occupancy2LFilt "ICR ECU: occupancy2 l filt; raw 3 = signal not available (SNA)";
CM_ SG_ 536 ICR_occupancy2CFilt "ICR ECU: occupancy2 c filt; raw 3 = signal not available (SNA)";
CM_ SG_ 536 ICR_occupancy2RFilt "ICR ECU: occupancy2 r filt; raw 3 = signal not available (SNA)";
CM_ SG_ 536 ICR_occupancy1RFiltExp "ICR ECU: occupancy1 r filt exp; raw 3 = signal not available (SNA)";
CM_ SG_ 536 ICR_occupancyCounter "ICR ECU: occupancy counter";
CM_ SG_ 536 ICR_occupancyChecksum "ICR ECU: occupancy checksum";
CM_ BO_ 670 "ICR ECU message: occupancy2";
CM_ SG_ 670 ICR_classification1RFilt "Occupant classification status of First Row Right seat; raw 0 = signal not available (SNA)";
CM_ SG_ 670 ICR_classification1LRaw "ICR ECU: classification1 l raw; raw 0 = signal not available (SNA)";
CM_ SG_ 670 ICR_classification1RRaw "ICR ECU: classification1 r raw; raw 0 = signal not available (SNA)";
CM_ SG_ 670 ICR_classification1LMLOutput "ICR ECU: classification1 LML output; raw 255 = signal not available (SNA)";
CM_ SG_ 670 ICR_classification1RMLOutput "ICR ECU: classification1 RML output; raw 255 = signal not available (SNA)";
CM_ SG_ 670 ICR_classification1LqF "ICR ECU: classification1 lq f";
CM_ SG_ 670 ICR_blockageClutterFar "The far clutter output of the blockage algorithm; raw 16 = signal not available (SNA)";
CM_ SG_ 670 ICR_blockageClutterNear "The near clutter output of the blockage algorithm; raw 16 = signal not available (SNA)";
CM_ SG_ 670 ICR_classification1LFilt "ICR ECU: classification1 l filt; raw 0 = signal not available (SNA)";
CM_ SG_ 670 ICR_classification1RqF "ICR ECU: classification1 rq f";
CM_ SG_ 670 ICR_classification1LLatched "ICR ECU: classification1 l latched; raw 0 = signal not available (SNA)";
CM_ SG_ 670 ICR_classification1RLatched "ICR ECU: classification1 r latched; raw 0 = signal not available (SNA)";
CM_ SG_ 670 ICR_classification1LIsLatched "ICR ECU: classification1 l is latched";
CM_ SG_ 670 ICR_classification1RIsLatched "ICR ECU: classification1 r is latched";
CM_ SG_ 670 ICR_occupancy2Counter "ICR ECU: occupancy2 counter";
CM_ SG_ 670 ICR_occupancy2Checksum "ICR ECU: occupancy2 checksum";
CM_ BO_ 664 "ICR ECU message: status";
CM_ SG_ 664 ICR_sensorMode "ICR ECU: sensor mode";
CM_ SG_ 664 ICR_blocked "Indicates if sensor is blocked or not; raw 0 = signal not available (SNA)";
CM_ SG_ 664 ICR_booted "Indicates if ICR has rebooted";
CM_ SG_ 664 ICR_rdMapDumpCompleted "ICR ECU: rd map dump completed";
CM_ SG_ 664 ICR_algoVersion "ICR ECU: algo version";
CM_ SG_ 664 ICR_l2HeapUsage "ICR ECU: l2 heap usage";
CM_ SG_ 664 ICR_intrusionStatus "ICR ECU: intrusion status";
CM_ SG_ 664 ICR_blockageScaledMLOutput "Indicates a scaled blockage ML Output";
CM_ BO_ 1012 "LS ECU message: light show; forwarded onto this bus by the gateway";
CM_ SG_ 1012 LS_lightShowIndex "LS ECU: light show index";
CM_ SG_ 1012 LS_lightLeftRampedChannel1Reques "LS ECU: light left ramped channel1 request";
CM_ SG_ 1012 LS_lightLeftRampedChannel1Durati "LS ECU: light left ramped channel1 duration";
CM_ SG_ 1012 LS_lightLeftRampedChannel2Reques "LS ECU: light left ramped channel2 request";
CM_ SG_ 1012 LS_lightLeftRampedChannel2Durati "LS ECU: light left ramped channel2 duration";
CM_ SG_ 1012 LS_lightLeftRampedChannel3Reques "LS ECU: light left ramped channel3 request";
CM_ SG_ 1012 LS_lightLeftRampedChannel3Durati "LS ECU: light left ramped channel3 duration";
CM_ SG_ 1012 LS_lightLeftRampedChannel4Reques "LS ECU: light left ramped channel4 request";
CM_ SG_ 1012 LS_lightLeftRampedChannel4Durati "LS ECU: light left ramped channel4 duration";
CM_ SG_ 1012 LS_lightLeftRampedChannel5Reques "LS ECU: light left ramped channel5 request";
CM_ SG_ 1012 LS_lightLeftRampedChannel5Durati "LS ECU: light left ramped channel5 duration";
CM_ SG_ 1012 LS_lightLeftRampedChannel6Reques "LS ECU: light left ramped channel6 request";
CM_ SG_ 1012 LS_lightLeftRampedChannel6Durati "LS ECU: light left ramped channel6 duration";
CM_ SG_ 1012 LS_lightLeftRampedChannel7Reques "LS ECU: light left ramped channel7 request";
CM_ SG_ 1012 LS_lightLeftRampedChannel7Durati "LS ECU: light left ramped channel7 duration";
CM_ SG_ 1012 LS_lightRightRampedChannel1Reque "LS ECU: light right ramped channel1 request";
CM_ SG_ 1012 LS_lightRightRampedChannel1Durat "LS ECU: light right ramped channel1 duration; raw 1 = signal not available (SNA)";
CM_ SG_ 1012 LS_lightRightRampedChannel2Reque "LS ECU: light right ramped channel2 request";
CM_ SG_ 1012 LS_lightRightRampedChannel2Durat "LS ECU: light right ramped channel2 duration; raw 1 = signal not available (SNA)";
CM_ SG_ 1012 LS_lightRightRampedChannel3Reque "LS ECU: light right ramped channel3 request";
CM_ SG_ 1012 LS_lightRightRampedChannel3Durat "LS ECU: light right ramped channel3 duration";
CM_ SG_ 1012 LS_lightRightRampedChannel4Reque "LS ECU: light right ramped channel4 request";
CM_ SG_ 1012 LS_lightRightRampedChannel4Durat "LS ECU: light right ramped channel4 duration";
CM_ SG_ 1012 LS_lightRightRampedChannel5Reque "LS ECU: light right ramped channel5 request";
CM_ SG_ 1012 LS_lightRightRampedChannel5Durat "LS ECU: light right ramped channel5 duration";
CM_ SG_ 1012 LS_lightRightRampedChannel6Reque "LS ECU: light right ramped channel6 request";
CM_ SG_ 1012 LS_lightRightRampedChannel6Durat "LS ECU: light right ramped channel6 duration";
CM_ SG_ 1012 LS_lightRightRampedChannel7Reque "LS ECU: light right ramped channel7 request";
CM_ SG_ 1012 LS_lightRightRampedChannel7Durat "LS ECU: light right ramped channel7 duration";
CM_ SG_ 1012 LS_lightRearTurnLeftRequest "LS ECU: light rear turn left request";
CM_ SG_ 1012 LS_lightRearTurnRightRequest "LS ECU: light rear turn right request";
CM_ SG_ 1012 LS_lightSideRepeaterLeftRequest "LS ECU: light side repeater left request";
CM_ SG_ 1012 LS_lightSideRepeaterRightRequest "LS ECU: light side repeater right request";
CM_ SG_ 1012 LS_lightSideMarkerLeftRequest "LS ECU: light side marker left request";
CM_ SG_ 1012 LS_lightSideMarkerRightRequest "LS ECU: light side marker right request";
CM_ SG_ 1012 LS_lightFrontFogLeftRequest "LS ECU: light front fog left request";
CM_ SG_ 1012 LS_lightFrontFogRightRequest "LS ECU: light front fog right request";
CM_ SG_ 1012 LS_lightRearFogRequest "LS ECU: light rear fog request";
CM_ SG_ 1012 LS_lightBrakeRequest "LS ECU: light brake request";
CM_ SG_ 1012 LS_lightTailLeftRequest "LS ECU: light tail left request";
CM_ SG_ 1012 LS_lightTailRightRequest "LS ECU: light tail right request";
CM_ SG_ 1012 LS_lightLicensePlateRequest "LS ECU: light license plate request";
CM_ SG_ 1012 LS_lightReverseRequest "LS ECU: light reverse request";
CM_ SG_ 1012 LS_lightAuxParkLeftRequest "LS ECU: light aux park left request";
CM_ SG_ 1012 LS_lightAuxParkRightRequest "LS ECU: light aux park right request";
CM_ SG_ 1012 LS_mirrorRequestLeft "LS ECU: mirror request left";
CM_ SG_ 1012 LS_mirrorRequestRight "LS ECU: mirror request right";
CM_ SG_ 1012 LS_liftgateRequest "LS ECU: liftgate request";
CM_ SG_ 1012 LS_windowRequestLF "LS ECU: window request LF";
CM_ SG_ 1012 LS_windowRequestLR "LS ECU: window request LR";
CM_ SG_ 1012 LS_windowRequestRF "LS ECU: window request RF";
CM_ SG_ 1012 LS_windowRequestRR "LS ECU: window request RR";
CM_ SG_ 1012 LS_presentingHandleRequestLF "LS ECU: presenting handle request LF";
CM_ SG_ 1012 LS_presentingHandleRequestLR "LS ECU: presenting handle request LR";
CM_ SG_ 1012 LS_presentingHandleRequestRF "LS ECU: presenting handle request RF";
CM_ SG_ 1012 LS_presentingHandleRequestRR "LS ECU: presenting handle request RR";
CM_ SG_ 1012 LS_powerFrontDoorRequestLeft "LS ECU: power front door request left";
CM_ SG_ 1012 LS_powerFrontDoorRequestRight "LS ECU: power front door request right";
CM_ SG_ 1012 LS_falconDoorRequestLeft "LS ECU: falcon door request left";
CM_ SG_ 1012 LS_falconDoorRequestRight "LS ECU: falcon door request right";
CM_ SG_ 1012 LS_chargePortRequest "LS ECU: charge port request; raw 3 = signal not available (SNA)";
CM_ SG_ 1012 LS_chargePortRaveRequest "LS ECU: charge port rave request";
CM_ SG_ 1012 LS_suspensionRequest "LS ECU: suspension request; raw 3 = signal not available (SNA)";
CM_ SG_ 1012 LS_rgbIPFLRed "LS ECU: rgb IPFL red";
CM_ SG_ 1012 LS_rgbIPFLGreen "LS ECU: rgb IPFL green";
CM_ SG_ 1012 LS_rgbIPFLBlue "LS ECU: rgb IPFL blue";
CM_ SG_ 1012 LS_rgbIPFRRed "LS ECU: rgb IPFR red";
CM_ SG_ 1012 LS_rgbIPFRGreen "LS ECU: rgb IPFR green";
CM_ SG_ 1012 LS_rgbIPFRBlue "LS ECU: rgb IPFR blue";
CM_ SG_ 1012 LS_rgbDoorFLForeRed "LS ECU: rgb door FL fore red";
CM_ SG_ 1012 LS_rgbDoorFLForeGreen "LS ECU: rgb door FL fore green";
CM_ SG_ 1012 LS_rgbDoorFLForeBlue "LS ECU: rgb door FL fore blue";
CM_ SG_ 1012 LS_rgbDoorFLAftRed "LS ECU: rgb door FL aft red";
CM_ SG_ 1012 LS_rgbDoorFLAftGreen "LS ECU: rgb door FL aft green";
CM_ SG_ 1012 LS_rgbDoorFLAftBlue "LS ECU: rgb door FL aft blue";
CM_ SG_ 1012 LS_rgbDoorFRForeRed "LS ECU: rgb door FR fore red";
CM_ SG_ 1012 LS_rgbDoorFRForeGreen "LS ECU: rgb door FR fore green";
CM_ SG_ 1012 LS_rgbDoorFRForeBlue "LS ECU: rgb door FR fore blue";
CM_ SG_ 1012 LS_rgbDoorFRAftRed "LS ECU: rgb door FR aft red";
CM_ SG_ 1012 LS_rgbDoorFRAftGreen "LS ECU: rgb door FR aft green";
CM_ SG_ 1012 LS_rgbDoorFRAftBlue "LS ECU: rgb door FR aft blue";
CM_ SG_ 1012 LS_rgbDoorRLForeRed "LS ECU: rgb door RL fore red";
CM_ SG_ 1012 LS_rgbDoorRLForeGreen "LS ECU: rgb door RL fore green";
CM_ SG_ 1012 LS_rgbDoorRLForeBlue "LS ECU: rgb door RL fore blue";
CM_ SG_ 1012 LS_rgbDoorRLAftRed "LS ECU: rgb door RL aft red";
CM_ SG_ 1012 LS_rgbDoorRLAftGreen "LS ECU: rgb door RL aft green";
CM_ SG_ 1012 LS_rgbDoorRLAftBlue "LS ECU: rgb door RL aft blue";
CM_ SG_ 1012 LS_rgbDoorRRForeRed "LS ECU: rgb door RR fore red";
CM_ SG_ 1012 LS_rgbDoorRRForeGreen "LS ECU: rgb door RR fore green";
CM_ SG_ 1012 LS_rgbDoorRRForeBlue "LS ECU: rgb door RR fore blue";
CM_ SG_ 1012 LS_rgbDoorRRAftRed "LS ECU: rgb door RR aft red";
CM_ SG_ 1012 LS_rgbDoorRRAftGreen "LS ECU: rgb door RR aft green";
CM_ SG_ 1012 LS_rgbDoorRRAftBlue "LS ECU: rgb door RR aft blue";
CM_ SG_ 1012 LS_frontMatrix0 "LS ECU: front matrix0";
CM_ SG_ 1012 LS_frontMatrix1 "LS ECU: front matrix1";
CM_ SG_ 1012 LS_frontMatrix2 "LS ECU: front matrix2";
CM_ SG_ 1012 LS_frontMatrix3 "LS ECU: front matrix3";
CM_ SG_ 1012 LS_frontMatrix4 "LS ECU: front matrix4";
CM_ SG_ 1012 LS_frontMatrix5 "LS ECU: front matrix5";
CM_ SG_ 1012 LS_frontMatrix6 "LS ECU: front matrix6";
CM_ SG_ 1012 LS_frontMatrix7 "LS ECU: front matrix7";
CM_ SG_ 1012 LS_frontMatrix8 "LS ECU: front matrix8";
CM_ SG_ 1012 LS_frontMatrix9 "LS ECU: front matrix9";
CM_ SG_ 1012 LS_frontMatrix10 "LS ECU: front matrix10";
CM_ SG_ 1012 LS_frontMatrix11 "LS ECU: front matrix11";
CM_ SG_ 1012 LS_frontMatrix12 "LS ECU: front matrix12";
CM_ SG_ 1012 LS_frontMatrix13 "LS ECU: front matrix13";
CM_ SG_ 1012 LS_frontMatrix14 "LS ECU: front matrix14";
CM_ SG_ 1012 LS_frontMatrix15 "LS ECU: front matrix15";
CM_ SG_ 1012 LS_frontMatrix16 "LS ECU: front matrix16";
CM_ SG_ 1012 LS_frontMatrix17 "LS ECU: front matrix17";
CM_ SG_ 1012 LS_frontMatrix18 "LS ECU: front matrix18";
CM_ SG_ 1012 LS_frontMatrix19 "LS ECU: front matrix19";
CM_ SG_ 1012 LS_frontMatrix20 "LS ECU: front matrix20";
CM_ SG_ 1012 LS_frontMatrix21 "LS ECU: front matrix21";
CM_ SG_ 1012 LS_frontMatrix22 "LS ECU: front matrix22";
CM_ SG_ 1012 LS_frontMatrix23 "LS ECU: front matrix23";
CM_ SG_ 1012 LS_frontMatrix24 "LS ECU: front matrix24";
CM_ SG_ 1012 LS_frontMatrix25 "LS ECU: front matrix25";
CM_ SG_ 1012 LS_frontMatrix26 "LS ECU: front matrix26";
CM_ SG_ 1012 LS_frontMatrix27 "LS ECU: front matrix27";
CM_ SG_ 1012 LS_frontMatrix28 "LS ECU: front matrix28";
CM_ SG_ 1012 LS_frontMatrix29 "LS ECU: front matrix29";
CM_ SG_ 1012 LS_frontMatrix30 "LS ECU: front matrix30";
CM_ SG_ 1012 LS_frontMatrix31 "LS ECU: front matrix31";
CM_ SG_ 1012 LS_frontMatrix32 "LS ECU: front matrix32";
CM_ SG_ 1012 LS_frontMatrix33 "LS ECU: front matrix33";
CM_ SG_ 1012 LS_frontMatrix34 "LS ECU: front matrix34";
CM_ SG_ 1012 LS_frontMatrix35 "LS ECU: front matrix35";
CM_ SG_ 1012 LS_frontMatrix36 "LS ECU: front matrix36";
CM_ SG_ 1012 LS_frontMatrix37 "LS ECU: front matrix37";
CM_ SG_ 1012 LS_frontMatrix38 "LS ECU: front matrix38";
CM_ SG_ 1012 LS_frontMatrix39 "LS ECU: front matrix39";
CM_ SG_ 1012 LS_frontMatrix40 "LS ECU: front matrix40";
CM_ SG_ 1012 LS_frontMatrix41 "LS ECU: front matrix41";
CM_ SG_ 1012 LS_frontMatrix42 "LS ECU: front matrix42";
CM_ SG_ 1012 LS_frontMatrix43 "LS ECU: front matrix43";
CM_ SG_ 1012 LS_frontMatrix44 "LS ECU: front matrix44";
CM_ SG_ 1012 LS_frontMatrix45 "LS ECU: front matrix45";
CM_ SG_ 1012 LS_frontMatrix46 "LS ECU: front matrix46";
CM_ SG_ 1012 LS_frontMatrix47 "LS ECU: front matrix47";
CM_ SG_ 1012 LS_frontMatrix48 "LS ECU: front matrix48";
CM_ SG_ 1012 LS_frontMatrix49 "LS ECU: front matrix49";
CM_ SG_ 1012 LS_frontMatrix50 "LS ECU: front matrix50";
CM_ SG_ 1012 LS_frontMatrix51 "LS ECU: front matrix51";
CM_ SG_ 1012 LS_frontMatrix52 "LS ECU: front matrix52";
CM_ SG_ 1012 LS_frontMatrix53 "LS ECU: front matrix53";
CM_ SG_ 1012 LS_frontMatrix54 "LS ECU: front matrix54";
CM_ SG_ 1012 LS_frontMatrix55 "LS ECU: front matrix55";
CM_ SG_ 1012 LS_frontMatrix56 "LS ECU: front matrix56";
CM_ SG_ 1012 LS_frontMatrix57 "LS ECU: front matrix57";
CM_ SG_ 1012 LS_frontMatrix58 "LS ECU: front matrix58";
CM_ SG_ 1012 LS_frontMatrix59 "LS ECU: front matrix59";
CM_ SG_ 1012 LS_rearMatrix0 "LS ECU: rear matrix0";
CM_ SG_ 1012 LS_rearMatrix1 "LS ECU: rear matrix1";
CM_ SG_ 1012 LS_rearMatrix2 "LS ECU: rear matrix2";
CM_ SG_ 1012 LS_rearMatrix3 "LS ECU: rear matrix3";
CM_ SG_ 1012 LS_rearMatrix4 "LS ECU: rear matrix4";
CM_ SG_ 1012 LS_rearMatrix5 "LS ECU: rear matrix5";
CM_ SG_ 1012 LS_rearMatrix6 "LS ECU: rear matrix6";
CM_ SG_ 1012 LS_rearMatrix7 "LS ECU: rear matrix7";
CM_ SG_ 1012 LS_rearMatrix8 "LS ECU: rear matrix8";
CM_ SG_ 1012 LS_rearMatrix9 "LS ECU: rear matrix9";
CM_ SG_ 1012 LS_rearMatrix10 "LS ECU: rear matrix10";
CM_ SG_ 1012 LS_rearMatrix11 "LS ECU: rear matrix11";
CM_ SG_ 1012 LS_rearMatrix12 "LS ECU: rear matrix12";
CM_ SG_ 1012 LS_rearMatrix13 "LS ECU: rear matrix13";
CM_ SG_ 1012 LS_rearMatrix14 "LS ECU: rear matrix14";
CM_ SG_ 1012 LS_rearMatrix15 "LS ECU: rear matrix15";
CM_ SG_ 1012 LS_rearMatrix16 "LS ECU: rear matrix16";
CM_ SG_ 1012 LS_rearMatrix17 "LS ECU: rear matrix17";
CM_ SG_ 1012 LS_rearMatrix18 "LS ECU: rear matrix18";
CM_ SG_ 1012 LS_rearMatrix19 "LS ECU: rear matrix19";
CM_ SG_ 1012 LS_rearMatrix20 "LS ECU: rear matrix20";
CM_ SG_ 1012 LS_rearMatrix21 "LS ECU: rear matrix21";
CM_ SG_ 1012 LS_rearMatrix22 "LS ECU: rear matrix22";
CM_ SG_ 1012 LS_rearMatrix23 "LS ECU: rear matrix23";
CM_ SG_ 1012 LS_rearMatrix24 "LS ECU: rear matrix24";
CM_ SG_ 1012 LS_rearMatrix25 "LS ECU: rear matrix25";
CM_ SG_ 1012 LS_rearMatrix26 "LS ECU: rear matrix26";
CM_ SG_ 1012 LS_rearMatrix27 "LS ECU: rear matrix27";
CM_ SG_ 1012 LS_rearMatrix28 "LS ECU: rear matrix28";
CM_ SG_ 1012 LS_rearMatrix29 "LS ECU: rear matrix29";
CM_ SG_ 1012 LS_rearMatrix30 "LS ECU: rear matrix30";
CM_ SG_ 1012 LS_rearMatrix31 "LS ECU: rear matrix31";
CM_ SG_ 1012 LS_rearMatrix32 "LS ECU: rear matrix32";
CM_ SG_ 1012 LS_rearMatrix33 "LS ECU: rear matrix33";
CM_ SG_ 1012 LS_rearMatrix34 "LS ECU: rear matrix34";
CM_ SG_ 1012 LS_rearMatrix35 "LS ECU: rear matrix35";
CM_ SG_ 1012 LS_rearMatrix36 "LS ECU: rear matrix36";
CM_ SG_ 1012 LS_rearMatrix37 "LS ECU: rear matrix37";
CM_ SG_ 1012 LS_rearMatrix38 "LS ECU: rear matrix38";
CM_ SG_ 1012 LS_rearMatrix39 "LS ECU: rear matrix39";
CM_ SG_ 1012 LS_rearMatrix40 "LS ECU: rear matrix40";
CM_ SG_ 1012 LS_rearMatrix41 "LS ECU: rear matrix41";
CM_ SG_ 1012 LS_rearMatrix42 "LS ECU: rear matrix42";
CM_ SG_ 1012 LS_rearMatrix43 "LS ECU: rear matrix43";
CM_ SG_ 1012 LS_rearMatrix44 "LS ECU: rear matrix44";
CM_ SG_ 1012 LS_rearMatrix45 "LS ECU: rear matrix45";
CM_ SG_ 1012 LS_rearMatrix46 "LS ECU: rear matrix46";
CM_ SG_ 1012 LS_rearMatrix47 "LS ECU: rear matrix47";
CM_ SG_ 1012 LS_rearMatrix48 "LS ECU: rear matrix48";
CM_ SG_ 1012 LS_rearMatrix49 "LS ECU: rear matrix49";
CM_ SG_ 1012 LS_rearMatrix50 "LS ECU: rear matrix50";
CM_ SG_ 1012 LS_rearMatrix51 "LS ECU: rear matrix51";
CM_ SG_ 1012 LS_rearMatrix52 "LS ECU: rear matrix52";
CM_ SG_ 1012 LS_rearMatrix53 "LS ECU: rear matrix53";
CM_ SG_ 1012 LS_rearMatrix54 "LS ECU: rear matrix54";
CM_ SG_ 1012 LS_rearMatrix55 "LS ECU: rear matrix55";
CM_ SG_ 1012 LS_rearMatrix56 "LS ECU: rear matrix56";
CM_ SG_ 1012 LS_rearMatrix57 "LS ECU: rear matrix57";
CM_ SG_ 1012 LS_rearMatrix58 "LS ECU: rear matrix58";
CM_ SG_ 1012 LS_rearMatrix59 "LS ECU: rear matrix59";
CM_ SG_ 1012 LS_offroadLightBar0 "LS ECU: offroad light bar0";
CM_ SG_ 1012 LS_offroadLightBar1 "LS ECU: offroad light bar1";
CM_ SG_ 1012 LS_offroadLightBar2 "LS ECU: offroad light bar2";
CM_ SG_ 1012 LS_offroadLightBar3 "LS ECU: offroad light bar3";
CM_ SG_ 1012 LS_offroadLightBar4 "LS ECU: offroad light bar4";
CM_ SG_ 1012 LS_offroadLightBar5 "LS ECU: offroad light bar5";
CM_ BO_ 740 "PCS2 ECU message: logging";
CM_ SG_ 740 PCS2_logMessageSelect "PCS2 ECU: log message select";
CM_ SG_ 740 PCS2_dcdcUsingInternalDefLvTarge "PCS2 ECU: dcdc using internal def lv target";
CM_ SG_ 740 PCS2_dcdcAStateMachineState "DCDC A stage state machine state";
CM_ SG_ 740 PCS2_dcdcBStateMachineState "DCDC B stage state machine state";
CM_ SG_ 740 PCS2_dcdcAStageModeRequest "DCDC A stage state machine mode request";
CM_ SG_ 740 PCS2_dcdcBStageModeRequest "DCDC B stage state machine mode request";
CM_ SG_ 740 PCS2_dcdcAHvCurrentCommand "DCDC A controller commanded HV current";
CM_ SG_ 740 PCS2_dcdcALvCurrentCommand "Reports the Direct Current to Direct Current (DCDC) A commanded Low Voltage (LV) current.";
CM_ SG_ 740 PCS2_dcdcAPowerLimit "DCDC A power limit";
CM_ SG_ 740 PCS2_dcdcALvCurrentEstimated "DCDC A estimated LV current";
CM_ SG_ 740 PCS2_dcdcLvBusVoltageFiltered "DCDC system filtered LV bus voltage";
CM_ SG_ 740 PCS2_dcdcALifetimekWh "Lifetime energy throughput of DCDC-A power conversion; raw 16777215 = signal not available (SNA)";
CM_ SG_ 740 PCS2_dcdcBHvCurrentCommand "DCDC B controller commanded HV current";
CM_ SG_ 740 PCS2_dcdcBLvCurrentCommand "Reports the Direct Current to Direct Current (DCDC) B commanded Low Voltage (LV) current.";
CM_ SG_ 740 PCS2_dcdcBPowerLimit "DCDC B power limit";
CM_ SG_ 740 PCS2_dcdcBLvCurrentEstimated "DCDC B estimated LV current";
CM_ SG_ 740 PCS2_dcdcBLifetimekWh "Lifetime energy throughput of DCDC-B power conversion; raw 16777215 = signal not available (SNA)";
CM_ SG_ 740 PCS2_dcdcA_lv2Temp "Measures the temperature of the Printed Circuit Board (PCB) when it is near the winding DCDC converter (DCDCA) low voltage 2 planar transformer. The planar transformer is located at the drain of Q8 transistor or at the source of Q6 transistor near the S_LVB_1T electrical connection.; raw 1025 = signal not available (SNA)";
CM_ SG_ 740 PCS2_dcdcA_lv2TempIrrational "PCS2 ECU: dcdc a lv2 temp irrational";
CM_ SG_ 740 PCS2_dcdcB_lv2Temp "Sensing temperature of the PCB in the vicinity of dcdc1_Lv2 planer transformer winding at the drain of Q107/source of Q106, Covering net S_LVB_1T; raw 1025 = signal not available (SNA)";
CM_ SG_ 740 PCS2_dcdcB_lv2TempIrrational "PCS2 ECU: dcdc b lv2 temp irrational";
CM_ SG_ 740 PCS2_dcdcA_hvTemp "Sensing temperature of the PCB in the vicinity of dcdc2_HV planer transformer winding at the drain of Q3781/source of Q3681, covering net DCDC2_BATTTANK+; raw 1025 = signal not available (SNA)";
CM_ SG_ 740 PCS2_dcdcA_hvTempIrrational "PCS2 ECU: dcdc a hv temp irrational";
CM_ SG_ 740 PCS2_dcdcB_hvTemp "Sensing temperature of the PCB in the vicinity of dcdc1_HV planer transformer winding at the drain of Q3441/source of Q3341, Covering net DCDC1_HVTANK+; raw 1025 = signal not available (SNA)";
CM_ SG_ 740 PCS2_dcdcB_hvTempIrrational "PCS2 ECU: dcdc b hv temp irrational";
CM_ SG_ 740 PCS2_acChargeLifetimekVAh "Lifetime energy throughput of AC Charging; raw 16777215 = signal not available (SNA)";
CM_ SG_ 740 PCS2_v2xGridFormLifetimekVAh "Lifetime energy throughput of V2X grid forming; raw 16777215 = signal not available (SNA)";
CM_ SG_ 740 PCS2_cabinOnlyL2L3LifetimekVAh "Lifetime energy throughput of cabin only outlet grid forming; raw 16777215 = signal not available (SNA)";
CM_ SG_ 740 PCS2_totalOutletLifetimekVAh "Lifetime energy throughput the total outlet grid forming (excluding Charge Port); raw 16777215 = signal not available (SNA)";
CM_ SG_ 740 PCS2_cabinAndBedL1L2LifetimekVAh "Lifetime energy throughput between L1L2 outlet grid forming when cabin and bed outlets are both enabled; raw 16777215 = signal not available (SNA)";
CM_ SG_ 740 PCS2_cabinAndBedL2L3LifetimekVAh "Lifetime energy throughput of L2L3 outlet grid forming when both cabin and bed outlets are enabled; raw 16777215 = signal not available (SNA)";
CM_ BO_ 1039 "PCS2 ECU message: v2x info2";
CM_ SG_ 1039 PCS2_v2xUserPower "Reports the present Power Conversion System 2 (PCS2) Vehicle-to-Everything (V2X) user-requested Alternating Current (AC) real power (positive polarity is battery discharging).";
CM_ SG_ 1039 PCS2_v2xDispatchableApparentPowe "Reports the maximum apparent power Power Conversion System 2 (PCS2) is currently capable of for Vehicle-to-Everything (V2X) operations";
CM_ SG_ 1039 PCS2_v2xReadyApparentPower "Reports the maximum apparent power Power Conversion System 2 (PCS2) is capable of for Vehicle-to-Everything (V2X) operations under nominal grid conditions";
CM_ BO_ 612 "Power conversion system (on-board charger and DC-DC converter) message: chg line status";
CM_ SG_ 612 PCS_chgInputVoltage "RMS value of AC charger's sensed input voltage";
CM_ SG_ 612 PCS_chgLineCurrent "AC charger's sensed input line current";
CM_ SG_ 612 PCS_chgAcVoltagePresent "Indicates whether AC voltage is present on the PCS input";
CM_ SG_ 612 PCS_chgInputPower "Total AC charger input power";
CM_ SG_ 612 PCS_chgAcCurrentLimit "Maximum AC current that can be pulled from a single conductor";
CM_ BO_ 516 "Power conversion system (on-board charger and DC-DC converter) message: chg status";
CM_ SG_ 516 PCS_chgMainState "Power conversion system (on-board charger and DC-DC converter): chg main state";
CM_ SG_ 516 PCS_powerTransferStatus "Reports the AC power transfer interface state of the Power Conversion System (PCS).";
CM_ SG_ 516 PCS_gridConfig "AC charger sensed grid configuration; raw 0 = signal not available (SNA)";
CM_ SG_ 516 PCS_chgPHAEnable "Indicates whether AC charger phase A is enabled";
CM_ SG_ 516 PCS_chgPHBEnable "Indicates whether AC charger phase B is enabled";
CM_ SG_ 516 PCS_hvInletConductorEnergizedAc "Power conversion system (on-board charger and DC-DC converter): hv inlet conductor energized ac";
CM_ SG_ 516 PCS_chgHighPowerActive "Power conversion system (on-board charger and DC-DC converter): chg high power active";
CM_ SG_ 516 PCS_chgPHCEnable "Indicates whether AC charger phase C is enabled";
CM_ SG_ 516 PCS_chgInstantAcPowerAvailable "Instantaneous power capability of the AC charger";
CM_ SG_ 516 PCS_chgMaxAcPowerAvailable "Maximum power capability of the AC charger; raw 255 = signal not available (SNA)";
CM_ SG_ 516 PCS_chgPHALineCurrentRequest "AC charger phase A input current command";
CM_ SG_ 516 PCS_chgPHBLineCurrentRequest "AC charger phase B input current command";
CM_ SG_ 516 PCS_chgPHCLineCurrentRequest "AC charger phase B input current command";
CM_ SG_ 516 PCS_chgPwmEnableLine "Sensed state of the charger PWM enable hardline";
CM_ SG_ 516 PCS_powerTransferShutdownRequest "The Power Conversion System (PCS) request to shut down AC power transfer.";
CM_ SG_ 516 PCS_hwVariantType "Hardware variant of AC charger; raw 3 = signal not available (SNA)";
CM_ SG_ 516 PCS_dcacBidirectionalAllowed "Indicates whether bidirectional DCAC capability is supported by this PCS variant";
BA_DEF_ BO_ "GenMsgCycleTime" INT 0 3600000;
BA_DEF_ BO_ "GenMsgSendType" ENUM "Cyclic","NotUsed","NotUsed","NotUsed","NotUsed","NotUsed","NotUsed","IfActive","NoMsgSendType","NotUsed";
BA_DEF_ BO_ "VFrameFormat" ENUM "StandardCAN","ExtendedCAN","reserved","J1939PG","reserved","reserved","reserved","reserved","reserved","reserved","reserved","reserved","reserved","reserved","StandardCAN_FD","ExtendedCAN_FD";
BA_DEF_ BO_ "CANFD_BRS" ENUM "0","1";
BA_DEF_ SG_ "GenSigSNA" STRING;
BA_DEF_ SG_ "SystemSignalLongSymbol" STRING;
BA_DEF_ SG_ "Confidence" ENUM "validated","plausible","layout-only","contradicted";
BA_DEF_DEF_ "GenMsgCycleTime" 0;
BA_DEF_DEF_ "GenMsgSendType" "NoMsgSendType";
BA_DEF_DEF_ "VFrameFormat" "StandardCAN";
BA_DEF_DEF_ "CANFD_BRS" "1";
BA_DEF_DEF_ "GenSigSNA" "";
BA_DEF_DEF_ "SystemSignalLongSymbol" "";
BA_DEF_DEF_ "Confidence" "layout-only";
BA_ "GenMsgCycleTime" BO_ 680 100;
BA_ "GenMsgSendType" BO_ 680 0;
BA_ "GenMsgCycleTime" BO_ 2024 1000;
BA_ "GenMsgSendType" BO_ 2024 0;
BA_ "GenMsgCycleTime" BO_ 552 100;
BA_ "GenMsgSendType" BO_ 552 0;
BA_ "GenMsgCycleTime" BO_ 742 1000;
BA_ "GenMsgSendType" BO_ 742 0;
BA_ "GenMsgCycleTime" BO_ 744 100;
BA_ "GenMsgSendType" BO_ 744 0;
BA_ "GenMsgCycleTime" BO_ 1117 1000;
BA_ "GenMsgSendType" BO_ 1117 0;
BA_ "GenMsgCycleTime" BO_ 1334 1000;
BA_ "GenMsgSendType" BO_ 1334 0;
BA_ "GenMsgCycleTime" BO_ 1303 1000;
BA_ "GenMsgSendType" BO_ 1303 0;
BA_ "GenMsgCycleTime" BO_ 1310 1000;
BA_ "GenMsgSendType" BO_ 1310 0;
BA_ "GenMsgCycleTime" BO_ 580 100;
BA_ "GenMsgSendType" BO_ 580 0;
BA_ "GenMsgCycleTime" BO_ 702 100;
BA_ "GenMsgSendType" BO_ 702 0;
BA_ "GenMsgCycleTime" BO_ 1345 100;
BA_ "GenMsgSendType" BO_ 1345 0;
BA_ "GenMsgCycleTime" BO_ 1300 1000;
BA_ "GenMsgSendType" BO_ 1300 0;
BA_ "GenMsgCycleTime" BO_ 532 100;
BA_ "GenMsgSendType" BO_ 532 0;
BA_ "GenMsgCycleTime" BO_ 533 1000;
BA_ "GenMsgSendType" BO_ 533 0;
BA_ "GenMsgCycleTime" BO_ 535 1000;
BA_ "GenMsgSendType" BO_ 535 0;
BA_ "GenMsgCycleTime" BO_ 1650 10000;
BA_ "GenMsgSendType" BO_ 1650 0;
BA_ "GenMsgCycleTime" BO_ 1980 10000;
BA_ "GenMsgSendType" BO_ 1980 0;
BA_ "GenMsgCycleTime" BO_ 522 1000;
BA_ "GenMsgSendType" BO_ 522 0;
BA_ "GenMsgCycleTime" BO_ 1962 1000;
BA_ "GenMsgSendType" BO_ 1962 0;
BA_ "GenMsgCycleTime" BO_ 554 100;
BA_ "GenMsgSendType" BO_ 554 0;
BA_ "GenMsgCycleTime" BO_ 784 10000;
BA_ "GenMsgSendType" BO_ 784 0;
BA_ "GenMsgCycleTime" BO_ 1914 1000;
BA_ "GenMsgSendType" BO_ 1914 0;
BA_ "GenMsgCycleTime" BO_ 941 10000;
BA_ "GenMsgSendType" BO_ 941 0;
BA_ "GenMsgCycleTime" BO_ 667 100;
BA_ "GenMsgSendType" BO_ 667 0;
BA_ "GenMsgCycleTime" BO_ 536 100;
BA_ "GenMsgSendType" BO_ 536 0;
BA_ "GenMsgCycleTime" BO_ 670 100;
BA_ "GenMsgSendType" BO_ 670 0;
BA_ "GenMsgCycleTime" BO_ 664 100;
BA_ "GenMsgSendType" BO_ 664 0;
BA_ "GenMsgCycleTime" BO_ 740 100;
BA_ "GenMsgSendType" BO_ 740 0;
BA_ "GenMsgCycleTime" BO_ 1039 100;
BA_ "GenMsgSendType" BO_ 1039 0;
BA_ "GenMsgCycleTime" BO_ 612 100;
BA_ "GenMsgSendType" BO_ 612 0;
BA_ "GenMsgCycleTime" BO_ 516 100;
BA_ "GenMsgSendType" BO_ 516 0;
BA_ "Confidence" SG_ 680 EPBL_systemStatus 0;
BA_ "Confidence" SG_ 680 EPBL_freeRollModeStatus 0;
BA_ "Confidence" SG_ 680 EPBL_driverIsLeaving 0;
BA_ "Confidence" SG_ 680 EPBL_driverIsLeavingAnySpeed 0;
BA_ "Confidence" SG_ 680 EPBL_systemCdpAvailable 0;
BA_ "Confidence" SG_ 680 EPBL_chimeRequest 0;
BA_ "Confidence" SG_ 680 EPBL_telltale 0;
BA_ "GenSigSNA" SG_ 680 EPBL_telltale "7";
BA_ "Confidence" SG_ 680 EPBL_contactorCycleNotNeededForW 0;
BA_ "SystemSignalLongSymbol" SG_ 680 EPBL_contactorCycleNotNeededForW "EPBL_contactorCycleNotNeededForWinchEntry";
BA_ "Confidence" SG_ 680 EPBL_redundantBrakingEnabled 0;
BA_ "Confidence" SG_ 680 EPBL_summonEnabled 0;
BA_ "Confidence" SG_ 680 EPBL_brakeLight 0;
BA_ "Confidence" SG_ 680 EPBL_epbConfigMismatch 0;
BA_ "Confidence" SG_ 680 EPBL_brakeConfirmedPressed 0;
BA_ "Confidence" SG_ 680 EPBL_requestUserConfirmation 0;
BA_ "Confidence" SG_ 680 EPBL_uiWinchModeMiscBlocking 0;
BA_ "Confidence" SG_ 680 EPBL_winchModeActive 0;
BA_ "Confidence" SG_ 680 EPBL_updateMode 0;
BA_ "Confidence" SG_ 680 EPBL_winchModePermissive 0;
BA_ "Confidence" SG_ 680 EPBL_winchModePending 0;
BA_ "Confidence" SG_ 680 EPBL_cdpRequest 0;
BA_ "Confidence" SG_ 680 EPBL_uiParkAvailable 0;
BA_ "Confidence" SG_ 680 EPBL_brakeDiscWipeRequest 0;
BA_ "GenSigSNA" SG_ 680 EPBL_brakeDiscWipeRequest "3";
BA_ "Confidence" SG_ 680 EPBL_showUiGearShifter 0;
BA_ "Confidence" SG_ 680 EPBL_uiWinchModeLvStatus 0;
BA_ "Confidence" SG_ 680 EPBL_autonomyBehavior 0;
BA_ "Confidence" SG_ 680 EPBL_showStalkFaultedOnUi 0;
BA_ "Confidence" SG_ 680 EPBL_espPowerRequest 0;
BA_ "Confidence" SG_ 680 EPBL_okToPark 0;
BA_ "Confidence" SG_ 680 EPBL_hornRequest 0;
BA_ "Confidence" SG_ 680 EPBL_winchModeAvailable 0;
BA_ "Confidence" SG_ 680 EPBL_bothDisconnected 0;
BA_ "Confidence" SG_ 680 EPBL_blockDrive 0;
BA_ "Confidence" SG_ 680 EPBL_statusCounter 0;
BA_ "Confidence" SG_ 680 EPBL_statusChecksum 0;
BA_ "Confidence" SG_ 2024 EPBR_infoIndex 1;
BA_ "Confidence" SG_ 2024 EPBR_infoBuildType 0;
BA_ "Confidence" SG_ 2024 EPBR_infoBuildConfigId 0;
BA_ "Confidence" SG_ 2024 EPBR_infoHardwareId 0;
BA_ "Confidence" SG_ 2024 EPBR_infoComponentId 0;
BA_ "Confidence" SG_ 2024 EPBR_infoPcbaId 0;
BA_ "Confidence" SG_ 2024 EPBR_infoAssemblyId 0;
BA_ "GenSigSNA" SG_ 2024 EPBR_infoAssemblyId "255";
BA_ "Confidence" SG_ 2024 EPBR_infoUsageId 0;
BA_ "Confidence" SG_ 2024 EPBR_infoSubUsageId 0;
BA_ "Confidence" SG_ 2024 EPBR_infoAppCrc 0;
BA_ "Confidence" SG_ 2024 EPBR_infoAppGitHash 0;
BA_ "Confidence" SG_ 2024 EPBR_infoBootGitHash 0;
BA_ "Confidence" SG_ 2024 EPBR_infoPlatformType 0;
BA_ "Confidence" SG_ 2024 EPBR_infoBootUdsProtoVersion 0;
BA_ "Confidence" SG_ 2024 EPBR_infoBootCrc 0;
BA_ "Confidence" SG_ 552 EPBR_unitStatus 0;
BA_ "Confidence" SG_ 552 EPBR_unitFaultStatus 0;
BA_ "Confidence" SG_ 552 EPBR_summonState 0;
BA_ "Confidence" SG_ 552 EPBR_disconnected 0;
BA_ "Confidence" SG_ 552 EPBR_pistonTouchingRotor 0;
BA_ "Confidence" SG_ 552 EPBR_csmFaultReason 0;
BA_ "Confidence" SG_ 552 EPBR_esmOperationTrigger 0;
BA_ "Confidence" SG_ 552 EPBR_summonFaultReason 0;
BA_ "Confidence" SG_ 552 EPBR_localServiceModeActive 0;
BA_ "Confidence" SG_ 552 EPBR_localCdpState 0;
BA_ "Confidence" SG_ 552 EPBR_chimeRequestLocal 0;
BA_ "Confidence" SG_ 552 EPBR_telltaleLocal 0;
BA_ "GenSigSNA" SG_ 552 EPBR_telltaleLocal "7";
BA_ "Confidence" SG_ 552 EPBR_driverIsLeavingLocal 0;
BA_ "Confidence" SG_ 552 EPBR_driverIsLeavingAnySpeedLoca 0;
BA_ "SystemSignalLongSymbol" SG_ 552 EPBR_driverIsLeavingAnySpeedLoca "EPBR_driverIsLeavingAnySpeedLocal";
BA_ "Confidence" SG_ 552 EPBR_internalCDPRequest 0;
BA_ "Confidence" SG_ 552 EPBR_esmSpeedClass 0;
BA_ "Confidence" SG_ 552 EPBR_learnedEpbConfig 0;
BA_ "Confidence" SG_ 552 EPBR_internalStatusCounter 0;
BA_ "Confidence" SG_ 552 EPBR_internalStatusChecksum 0;
BA_ "Confidence" SG_ 742 EPBR_frontSeatCushionFanCur 0;
BA_ "Confidence" SG_ 742 EPBR_frontSeatBackrestFanCur 0;
BA_ "Confidence" SG_ 742 EPBR_frontSeatCushionFanDuty 0;
BA_ "Confidence" SG_ 742 EPBR_frontSeatCushionFanEn 0;
BA_ "Confidence" SG_ 742 EPBR_frontSeatBackrestFanEn 0;
BA_ "Confidence" SG_ 742 EPBR_frontSeatBackrestFanDuty 0;
BA_ "Confidence" SG_ 742 EPBR_seat2RControllerCurrent 0;
BA_ "Confidence" SG_ 744 EPBR_systemStatus 0;
BA_ "Confidence" SG_ 744 EPBR_freeRollModeStatus 0;
BA_ "Confidence" SG_ 744 EPBR_driverIsLeaving 0;
BA_ "Confidence" SG_ 744 EPBR_driverIsLeavingAnySpeed 0;
BA_ "Confidence" SG_ 744 EPBR_systemCdpAvailable 0;
BA_ "Confidence" SG_ 744 EPBR_chimeRequest 0;
BA_ "Confidence" SG_ 744 EPBR_telltale 0;
BA_ "GenSigSNA" SG_ 744 EPBR_telltale "7";
BA_ "Confidence" SG_ 744 EPBR_audioCurrentSpikeDetected 0;
BA_ "Confidence" SG_ 744 EPBR_redundantBrakingEnabled 0;
BA_ "Confidence" SG_ 744 EPBR_summonEnabled 0;
BA_ "Confidence" SG_ 744 EPBR_brakeLight 0;
BA_ "Confidence" SG_ 744 EPBR_epbConfigMismatch 0;
BA_ "Confidence" SG_ 744 EPBR_brakeConfirmedPressed 0;
BA_ "Confidence" SG_ 744 EPBR_requestUserConfirmation 0;
BA_ "Confidence" SG_ 744 EPBR_uiWinchModeMiscBlocking 0;
BA_ "Confidence" SG_ 744 EPBR_winchModeActive 0;
BA_ "Confidence" SG_ 744 EPBR_updateMode 0;
BA_ "Confidence" SG_ 744 EPBR_winchModePermissive 0;
BA_ "Confidence" SG_ 744 EPBR_winchModePending 0;
BA_ "Confidence" SG_ 744 EPBR_cdpRequest 0;
BA_ "Confidence" SG_ 744 EPBR_uiParkAvailable 0;
BA_ "Confidence" SG_ 744 EPBR_brakeDiscWipeRequest 0;
BA_ "GenSigSNA" SG_ 744 EPBR_brakeDiscWipeRequest "3";
BA_ "Confidence" SG_ 744 EPBR_showUiGearShifter 0;
BA_ "Confidence" SG_ 744 EPBR_uiWinchModeLvStatus 0;
BA_ "Confidence" SG_ 744 EPBR_contactorCycleNotNeededForW 0;
BA_ "SystemSignalLongSymbol" SG_ 744 EPBR_contactorCycleNotNeededForW "EPBR_contactorCycleNotNeededForWinchEntry";
BA_ "Confidence" SG_ 744 EPBR_autonomyBehavior 0;
BA_ "Confidence" SG_ 744 EPBR_showStalkFaultedOnUi 0;
BA_ "Confidence" SG_ 744 EPBR_espPowerRequest 0;
BA_ "Confidence" SG_ 744 EPBR_okToPark 0;
BA_ "Confidence" SG_ 744 EPBR_hornRequest 0;
BA_ "Confidence" SG_ 744 EPBR_winchModeAvailable 0;
BA_ "Confidence" SG_ 744 EPBR_bothDisconnected 0;
BA_ "Confidence" SG_ 744 EPBR_blockDrive 0;
BA_ "Confidence" SG_ 744 EPBR_statusCounter 0;
BA_ "Confidence" SG_ 744 EPBR_statusChecksum 0;
BA_ "Confidence" SG_ 1662 EVSE_isoTpToVehData 0;
BA_ "Confidence" SG_ 1117 FC_evseBillingDataSelect 1;
BA_ "Confidence" SG_ 1117 FC_evseBillingEnergy 0;
BA_ "Confidence" SG_ 1117 FC_evseMeterPower 0;
BA_ "Confidence" SG_ 1117 FC_evseMeterCurrent 0;
BA_ "Confidence" SG_ 1117 FC_evseMeterVoltage 0;
BA_ "Confidence" SG_ 1117 FC_evseMeterFwGitHash 0;
BA_ "Confidence" SG_ 1334 FC_evseBilling2DataSelect 1;
BA_ "Confidence" SG_ 1334 FC_evsePpuEnabled 0;
BA_ "Confidence" SG_ 1334 FC_evseBillingEnergyHighRes 0;
BA_ "GenSigSNA" SG_ 1334 FC_evseBillingEnergyHighRes "16777215";
BA_ "Confidence" SG_ 1303 FC_id 0;
BA_ "Confidence" SG_ 1303 FC_sessionId 0;
BA_ "Confidence" SG_ 1310 FC_infoIndex 1;
BA_ "Confidence" SG_ 1310 FC_infoBuildType 0;
BA_ "Confidence" SG_ 1310 FC_infoBuildConfigID 0;
BA_ "Confidence" SG_ 1310 FC_infoHardwareID 0;
BA_ "Confidence" SG_ 1310 FC_infoComponentID 0;
BA_ "Confidence" SG_ 1310 FC_infoPcbaID 0;
BA_ "Confidence" SG_ 1310 FC_infoAssemblyID 0;
BA_ "Confidence" SG_ 1310 FC_infoUsageID 0;
BA_ "Confidence" SG_ 1310 FC_infoSubUsageID 0;
BA_ "Confidence" SG_ 1310 FC_infoApplicationCRC 0;
BA_ "Confidence" SG_ 1310 FC_infoAppGitHashBytes 0;
BA_ "Confidence" SG_ 1310 FC_infoBootGitHashBytes 0;
BA_ "Confidence" SG_ 1310 FC_infoPlatformType 0;
BA_ "Confidence" SG_ 1310 FC_infoMajorVersion 0;
BA_ "Confidence" SG_ 1310 FC_infoBranchOrigin 0;
BA_ "Confidence" SG_ 1310 FC_infoMaturity 0;
BA_ "Confidence" SG_ 1310 FC_infoHardwareRevision 0;
BA_ "Confidence" SG_ 1310 FC_partNumChar01 0;
BA_ "Confidence" SG_ 1310 FC_partNumChar02 0;
BA_ "Confidence" SG_ 1310 FC_partNumChar03 0;
BA_ "Confidence" SG_ 1310 FC_partNumChar04 0;
BA_ "Confidence" SG_ 1310 FC_partNumChar05 0;
BA_ "Confidence" SG_ 1310 FC_partNumChar06 0;
BA_ "Confidence" SG_ 1310 FC_partNumChar07 0;
BA_ "Confidence" SG_ 1310 FC_partNumChar08 0;
BA_ "Confidence" SG_ 1310 FC_partNumChar09 0;
BA_ "Confidence" SG_ 1310 FC_partNumChar10 0;
BA_ "Confidence" SG_ 1310 FC_partNumChar11 0;
BA_ "Confidence" SG_ 1310 FC_partNumChar12 0;
BA_ "Confidence" SG_ 1310 FC_partNumChar13 0;
BA_ "Confidence" SG_ 1310 FC_partNumChar14 0;
BA_ "Confidence" SG_ 1310 FC_partNumChar15 0;
BA_ "Confidence" SG_ 1310 FC_partNumChar16 0;
BA_ "Confidence" SG_ 1310 FC_partNumChar17 0;
BA_ "Confidence" SG_ 1310 FC_partNumChar18 0;
BA_ "Confidence" SG_ 1310 FC_partNumChar19 0;
BA_ "Confidence" SG_ 1310 FC_partNumChar20 0;
BA_ "Confidence" SG_ 580 FC_powerLimit 0;
BA_ "GenSigSNA" SG_ 580 FC_powerLimit "8191";
BA_ "Confidence" SG_ 580 FC_currentLimit 0;
BA_ "GenSigSNA" SG_ 580 FC_currentLimit "8191";
BA_ "Confidence" SG_ 580 FC_maxVoltageLimit 0;
BA_ "GenSigSNA" SG_ 580 FC_maxVoltageLimit "8191";
BA_ "Confidence" SG_ 580 FC_minVoltageLimit 0;
BA_ "GenSigSNA" SG_ 580 FC_minVoltageLimit "8191";
BA_ "Confidence" SG_ 702 FC_powerLimit_value 0;
BA_ "GenSigSNA" SG_ 702 FC_powerLimit_value "32768";
BA_ "Confidence" SG_ 702 FC_currentLimit_value 0;
BA_ "GenSigSNA" SG_ 702 FC_currentLimit_value "32768";
BA_ "Confidence" SG_ 702 FC_minVoltageLimit_value 0;
BA_ "GenSigSNA" SG_ 702 FC_minVoltageLimit_value "32768";
BA_ "Confidence" SG_ 702 FC_powerLimit_exp 0;
BA_ "Confidence" SG_ 702 FC_currentLimit_exp 0;
BA_ "Confidence" SG_ 702 FC_minVoltageLimit_exp 0;
BA_ "Confidence" SG_ 1345 FC_maxPowerLimit 0;
BA_ "GenSigSNA" SG_ 1345 FC_maxPowerLimit "8191";
BA_ "Confidence" SG_ 1345 FC_maxCurrentLimit 0;
BA_ "GenSigSNA" SG_ 1345 FC_maxCurrentLimit "8191";
BA_ "Confidence" SG_ 1300 FC_serialDataSelect 1;
BA_ "Confidence" SG_ 1300 FC_serialChar01 0;
BA_ "Confidence" SG_ 1300 FC_serialChar02 0;
BA_ "Confidence" SG_ 1300 FC_serialChar03 0;
BA_ "Confidence" SG_ 1300 FC_serialChar04 0;
BA_ "Confidence" SG_ 1300 FC_serialChar05 0;
BA_ "Confidence" SG_ 1300 FC_serialChar06 0;
BA_ "Confidence" SG_ 1300 FC_serialChar07 0;
BA_ "Confidence" SG_ 1300 FC_serialChar08 0;
BA_ "Confidence" SG_ 1300 FC_serialChar09 0;
BA_ "Confidence" SG_ 1300 FC_serialChar10 0;
BA_ "Confidence" SG_ 1300 FC_serialChar11 0;
BA_ "Confidence" SG_ 1300 FC_serialChar12 0;
BA_ "Confidence" SG_ 1300 FC_serialChar13 0;
BA_ "Confidence" SG_ 1300 FC_serialChar14 0;
BA_ "Confidence" SG_ 1300 FC_serialChar15 0;
BA_ "Confidence" SG_ 1300 FC_serialChar16 0;
BA_ "Confidence" SG_ 1300 FC_serialChar17 0;
BA_ "Confidence" SG_ 532 FC_protocolVersion 0;
BA_ "Confidence" SG_ 532 FC_statusCode 0;
BA_ "GenSigSNA" SG_ 532 FC_statusCode "0";
BA_ "Confidence" SG_ 532 FC_deprecated1 0;
BA_ "Confidence" SG_ 532 FC_deprecated2 0;
BA_ "Confidence" SG_ 532 FC_deprecated3 0;
BA_ "Confidence" SG_ 532 FC_adapterLocked 0;
BA_ "Confidence" SG_ 532 FC_minCurrentLimit 0;
BA_ "Confidence" SG_ 532 FC_type 0;
BA_ "GenSigSNA" SG_ 532 FC_type "7";
BA_ "Confidence" SG_ 532 FC_dcCurrent 0;
BA_ "Confidence" SG_ 532 FC_postID 0;
BA_ "GenSigSNA" SG_ 532 FC_postID "3";
BA_ "Confidence" SG_ 532 FC_dcVoltage 0;
BA_ "Confidence" SG_ 532 FC_leakageTestNotSupported 0;
BA_ "Confidence" SG_ 532 FC_dischargeSupported 0;
BA_ "Confidence" SG_ 533 FC_externalIsolationResistance 0;
BA_ "GenSigSNA" SG_ 533 FC_externalIsolationResistance "255";
BA_ "Confidence" SG_ 535 FC_status3DataSelect 1;
BA_ "Confidence" SG_ 535 FC_status3DummySig 0;
BA_ "Confidence" SG_ 535 FC_class 0;
BA_ "GenSigSNA" SG_ 535 FC_class "0";
BA_ "Confidence" SG_ 535 FC_brand 0;
BA_ "GenSigSNA" SG_ 535 FC_brand "0";
BA_ "Confidence" SG_ 535 FC_coolingType 0;
BA_ "GenSigSNA" SG_ 535 FC_coolingType "0";
BA_ "Confidence" SG_ 535 FC_uiStopType 0;
BA_ "GenSigSNA" SG_ 535 FC_uiStopType "0";
BA_ "Confidence" SG_ 535 FC_emergencyShutdownSupported 0;
BA_ "Confidence" SG_ 535 FC_generation 0;
BA_ "GenSigSNA" SG_ 535 FC_generation "0";
BA_ "Confidence" SG_ 1650 VC_hcmlInfoIndex 1;
BA_ "Confidence" SG_ 1650 VC_infoHCMLBuildConfigId 0;
BA_ "Confidence" SG_ 1650 VC_leftHeadlampLMMVariant 0;
BA_ "GenSigSNA" SG_ 1650 VC_leftHeadlampLMMVariant "0";
BA_ "Confidence" SG_ 1650 VC_infoHCMLAssemblyId 0;
BA_ "Confidence" SG_ 1650 VC_infoHCMLPcbaId 0;
BA_ "Confidence" SG_ 1650 VC_infoHCMLUsageId 0;
BA_ "Confidence" SG_ 1980 VC_hcmrInfoIndex 1;
BA_ "Confidence" SG_ 1980 VC_infoHCMRBuildConfigId 0;
BA_ "Confidence" SG_ 1980 VC_rightHeadlampLMMVariant 0;
BA_ "GenSigSNA" SG_ 1980 VC_rightHeadlampLMMVariant "0";
BA_ "Confidence" SG_ 1980 VC_infoHCMRAssemblyId 0;
BA_ "Confidence" SG_ 1980 VC_infoHCMRPcbaId 0;
BA_ "Confidence" SG_ 1980 VC_infoHCMRUsageId 0;
BA_ "Confidence" SG_ 522 HVP_packContNegativeState 0;
BA_ "GenSigSNA" SG_ 522 HVP_packContNegativeState "0";
BA_ "Confidence" SG_ 522 HVP_packContPositiveState 0;
BA_ "GenSigSNA" SG_ 522 HVP_packContPositiveState "0";
BA_ "Confidence" SG_ 522 HVP_fcContPositiveAuxOpen 0;
BA_ "Confidence" SG_ 522 HVP_fcContNegativeAuxOpen 0;
BA_ "Confidence" SG_ 522 HVP_packContactorSetState 0;
BA_ "GenSigSNA" SG_ 522 HVP_packContactorSetState "0";
BA_ "Confidence" SG_ 522 HVP_fcContNegativeState 0;
BA_ "GenSigSNA" SG_ 522 HVP_fcContNegativeState "0";
BA_ "Confidence" SG_ 522 HVP_contactorsBlocked 0;
BA_ "Confidence" SG_ 522 HVP_fcContPositiveState 0;
BA_ "GenSigSNA" SG_ 522 HVP_fcContPositiveState "0";
BA_ "Confidence" SG_ 522 HVP_fcContactorSetState 0;
BA_ "GenSigSNA" SG_ 522 HVP_fcContactorSetState "0";
BA_ "Confidence" SG_ 522 HVP_fcCtrsRequestStatus 0;
BA_ "Confidence" SG_ 522 HVP_fcCtrsResetRequestRequired 0;
BA_ "Confidence" SG_ 522 HVP_fcCtrsOpenNowRequested 0;
BA_ "Confidence" SG_ 522 HVP_fcCtrsOpenRequested 0;
BA_ "Confidence" SG_ 522 HVP_fcCtrsClosingAllowed 0;
BA_ "Confidence" SG_ 522 HVP_packCtrsRequestStatus 0;
BA_ "Confidence" SG_ 522 HVP_packCtrsResetRequestRequired 0;
BA_ "Confidence" SG_ 522 HVP_packCtrsOpenNowRequested 0;
BA_ "Confidence" SG_ 522 HVP_packCtrsOpenRequested 0;
BA_ "Confidence" SG_ 522 HVP_packCtrsClosingAllowed 0;
BA_ "Confidence" SG_ 522 HVP_dcLinkAllowedToEnergize 0;
BA_ "Confidence" SG_ 522 HVP_pyroTestInProgress 0;
BA_ "Confidence" SG_ 522 HVP_hvilDiag 0;
BA_ "GenSigSNA" SG_ 522 HVP_hvilDiag "14";
BA_ "Confidence" SG_ 522 HVP_fcLinkAllowedToEnergize 0;
BA_ "Confidence" SG_ 1962 HVP_debugMessageMultiplexer 1;
BA_ "Confidence" SG_ 1962 HVP_ecuLogUploadRequest 0;
BA_ "Confidence" SG_ 1962 HVP_dcLinkVoltage 0;
BA_ "Confidence" SG_ 1962 HVP_packVoltage 0;
BA_ "Confidence" SG_ 1962 HVP_fcLinkVoltage 0;
BA_ "Confidence" SG_ 1962 HVP_10HzTask_stackUsage 0;
BA_ "Confidence" SG_ 1962 HVP_packContVoltage 0;
BA_ "Confidence" SG_ 1962 HVP_packNegativeV 0;
BA_ "Confidence" SG_ 1962 HVP_packPositiveV 0;
BA_ "Confidence" SG_ 1962 HVP_pyroAnalog 0;
BA_ "Confidence" SG_ 1962 HVP_shuntSetTCRCoeffA 0;
BA_ "Confidence" SG_ 1962 HVP_shuntSetTCRCoeffB 0;
BA_ "Confidence" SG_ 1962 HVP_shuntSetTCRCoeffC 0;
BA_ "Confidence" SG_ 1962 HVP_shuntSetTCRCoeffD 0;
BA_ "Confidence" SG_ 1962 HVP_fcContCoilCurrent 0;
BA_ "Confidence" SG_ 1962 HVP_fcContVoltage 0;
BA_ "Confidence" SG_ 1962 HVP_hvilInVoltage 0;
BA_ "Confidence" SG_ 1962 HVP_hvilOutVoltage 0;
BA_ "Confidence" SG_ 1962 HVP_shuntGainInvalidCountDbg 0;
BA_ "Confidence" SG_ 1962 HVP_passivePyroRefVoltageMax 0;
BA_ "GenSigSNA" SG_ 1962 HVP_passivePyroRefVoltageMax "1023";
BA_ "Confidence" SG_ 1962 HVP_passivePyroRefVoltageMin 0;
BA_ "GenSigSNA" SG_ 1962 HVP_passivePyroRefVoltageMin "1023";
BA_ "Confidence" SG_ 1962 HVP_packContCoilCurrent 0;
BA_ "Confidence" SG_ 1962 HVP_battery12V 0;
BA_ "Confidence" SG_ 1962 HVP_fcLinkPositiveV 0;
BA_ "Confidence" SG_ 554 HVP_dcLinkVoltageRequest 0;
BA_ "Confidence" SG_ 554 HVP_pcsControlRequest 0;
BA_ "Confidence" SG_ 554 HVP_pcsChargeHwEnabled 0;
BA_ "Confidence" SG_ 554 HVP_pcsDcdcHwEnabled 0;
BA_ "Confidence" SG_ 554 HVP_dcLinkVoltageFiltered 0;
BA_ "GenSigSNA" SG_ 554 HVP_dcLinkVoltageFiltered "1498";
BA_ "Confidence" SG_ 784 HVP_infoIndex 1;
BA_ "Confidence" SG_ 784 HVP_buildType 0;
BA_ "Confidence" SG_ 784 HVP_buildConfigId 0;
BA_ "Confidence" SG_ 784 HVP_hardwareId 0;
BA_ "Confidence" SG_ 784 HVP_componentId 0;
BA_ "Confidence" SG_ 784 HVP_pcbaId 0;
BA_ "Confidence" SG_ 784 HVP_assemblyId 0;
BA_ "Confidence" SG_ 784 HVP_usageId 0;
BA_ "Confidence" SG_ 784 HVP_subUsageId 0;
BA_ "Confidence" SG_ 784 HVP_platformType 0;
BA_ "Confidence" SG_ 784 HVP_appCrc 0;
BA_ "Confidence" SG_ 784 HVP_appGitHash 0;
BA_ "Confidence" SG_ 784 HVP_bootGitHash 0;
BA_ "Confidence" SG_ 784 HVP_bootUdsProtoVersion 0;
BA_ "Confidence" SG_ 784 HVP_bootCrc 0;
BA_ "Confidence" SG_ 1914 HVP_log1HzIndex 1;
BA_ "Confidence" SG_ 1914 HVP_bmbAsicType 0;
BA_ "Confidence" SG_ 1914 HVP_shuntCurrentAuxLog 0;
BA_ "Confidence" SG_ 1914 HVP_pyroSquibResistance 0;
BA_ "GenSigSNA" SG_ 1914 HVP_pyroSquibResistance "65535";
BA_ "Confidence" SG_ 1914 HVP_shuntAsicChipXCoordinate 0;
BA_ "Confidence" SG_ 1914 HVP_shuntAsicChipYCoordinate 0;
BA_ "Confidence" SG_ 1914 HVP_hvilCalType 0;
BA_ "Confidence" SG_ 1914 HVP_gpioPcsDcdcPwmEnable 0;
BA_ "Confidence" SG_ 1914 HVP_gpioPcsChargePwmEnable 0;
BA_ "Confidence" SG_ 1914 HVP_gpioPcsEnable 0;
BA_ "Confidence" SG_ 1914 HVP_shuntAsicChipWaferNumber 0;
BA_ "Confidence" SG_ 1914 HVP_energyReserveMin 0;
BA_ "Confidence" SG_ 1914 HVP_energyReserveMax 0;
BA_ "Confidence" SG_ 1914 HVP_energyReserveAvg 0;
BA_ "Confidence" SG_ 941 ICR_infoIndex 1;
BA_ "Confidence" SG_ 941 ICR_infoBuildType 0;
BA_ "Confidence" SG_ 941 ICR_infoPcbaId 0;
BA_ "Confidence" SG_ 941 ICR_infoAssemblyId 0;
BA_ "Confidence" SG_ 941 ICR_infoUsageId 0;
BA_ "Confidence" SG_ 941 ICR_infoAppCrc 0;
BA_ "Confidence" SG_ 941 ICR_infoBoardPartNumber17 0;
BA_ "Confidence" SG_ 941 ICR_infoBoardPartNumber814 0;
BA_ "Confidence" SG_ 941 ICR_infoBoardPartNumber1520 0;
BA_ "Confidence" SG_ 667 ICR_lifePresenceMLOutput 0;
BA_ "GenSigSNA" SG_ 667 ICR_lifePresenceMLOutput "255";
BA_ "Confidence" SG_ 667 ICR_largeOccupantPresenceMLOutpu 0;
BA_ "GenSigSNA" SG_ 667 ICR_largeOccupantPresenceMLOutpu "255";
BA_ "SystemSignalLongSymbol" SG_ 667 ICR_largeOccupantPresenceMLOutpu "ICR_largeOccupantPresenceMLOutput";
BA_ "Confidence" SG_ 667 ICR_lifePresenceRaw 0;
BA_ "GenSigSNA" SG_ 667 ICR_lifePresenceRaw "0";
BA_ "Confidence" SG_ 667 ICR_lifePresenceFilt 0;
BA_ "GenSigSNA" SG_ 667 ICR_lifePresenceFilt "0";
BA_ "Confidence" SG_ 667 ICR_largeOccupantPresenceRaw 0;
BA_ "GenSigSNA" SG_ 667 ICR_largeOccupantPresenceRaw "3";
BA_ "Confidence" SG_ 667 ICR_largeOccupantPresenceFilt 0;
BA_ "GenSigSNA" SG_ 667 ICR_largeOccupantPresenceFilt "3";
BA_ "Confidence" SG_ 667 ICR_childPresenceFunctionality 0;
BA_ "GenSigSNA" SG_ 667 ICR_childPresenceFunctionality "2";
BA_ "Confidence" SG_ 667 ICR_userPresenceFunctionality 0;
BA_ "GenSigSNA" SG_ 667 ICR_userPresenceFunctionality "2";
BA_ "Confidence" SG_ 667 ICR_userPresenceMLOutput 0;
BA_ "GenSigSNA" SG_ 667 ICR_userPresenceMLOutput "255";
BA_ "Confidence" SG_ 667 ICR_userPresenceRaw 0;
BA_ "GenSigSNA" SG_ 667 ICR_userPresenceRaw "3";
BA_ "Confidence" SG_ 667 ICR_userPresenceFilt 0;
BA_ "GenSigSNA" SG_ 667 ICR_userPresenceFilt "3";
BA_ "Confidence" SG_ 536 ICR_occupancy1LRaw 0;
BA_ "GenSigSNA" SG_ 536 ICR_occupancy1LRaw "3";
BA_ "Confidence" SG_ 536 ICR_occupancy1RRaw 0;
BA_ "GenSigSNA" SG_ 536 ICR_occupancy1RRaw "3";
BA_ "Confidence" SG_ 536 ICR_occupancy1LVoteCnt 0;
BA_ "Confidence" SG_ 536 ICR_occupancy1RVoteCnt 0;
BA_ "Confidence" SG_ 536 ICR_occupancy1LFilt 0;
BA_ "GenSigSNA" SG_ 536 ICR_occupancy1LFilt "3";
BA_ "Confidence" SG_ 536 ICR_occupancy1RFilt 0;
BA_ "GenSigSNA" SG_ 536 ICR_occupancy1RFilt "3";
BA_ "Confidence" SG_ 536 ICR_occupancy2LFilt 0;
BA_ "GenSigSNA" SG_ 536 ICR_occupancy2LFilt "3";
BA_ "Confidence" SG_ 536 ICR_occupancy2CFilt 0;
BA_ "GenSigSNA" SG_ 536 ICR_occupancy2CFilt "3";
BA_ "Confidence" SG_ 536 ICR_occupancy2RFilt 0;
BA_ "GenSigSNA" SG_ 536 ICR_occupancy2RFilt "3";
BA_ "Confidence" SG_ 536 ICR_occupancy1RFiltExp 0;
BA_ "GenSigSNA" SG_ 536 ICR_occupancy1RFiltExp "3";
BA_ "Confidence" SG_ 536 ICR_occupancyCounter 0;
BA_ "Confidence" SG_ 536 ICR_occupancyChecksum 0;
BA_ "Confidence" SG_ 670 ICR_classification1RFilt 0;
BA_ "GenSigSNA" SG_ 670 ICR_classification1RFilt "0";
BA_ "Confidence" SG_ 670 ICR_classification1LRaw 0;
BA_ "GenSigSNA" SG_ 670 ICR_classification1LRaw "0";
BA_ "Confidence" SG_ 670 ICR_classification1RRaw 0;
BA_ "GenSigSNA" SG_ 670 ICR_classification1RRaw "0";
BA_ "Confidence" SG_ 670 ICR_classification1LMLOutput 0;
BA_ "GenSigSNA" SG_ 670 ICR_classification1LMLOutput "255";
BA_ "Confidence" SG_ 670 ICR_classification1RMLOutput 0;
BA_ "GenSigSNA" SG_ 670 ICR_classification1RMLOutput "255";
BA_ "Confidence" SG_ 670 ICR_classification1LqF 0;
BA_ "Confidence" SG_ 670 ICR_blockageClutterFar 0;
BA_ "GenSigSNA" SG_ 670 ICR_blockageClutterFar "16";
BA_ "Confidence" SG_ 670 ICR_blockageClutterNear 0;
BA_ "GenSigSNA" SG_ 670 ICR_blockageClutterNear "16";
BA_ "Confidence" SG_ 670 ICR_classification1LFilt 0;
BA_ "GenSigSNA" SG_ 670 ICR_classification1LFilt "0";
BA_ "Confidence" SG_ 670 ICR_classification1RqF 0;
BA_ "Confidence" SG_ 670 ICR_classification1LLatched 0;
BA_ "GenSigSNA" SG_ 670 ICR_classification1LLatched "0";
BA_ "Confidence" SG_ 670 ICR_classification1RLatched 0;
BA_ "GenSigSNA" SG_ 670 ICR_classification1RLatched "0";
BA_ "Confidence" SG_ 670 ICR_classification1LIsLatched 0;
BA_ "Confidence" SG_ 670 ICR_classification1RIsLatched 0;
BA_ "Confidence" SG_ 670 ICR_occupancy2Counter 0;
BA_ "Confidence" SG_ 670 ICR_occupancy2Checksum 0;
BA_ "Confidence" SG_ 664 ICR_sensorMode 0;
BA_ "Confidence" SG_ 664 ICR_blocked 0;
BA_ "GenSigSNA" SG_ 664 ICR_blocked "0";
BA_ "Confidence" SG_ 664 ICR_booted 0;
BA_ "Confidence" SG_ 664 ICR_rdMapDumpCompleted 0;
BA_ "Confidence" SG_ 664 ICR_algoVersion 0;
BA_ "Confidence" SG_ 664 ICR_l2HeapUsage 0;
BA_ "Confidence" SG_ 664 ICR_intrusionStatus 0;
BA_ "Confidence" SG_ 664 ICR_blockageScaledMLOutput 0;
BA_ "Confidence" SG_ 1012 LS_lightShowIndex 1;
BA_ "Confidence" SG_ 1012 LS_lightLeftRampedChannel1Reques 0;
BA_ "SystemSignalLongSymbol" SG_ 1012 LS_lightLeftRampedChannel1Reques "LS_lightLeftRampedChannel1Request";
BA_ "Confidence" SG_ 1012 LS_lightLeftRampedChannel1Durati 0;
BA_ "SystemSignalLongSymbol" SG_ 1012 LS_lightLeftRampedChannel1Durati "LS_lightLeftRampedChannel1Duration";
BA_ "Confidence" SG_ 1012 LS_lightLeftRampedChannel2Reques 0;
BA_ "SystemSignalLongSymbol" SG_ 1012 LS_lightLeftRampedChannel2Reques "LS_lightLeftRampedChannel2Request";
BA_ "Confidence" SG_ 1012 LS_lightLeftRampedChannel2Durati 0;
BA_ "SystemSignalLongSymbol" SG_ 1012 LS_lightLeftRampedChannel2Durati "LS_lightLeftRampedChannel2Duration";
BA_ "Confidence" SG_ 1012 LS_lightLeftRampedChannel3Reques 0;
BA_ "SystemSignalLongSymbol" SG_ 1012 LS_lightLeftRampedChannel3Reques "LS_lightLeftRampedChannel3Request";
BA_ "Confidence" SG_ 1012 LS_lightLeftRampedChannel3Durati 0;
BA_ "SystemSignalLongSymbol" SG_ 1012 LS_lightLeftRampedChannel3Durati "LS_lightLeftRampedChannel3Duration";
BA_ "Confidence" SG_ 1012 LS_lightLeftRampedChannel4Reques 0;
BA_ "SystemSignalLongSymbol" SG_ 1012 LS_lightLeftRampedChannel4Reques "LS_lightLeftRampedChannel4Request";
BA_ "Confidence" SG_ 1012 LS_lightLeftRampedChannel4Durati 0;
BA_ "SystemSignalLongSymbol" SG_ 1012 LS_lightLeftRampedChannel4Durati "LS_lightLeftRampedChannel4Duration";
BA_ "Confidence" SG_ 1012 LS_lightLeftRampedChannel5Reques 0;
BA_ "SystemSignalLongSymbol" SG_ 1012 LS_lightLeftRampedChannel5Reques "LS_lightLeftRampedChannel5Request";
BA_ "Confidence" SG_ 1012 LS_lightLeftRampedChannel5Durati 0;
BA_ "SystemSignalLongSymbol" SG_ 1012 LS_lightLeftRampedChannel5Durati "LS_lightLeftRampedChannel5Duration";
BA_ "Confidence" SG_ 1012 LS_lightLeftRampedChannel6Reques 0;
BA_ "SystemSignalLongSymbol" SG_ 1012 LS_lightLeftRampedChannel6Reques "LS_lightLeftRampedChannel6Request";
BA_ "Confidence" SG_ 1012 LS_lightLeftRampedChannel6Durati 0;
BA_ "SystemSignalLongSymbol" SG_ 1012 LS_lightLeftRampedChannel6Durati "LS_lightLeftRampedChannel6Duration";
BA_ "Confidence" SG_ 1012 LS_lightLeftRampedChannel7Reques 0;
BA_ "SystemSignalLongSymbol" SG_ 1012 LS_lightLeftRampedChannel7Reques "LS_lightLeftRampedChannel7Request";
BA_ "Confidence" SG_ 1012 LS_lightLeftRampedChannel7Durati 0;
BA_ "SystemSignalLongSymbol" SG_ 1012 LS_lightLeftRampedChannel7Durati "LS_lightLeftRampedChannel7Duration";
BA_ "Confidence" SG_ 1012 LS_lightRightRampedChannel1Reque 0;
BA_ "SystemSignalLongSymbol" SG_ 1012 LS_lightRightRampedChannel1Reque "LS_lightRightRampedChannel1Request";
BA_ "Confidence" SG_ 1012 LS_lightRightRampedChannel1Durat 0;
BA_ "GenSigSNA" SG_ 1012 LS_lightRightRampedChannel1Durat "1";
BA_ "SystemSignalLongSymbol" SG_ 1012 LS_lightRightRampedChannel1Durat "LS_lightRightRampedChannel1Duration";
BA_ "Confidence" SG_ 1012 LS_lightRightRampedChannel2Reque 0;
BA_ "SystemSignalLongSymbol" SG_ 1012 LS_lightRightRampedChannel2Reque "LS_lightRightRampedChannel2Request";
BA_ "Confidence" SG_ 1012 LS_lightRightRampedChannel2Durat 0;
BA_ "GenSigSNA" SG_ 1012 LS_lightRightRampedChannel2Durat "1";
BA_ "SystemSignalLongSymbol" SG_ 1012 LS_lightRightRampedChannel2Durat "LS_lightRightRampedChannel2Duration";
BA_ "Confidence" SG_ 1012 LS_lightRightRampedChannel3Reque 0;
BA_ "SystemSignalLongSymbol" SG_ 1012 LS_lightRightRampedChannel3Reque "LS_lightRightRampedChannel3Request";
BA_ "Confidence" SG_ 1012 LS_lightRightRampedChannel3Durat 0;
BA_ "SystemSignalLongSymbol" SG_ 1012 LS_lightRightRampedChannel3Durat "LS_lightRightRampedChannel3Duration";
BA_ "Confidence" SG_ 1012 LS_lightRightRampedChannel4Reque 0;
BA_ "SystemSignalLongSymbol" SG_ 1012 LS_lightRightRampedChannel4Reque "LS_lightRightRampedChannel4Request";
BA_ "Confidence" SG_ 1012 LS_lightRightRampedChannel4Durat 0;
BA_ "SystemSignalLongSymbol" SG_ 1012 LS_lightRightRampedChannel4Durat "LS_lightRightRampedChannel4Duration";
BA_ "Confidence" SG_ 1012 LS_lightRightRampedChannel5Reque 0;
BA_ "SystemSignalLongSymbol" SG_ 1012 LS_lightRightRampedChannel5Reque "LS_lightRightRampedChannel5Request";
BA_ "Confidence" SG_ 1012 LS_lightRightRampedChannel5Durat 0;
BA_ "SystemSignalLongSymbol" SG_ 1012 LS_lightRightRampedChannel5Durat "LS_lightRightRampedChannel5Duration";
BA_ "Confidence" SG_ 1012 LS_lightRightRampedChannel6Reque 0;
BA_ "SystemSignalLongSymbol" SG_ 1012 LS_lightRightRampedChannel6Reque "LS_lightRightRampedChannel6Request";
BA_ "Confidence" SG_ 1012 LS_lightRightRampedChannel6Durat 0;
BA_ "SystemSignalLongSymbol" SG_ 1012 LS_lightRightRampedChannel6Durat "LS_lightRightRampedChannel6Duration";
BA_ "Confidence" SG_ 1012 LS_lightRightRampedChannel7Reque 0;
BA_ "SystemSignalLongSymbol" SG_ 1012 LS_lightRightRampedChannel7Reque "LS_lightRightRampedChannel7Request";
BA_ "Confidence" SG_ 1012 LS_lightRightRampedChannel7Durat 0;
BA_ "SystemSignalLongSymbol" SG_ 1012 LS_lightRightRampedChannel7Durat "LS_lightRightRampedChannel7Duration";
BA_ "Confidence" SG_ 1012 LS_lightRearTurnLeftRequest 0;
BA_ "Confidence" SG_ 1012 LS_lightRearTurnRightRequest 0;
BA_ "Confidence" SG_ 1012 LS_lightSideRepeaterLeftRequest 0;
BA_ "Confidence" SG_ 1012 LS_lightSideRepeaterRightRequest 0;
BA_ "Confidence" SG_ 1012 LS_lightSideMarkerLeftRequest 0;
BA_ "Confidence" SG_ 1012 LS_lightSideMarkerRightRequest 0;
BA_ "Confidence" SG_ 1012 LS_lightFrontFogLeftRequest 0;
BA_ "Confidence" SG_ 1012 LS_lightFrontFogRightRequest 0;
BA_ "Confidence" SG_ 1012 LS_lightRearFogRequest 0;
BA_ "Confidence" SG_ 1012 LS_lightBrakeRequest 0;
BA_ "Confidence" SG_ 1012 LS_lightTailLeftRequest 0;
BA_ "Confidence" SG_ 1012 LS_lightTailRightRequest 0;
BA_ "Confidence" SG_ 1012 LS_lightLicensePlateRequest 0;
BA_ "Confidence" SG_ 1012 LS_lightReverseRequest 0;
BA_ "Confidence" SG_ 1012 LS_lightAuxParkLeftRequest 0;
BA_ "Confidence" SG_ 1012 LS_lightAuxParkRightRequest 0;
BA_ "Confidence" SG_ 1012 LS_mirrorRequestLeft 0;
BA_ "Confidence" SG_ 1012 LS_mirrorRequestRight 0;
BA_ "Confidence" SG_ 1012 LS_liftgateRequest 0;
BA_ "Confidence" SG_ 1012 LS_windowRequestLF 0;
BA_ "Confidence" SG_ 1012 LS_windowRequestLR 0;
BA_ "Confidence" SG_ 1012 LS_windowRequestRF 0;
BA_ "Confidence" SG_ 1012 LS_windowRequestRR 0;
BA_ "Confidence" SG_ 1012 LS_presentingHandleRequestLF 0;
BA_ "Confidence" SG_ 1012 LS_presentingHandleRequestLR 0;
BA_ "Confidence" SG_ 1012 LS_presentingHandleRequestRF 0;
BA_ "Confidence" SG_ 1012 LS_presentingHandleRequestRR 0;
BA_ "Confidence" SG_ 1012 LS_powerFrontDoorRequestLeft 0;
BA_ "Confidence" SG_ 1012 LS_powerFrontDoorRequestRight 0;
BA_ "Confidence" SG_ 1012 LS_falconDoorRequestLeft 0;
BA_ "Confidence" SG_ 1012 LS_falconDoorRequestRight 0;
BA_ "Confidence" SG_ 1012 LS_chargePortRequest 0;
BA_ "GenSigSNA" SG_ 1012 LS_chargePortRequest "3";
BA_ "Confidence" SG_ 1012 LS_chargePortRaveRequest 0;
BA_ "Confidence" SG_ 1012 LS_suspensionRequest 0;
BA_ "GenSigSNA" SG_ 1012 LS_suspensionRequest "3";
BA_ "Confidence" SG_ 1012 LS_rgbIPFLRed 0;
BA_ "Confidence" SG_ 1012 LS_rgbIPFLGreen 0;
BA_ "Confidence" SG_ 1012 LS_rgbIPFLBlue 0;
BA_ "Confidence" SG_ 1012 LS_rgbIPFRRed 0;
BA_ "Confidence" SG_ 1012 LS_rgbIPFRGreen 0;
BA_ "Confidence" SG_ 1012 LS_rgbIPFRBlue 0;
BA_ "Confidence" SG_ 1012 LS_rgbDoorFLForeRed 0;
BA_ "Confidence" SG_ 1012 LS_rgbDoorFLForeGreen 0;
BA_ "Confidence" SG_ 1012 LS_rgbDoorFLForeBlue 0;
BA_ "Confidence" SG_ 1012 LS_rgbDoorFLAftRed 0;
BA_ "Confidence" SG_ 1012 LS_rgbDoorFLAftGreen 0;
BA_ "Confidence" SG_ 1012 LS_rgbDoorFLAftBlue 0;
BA_ "Confidence" SG_ 1012 LS_rgbDoorFRForeRed 0;
BA_ "Confidence" SG_ 1012 LS_rgbDoorFRForeGreen 0;
BA_ "Confidence" SG_ 1012 LS_rgbDoorFRForeBlue 0;
BA_ "Confidence" SG_ 1012 LS_rgbDoorFRAftRed 0;
BA_ "Confidence" SG_ 1012 LS_rgbDoorFRAftGreen 0;
BA_ "Confidence" SG_ 1012 LS_rgbDoorFRAftBlue 0;
BA_ "Confidence" SG_ 1012 LS_rgbDoorRLForeRed 0;
BA_ "Confidence" SG_ 1012 LS_rgbDoorRLForeGreen 0;
BA_ "Confidence" SG_ 1012 LS_rgbDoorRLForeBlue 0;
BA_ "Confidence" SG_ 1012 LS_rgbDoorRLAftRed 0;
BA_ "Confidence" SG_ 1012 LS_rgbDoorRLAftGreen 0;
BA_ "Confidence" SG_ 1012 LS_rgbDoorRLAftBlue 0;
BA_ "Confidence" SG_ 1012 LS_rgbDoorRRForeRed 0;
BA_ "Confidence" SG_ 1012 LS_rgbDoorRRForeGreen 0;
BA_ "Confidence" SG_ 1012 LS_rgbDoorRRForeBlue 0;
BA_ "Confidence" SG_ 1012 LS_rgbDoorRRAftRed 0;
BA_ "Confidence" SG_ 1012 LS_rgbDoorRRAftGreen 0;
BA_ "Confidence" SG_ 1012 LS_rgbDoorRRAftBlue 0;
BA_ "Confidence" SG_ 1012 LS_frontMatrix0 0;
BA_ "Confidence" SG_ 1012 LS_frontMatrix1 0;
BA_ "Confidence" SG_ 1012 LS_frontMatrix2 0;
BA_ "Confidence" SG_ 1012 LS_frontMatrix3 0;
BA_ "Confidence" SG_ 1012 LS_frontMatrix4 0;
BA_ "Confidence" SG_ 1012 LS_frontMatrix5 0;
BA_ "Confidence" SG_ 1012 LS_frontMatrix6 0;
BA_ "Confidence" SG_ 1012 LS_frontMatrix7 0;
BA_ "Confidence" SG_ 1012 LS_frontMatrix8 0;
BA_ "Confidence" SG_ 1012 LS_frontMatrix9 0;
BA_ "Confidence" SG_ 1012 LS_frontMatrix10 0;
BA_ "Confidence" SG_ 1012 LS_frontMatrix11 0;
BA_ "Confidence" SG_ 1012 LS_frontMatrix12 0;
BA_ "Confidence" SG_ 1012 LS_frontMatrix13 0;
BA_ "Confidence" SG_ 1012 LS_frontMatrix14 0;
BA_ "Confidence" SG_ 1012 LS_frontMatrix15 0;
BA_ "Confidence" SG_ 1012 LS_frontMatrix16 0;
BA_ "Confidence" SG_ 1012 LS_frontMatrix17 0;
BA_ "Confidence" SG_ 1012 LS_frontMatrix18 0;
BA_ "Confidence" SG_ 1012 LS_frontMatrix19 0;
BA_ "Confidence" SG_ 1012 LS_frontMatrix20 0;
BA_ "Confidence" SG_ 1012 LS_frontMatrix21 0;
BA_ "Confidence" SG_ 1012 LS_frontMatrix22 0;
BA_ "Confidence" SG_ 1012 LS_frontMatrix23 0;
BA_ "Confidence" SG_ 1012 LS_frontMatrix24 0;
BA_ "Confidence" SG_ 1012 LS_frontMatrix25 0;
BA_ "Confidence" SG_ 1012 LS_frontMatrix26 0;
BA_ "Confidence" SG_ 1012 LS_frontMatrix27 0;
BA_ "Confidence" SG_ 1012 LS_frontMatrix28 0;
BA_ "Confidence" SG_ 1012 LS_frontMatrix29 0;
BA_ "Confidence" SG_ 1012 LS_frontMatrix30 0;
BA_ "Confidence" SG_ 1012 LS_frontMatrix31 0;
BA_ "Confidence" SG_ 1012 LS_frontMatrix32 0;
BA_ "Confidence" SG_ 1012 LS_frontMatrix33 0;
BA_ "Confidence" SG_ 1012 LS_frontMatrix34 0;
BA_ "Confidence" SG_ 1012 LS_frontMatrix35 0;
BA_ "Confidence" SG_ 1012 LS_frontMatrix36 0;
BA_ "Confidence" SG_ 1012 LS_frontMatrix37 0;
BA_ "Confidence" SG_ 1012 LS_frontMatrix38 0;
BA_ "Confidence" SG_ 1012 LS_frontMatrix39 0;
BA_ "Confidence" SG_ 1012 LS_frontMatrix40 0;
BA_ "Confidence" SG_ 1012 LS_frontMatrix41 0;
BA_ "Confidence" SG_ 1012 LS_frontMatrix42 0;
BA_ "Confidence" SG_ 1012 LS_frontMatrix43 0;
BA_ "Confidence" SG_ 1012 LS_frontMatrix44 0;
BA_ "Confidence" SG_ 1012 LS_frontMatrix45 0;
BA_ "Confidence" SG_ 1012 LS_frontMatrix46 0;
BA_ "Confidence" SG_ 1012 LS_frontMatrix47 0;
BA_ "Confidence" SG_ 1012 LS_frontMatrix48 0;
BA_ "Confidence" SG_ 1012 LS_frontMatrix49 0;
BA_ "Confidence" SG_ 1012 LS_frontMatrix50 0;
BA_ "Confidence" SG_ 1012 LS_frontMatrix51 0;
BA_ "Confidence" SG_ 1012 LS_frontMatrix52 0;
BA_ "Confidence" SG_ 1012 LS_frontMatrix53 0;
BA_ "Confidence" SG_ 1012 LS_frontMatrix54 0;
BA_ "Confidence" SG_ 1012 LS_frontMatrix55 0;
BA_ "Confidence" SG_ 1012 LS_frontMatrix56 0;
BA_ "Confidence" SG_ 1012 LS_frontMatrix57 0;
BA_ "Confidence" SG_ 1012 LS_frontMatrix58 0;
BA_ "Confidence" SG_ 1012 LS_frontMatrix59 0;
BA_ "Confidence" SG_ 1012 LS_rearMatrix0 0;
BA_ "Confidence" SG_ 1012 LS_rearMatrix1 0;
BA_ "Confidence" SG_ 1012 LS_rearMatrix2 0;
BA_ "Confidence" SG_ 1012 LS_rearMatrix3 0;
BA_ "Confidence" SG_ 1012 LS_rearMatrix4 0;
BA_ "Confidence" SG_ 1012 LS_rearMatrix5 0;
BA_ "Confidence" SG_ 1012 LS_rearMatrix6 0;
BA_ "Confidence" SG_ 1012 LS_rearMatrix7 0;
BA_ "Confidence" SG_ 1012 LS_rearMatrix8 0;
BA_ "Confidence" SG_ 1012 LS_rearMatrix9 0;
BA_ "Confidence" SG_ 1012 LS_rearMatrix10 0;
BA_ "Confidence" SG_ 1012 LS_rearMatrix11 0;
BA_ "Confidence" SG_ 1012 LS_rearMatrix12 0;
BA_ "Confidence" SG_ 1012 LS_rearMatrix13 0;
BA_ "Confidence" SG_ 1012 LS_rearMatrix14 0;
BA_ "Confidence" SG_ 1012 LS_rearMatrix15 0;
BA_ "Confidence" SG_ 1012 LS_rearMatrix16 0;
BA_ "Confidence" SG_ 1012 LS_rearMatrix17 0;
BA_ "Confidence" SG_ 1012 LS_rearMatrix18 0;
BA_ "Confidence" SG_ 1012 LS_rearMatrix19 0;
BA_ "Confidence" SG_ 1012 LS_rearMatrix20 0;
BA_ "Confidence" SG_ 1012 LS_rearMatrix21 0;
BA_ "Confidence" SG_ 1012 LS_rearMatrix22 0;
BA_ "Confidence" SG_ 1012 LS_rearMatrix23 0;
BA_ "Confidence" SG_ 1012 LS_rearMatrix24 0;
BA_ "Confidence" SG_ 1012 LS_rearMatrix25 0;
BA_ "Confidence" SG_ 1012 LS_rearMatrix26 0;
BA_ "Confidence" SG_ 1012 LS_rearMatrix27 0;
BA_ "Confidence" SG_ 1012 LS_rearMatrix28 0;
BA_ "Confidence" SG_ 1012 LS_rearMatrix29 0;
BA_ "Confidence" SG_ 1012 LS_rearMatrix30 0;
BA_ "Confidence" SG_ 1012 LS_rearMatrix31 0;
BA_ "Confidence" SG_ 1012 LS_rearMatrix32 0;
BA_ "Confidence" SG_ 1012 LS_rearMatrix33 0;
BA_ "Confidence" SG_ 1012 LS_rearMatrix34 0;
BA_ "Confidence" SG_ 1012 LS_rearMatrix35 0;
BA_ "Confidence" SG_ 1012 LS_rearMatrix36 0;
BA_ "Confidence" SG_ 1012 LS_rearMatrix37 0;
BA_ "Confidence" SG_ 1012 LS_rearMatrix38 0;
BA_ "Confidence" SG_ 1012 LS_rearMatrix39 0;
BA_ "Confidence" SG_ 1012 LS_rearMatrix40 0;
BA_ "Confidence" SG_ 1012 LS_rearMatrix41 0;
BA_ "Confidence" SG_ 1012 LS_rearMatrix42 0;
BA_ "Confidence" SG_ 1012 LS_rearMatrix43 0;
BA_ "Confidence" SG_ 1012 LS_rearMatrix44 0;
BA_ "Confidence" SG_ 1012 LS_rearMatrix45 0;
BA_ "Confidence" SG_ 1012 LS_rearMatrix46 0;
BA_ "Confidence" SG_ 1012 LS_rearMatrix47 0;
BA_ "Confidence" SG_ 1012 LS_rearMatrix48 0;
BA_ "Confidence" SG_ 1012 LS_rearMatrix49 0;
BA_ "Confidence" SG_ 1012 LS_rearMatrix50 0;
BA_ "Confidence" SG_ 1012 LS_rearMatrix51 0;
BA_ "Confidence" SG_ 1012 LS_rearMatrix52 0;
BA_ "Confidence" SG_ 1012 LS_rearMatrix53 0;
BA_ "Confidence" SG_ 1012 LS_rearMatrix54 0;
BA_ "Confidence" SG_ 1012 LS_rearMatrix55 0;
BA_ "Confidence" SG_ 1012 LS_rearMatrix56 0;
BA_ "Confidence" SG_ 1012 LS_rearMatrix57 0;
BA_ "Confidence" SG_ 1012 LS_rearMatrix58 0;
BA_ "Confidence" SG_ 1012 LS_rearMatrix59 0;
BA_ "Confidence" SG_ 1012 LS_offroadLightBar0 0;
BA_ "Confidence" SG_ 1012 LS_offroadLightBar1 0;
BA_ "Confidence" SG_ 1012 LS_offroadLightBar2 0;
BA_ "Confidence" SG_ 1012 LS_offroadLightBar3 0;
BA_ "Confidence" SG_ 1012 LS_offroadLightBar4 0;
BA_ "Confidence" SG_ 1012 LS_offroadLightBar5 0;
BA_ "Confidence" SG_ 740 PCS2_logMessageSelect 1;
BA_ "Confidence" SG_ 740 PCS2_dcdcUsingInternalDefLvTarge 0;
BA_ "SystemSignalLongSymbol" SG_ 740 PCS2_dcdcUsingInternalDefLvTarge "PCS2_dcdcUsingInternalDefLvTarget";
BA_ "Confidence" SG_ 740 PCS2_dcdcAStateMachineState 0;
BA_ "Confidence" SG_ 740 PCS2_dcdcBStateMachineState 0;
BA_ "Confidence" SG_ 740 PCS2_dcdcAStageModeRequest 0;
BA_ "Confidence" SG_ 740 PCS2_dcdcBStageModeRequest 0;
BA_ "Confidence" SG_ 740 PCS2_dcdcAHvCurrentCommand 0;
BA_ "Confidence" SG_ 740 PCS2_dcdcALvCurrentCommand 0;
BA_ "Confidence" SG_ 740 PCS2_dcdcAPowerLimit 0;
BA_ "Confidence" SG_ 740 PCS2_dcdcALvCurrentEstimated 0;
BA_ "Confidence" SG_ 740 PCS2_dcdcLvBusVoltageFiltered 0;
BA_ "Confidence" SG_ 740 PCS2_dcdcALifetimekWh 0;
BA_ "GenSigSNA" SG_ 740 PCS2_dcdcALifetimekWh "16777215";
BA_ "Confidence" SG_ 740 PCS2_dcdcBHvCurrentCommand 0;
BA_ "Confidence" SG_ 740 PCS2_dcdcBLvCurrentCommand 0;
BA_ "Confidence" SG_ 740 PCS2_dcdcBPowerLimit 0;
BA_ "Confidence" SG_ 740 PCS2_dcdcBLvCurrentEstimated 0;
BA_ "Confidence" SG_ 740 PCS2_dcdcBLifetimekWh 0;
BA_ "GenSigSNA" SG_ 740 PCS2_dcdcBLifetimekWh "16777215";
BA_ "Confidence" SG_ 740 PCS2_dcdcA_lv2Temp 0;
BA_ "GenSigSNA" SG_ 740 PCS2_dcdcA_lv2Temp "1025";
BA_ "Confidence" SG_ 740 PCS2_dcdcA_lv2TempIrrational 0;
BA_ "Confidence" SG_ 740 PCS2_dcdcB_lv2Temp 0;
BA_ "GenSigSNA" SG_ 740 PCS2_dcdcB_lv2Temp "1025";
BA_ "Confidence" SG_ 740 PCS2_dcdcB_lv2TempIrrational 0;
BA_ "Confidence" SG_ 740 PCS2_dcdcA_hvTemp 0;
BA_ "GenSigSNA" SG_ 740 PCS2_dcdcA_hvTemp "1025";
BA_ "Confidence" SG_ 740 PCS2_dcdcA_hvTempIrrational 0;
BA_ "Confidence" SG_ 740 PCS2_dcdcB_hvTemp 0;
BA_ "GenSigSNA" SG_ 740 PCS2_dcdcB_hvTemp "1025";
BA_ "Confidence" SG_ 740 PCS2_dcdcB_hvTempIrrational 0;
BA_ "Confidence" SG_ 740 PCS2_acChargeLifetimekVAh 0;
BA_ "GenSigSNA" SG_ 740 PCS2_acChargeLifetimekVAh "16777215";
BA_ "Confidence" SG_ 740 PCS2_v2xGridFormLifetimekVAh 0;
BA_ "GenSigSNA" SG_ 740 PCS2_v2xGridFormLifetimekVAh "16777215";
BA_ "Confidence" SG_ 740 PCS2_cabinOnlyL2L3LifetimekVAh 0;
BA_ "GenSigSNA" SG_ 740 PCS2_cabinOnlyL2L3LifetimekVAh "16777215";
BA_ "Confidence" SG_ 740 PCS2_totalOutletLifetimekVAh 0;
BA_ "GenSigSNA" SG_ 740 PCS2_totalOutletLifetimekVAh "16777215";
BA_ "Confidence" SG_ 740 PCS2_cabinAndBedL1L2LifetimekVAh 0;
BA_ "GenSigSNA" SG_ 740 PCS2_cabinAndBedL1L2LifetimekVAh "16777215";
BA_ "Confidence" SG_ 740 PCS2_cabinAndBedL2L3LifetimekVAh 0;
BA_ "GenSigSNA" SG_ 740 PCS2_cabinAndBedL2L3LifetimekVAh "16777215";
BA_ "Confidence" SG_ 1039 PCS2_v2xUserPower 0;
BA_ "Confidence" SG_ 1039 PCS2_v2xDispatchableApparentPowe 0;
BA_ "SystemSignalLongSymbol" SG_ 1039 PCS2_v2xDispatchableApparentPowe "PCS2_v2xDispatchableApparentPower";
BA_ "Confidence" SG_ 1039 PCS2_v2xReadyApparentPower 0;
BA_ "Confidence" SG_ 612 PCS_chgInputVoltage 0;
BA_ "Confidence" SG_ 612 PCS_chgLineCurrent 0;
BA_ "Confidence" SG_ 612 PCS_chgAcVoltagePresent 0;
BA_ "Confidence" SG_ 612 PCS_chgInputPower 0;
BA_ "Confidence" SG_ 612 PCS_chgAcCurrentLimit 0;
BA_ "Confidence" SG_ 516 PCS_chgMainState 0;
BA_ "Confidence" SG_ 516 PCS_powerTransferStatus 0;
BA_ "Confidence" SG_ 516 PCS_gridConfig 0;
BA_ "GenSigSNA" SG_ 516 PCS_gridConfig "0";
BA_ "Confidence" SG_ 516 PCS_chgPHAEnable 0;
BA_ "Confidence" SG_ 516 PCS_chgPHBEnable 0;
BA_ "Confidence" SG_ 516 PCS_hvInletConductorEnergizedAc 0;
BA_ "Confidence" SG_ 516 PCS_chgHighPowerActive 0;
BA_ "Confidence" SG_ 516 PCS_chgPHCEnable 0;
BA_ "Confidence" SG_ 516 PCS_chgInstantAcPowerAvailable 0;
BA_ "Confidence" SG_ 516 PCS_chgMaxAcPowerAvailable 0;
BA_ "GenSigSNA" SG_ 516 PCS_chgMaxAcPowerAvailable "255";
BA_ "Confidence" SG_ 516 PCS_chgPHALineCurrentRequest 0;
BA_ "Confidence" SG_ 516 PCS_chgPHBLineCurrentRequest 0;
BA_ "Confidence" SG_ 516 PCS_chgPHCLineCurrentRequest 0;
BA_ "Confidence" SG_ 516 PCS_chgPwmEnableLine 0;
BA_ "Confidence" SG_ 516 PCS_powerTransferShutdownRequest 0;
BA_ "Confidence" SG_ 516 PCS_hwVariantType 0;
BA_ "GenSigSNA" SG_ 516 PCS_hwVariantType "3";
BA_ "Confidence" SG_ 516 PCS_dcacBidirectionalAllowed 0;
VAL_ 680 EPBL_systemStatus 8 "EPB_VEHICLE_STATUS_MISMATCH" 7 "EPB_VEHICLE_STATUS_FAULT_SECURE" 6 "EPB_VEHICLE_STATUS_FAULT" 5 "EPB_VEHICLE_STATUS_RELEASING" 4 "EPB_VEHICLE_STATUS_PARKING" 3 "EPB_VEHICLE_STATUS_DYNAMIC" 2 "EPB_VEHICLE_STATUS_PARKED" 1 "EPB_VEHICLE_STATUS_RELEASED" 0 "EPB_VEHICLE_STATUS_UNKNOWN" ;
VAL_ 680 EPBL_freeRollModeStatus 2 "EPB_FREE_ROLL_MODE_ENABLED" 1 "EPB_FREE_ROLL_MODE_AVAILABLE" 0 "EPB_FREE_ROLL_MODE_UNAVAILABLE" ;
VAL_ 680 EPBL_chimeRequest 4 "EPB_CHIME_REQUEST_ACTIVE_DECEL" 3 "EPB_CHIME_REQUEST_ABOUT_TO_ACTIVE_DECEL" 2 "EPB_CHIME_REQUEST_GPO" 1 "EPB_CHIME_REQUEST_GENERAL" 0 "EPB_CHIME_REQUEST_NONE" ;
VAL_ 680 EPBL_telltale 7 "EPB_TELLTALE_SNA" 4 "EPB_TELLTALE_LAMP_RED_FLASH" 3 "EPB_TELLTALE_LAMP_AMBER_ON" 2 "EPB_TELLTALE_LAMP_RED_ON" 1 "EPB_TELLTALE_LAMP_RED_PARKED" 0 "EPB_TELLTALE_LAMP_OFF" ;
VAL_ 680 EPBL_cdpRequest 1 "EPB_CDP_REQUESTED" 0 "EPB_CDP_NOT_REQUESTED" ;
VAL_ 680 EPBL_uiParkAvailable 2 "EPB_AVAIL_REAPPLIED" 1 "EPB_AVAIL_AVAILABLE" 0 "EPB_AVAIL_NOT_AVAILABLE" ;
VAL_ 680 EPBL_brakeDiscWipeRequest 3 "EPB_BRAKEDISCWIPE_REQUEST_SNA" 2 "EPB_BRAKEDISCWIPE_REQUEST_STRONG" 1 "EPB_BRAKEDISCWIPE_REQUEST_LIGHT" 0 "EPB_BRAKEDISCWIPE_REQUEST_NONE" ;
VAL_ 680 EPBL_uiWinchModeLvStatus 3 "EPB_LV_OK" 2 "EPB_LV_BLOCKED_TIMER_RUNNING" 1 "EPB_LV_BLOCKED_INPUT_VOLTAGE_LOW" 0 "EPB_LV_BLOCKED_BATTERY" ;
VAL_ 680 EPBL_autonomyBehavior 2 "DRIVERLESS_NO_TAKEOVER" 1 "DRIVERLESS_TAKEOVER" 0 "DRIVER" ;
VAL_ 2024 EPBR_infoIndex 255 "END" 41 "SUBCOMPONENT14" 40 "SUBCOMPONENT13" 39 "SUBCOMPONENT12" 38 "SUBCOMPONENT11" 37 "SUBCOMPONENT10" 36 "SUBCOMPONENT9" 35 "SUBCOMPONENT8" 34 "SUBCOMPONENT7" 33 "SUBCOMPONENT6" 32 "SUBCOMPONENT5" 31 "SUBCOMPONENT4" 24 "SUBCOMPONENT3" 23 "SUBCOMPONENT2" 20 "UDS_PROTOCOL_BOOTCRC" 19 "VERSION_DEPRECATED" 18 "BOOTLOADER_GITHASH" 17 "APP_GITHASH" 16 "SUBCOMPONENT1" 15 "BOOTLOADER_CRC" 14 "BOOTLOADER_SVN" 13 "APP_CRC" 11 "PCBAID_ASSYID_USAGEID" 10 "BUILD_HWID_COMPONENTID" 9 "DEPRECATED_9" 8 "DEPRECATED_8" 7 "DEPRECATED_7" 6 "DEPRECATED_6" 5 "DEPRECATED_5" 4 "DEPRECATED_4" 3 "DEPRECATED_3" 2 "DEPRECATED_2" 1 "DEPRECATED_1" 0 "DEPRECATED_0" ;
VAL_ 2024 EPBR_infoBuildType 4 "INFO_MFG_BUILD" 3 "INFO_TRACEABLE_CI_BUILD" 2 "INFO_LOCAL_BUILD" 1 "INFO_PLATFORM_BUILD" 0 "INFO_UNKNOWN_BUILD" ;
VAL_ 2024 EPBR_infoAssemblyId 255 "ASSEMBLY_SNA" 1 "ASSEMBLY1" ;
VAL_ 552 EPBR_unitStatus 23 "EPB_STATUS_COUNT" 22 "EPB_STATUS_AUTONOMY_OPEN" 21 "EPB_STATUS_FREE_ROLL_MODE" 20 "EPB_STATUS_DYNAMIC_PARKING" 19 "EPB_STATUS_EXTERNAL_PARKING" 18 "EPB_STATUS_RELEASING_FOR_EXTERNAL_PARK" 17 "EPB_STATUS_EXTERNAL_DYNAMIC" 16 "EPB_STATUS_SUMMON_PARKING" 15 "EPB_STATUS_SUMMON_RELEASING" 14 "EPB_STATUS_SUMMON" 13 "EPB_STATUS_WINCHMODE_PENDING" 12 "EPB_STATUS_PARK_PENDING" 11 "EPB_STATUS_SERVICE_RELEASING" 10 "EPB_STATUS_RELEASING" 9 "EPB_STATUS_DYNAMIC_APPLYING" 8 "EPB_STATUS_PARKING" 7 "EPB_STATUS_WINCHMODE_RELEASING" 6 "EPB_STATUS_WINCHMODE" 5 "EPB_STATUS_SERVICE" 4 "EPB_STATUS_START" 3 "EPB_STATUS_PARK" 2 "EPB_STATUS_DYNAMIC" 1 "EPB_STATUS_OPEN" 0 "EPB_STATUS_UNKNOWN" ;
VAL_ 552 EPBR_unitFaultStatus 3 "EPB_STATUS_FAULT_IDLE" 2 "EPB_STATUS_FAULT" 1 "EPB_STATUS_RETRY" 0 "EPB_STATUS_NOMINAL" ;
VAL_ 552 EPBR_summonState 6 "EPB_SUMMON_UNAVAILABLE" 5 "EPB_SUMMON_FAULT" 4 "EPB_SUMMON_COMPLETE" 3 "EPB_SUMMON_ACTIVE" 2 "EPB_SUMMON_ARMED" 1 "EPB_SUMMON_IDLE" 0 "EPB_SUMMON_INIT" ;
VAL_ 552 EPBR_csmFaultReason 23 "CSM_FAULT_REMOTE_MIA" 22 "CSM_FAULT_NVM_MISMATCH" 21 "CSM_FAULT_EPBM_MIA" 20 "CSM_FAULT_MOTOR_NOT_READY" 19 "CSM_FAULT_MOTOR_ACTIVE_FAULT" 18 "CSM_FAULT_MOTOR_IDLE_FAULT" 17 "CSM_FAULT_TIMEOUT_EPBM_START" 16 "CSM_FAULT_TIMEOUT_NO_RAMP" 15 "CSM_FAULT_TIMEOUT_EPBM_CUTOFF" 14 "CSM_FAULT_TIMEOUT_RELEASE_COMPLETE" 13 "CSM_FAULT_TIMEOUT_RELEASE_NO_LOAD" 12 "CSM_FAULT_TIMEOUT_RELEASE_WAIT_FOR_ENDSTOP" 11 "CSM_FAULT_TIMEOUT_RELEASE_INRUSH" 10 "CSM_FAULT_TIMEOUT_EPBM_WAIT_FOR_CLAMP" 9 "CSM_FAULT_TIMEOUT_EPB_WAIT_FOR_CLAMP" 8 "CSM_FAULT_TIMEOUT_APPLY_INRUSH" 7 "CSM_FAULT_TIMEOUT_APPLY_COMPLETE" 6 "CSM_FAULT_RELEASE_BLOCKED" 5 "CSM_FAULT_APPLY_BLOCKED" 4 "CSM_FAULT_TIMEOUT_CALIBRATE" 3 "CSM_FAULT_STATE_MISMATCH" 2 "CSM_FAULT_EPBM_FAULTED" 1 "CSM_FAULT_EPBM_DISABLED" 0 "CSM_FAULT_NONE" ;
VAL_ 552 EPBR_esmOperationTrigger 50 "EPB_TRIGGER_ACTIVE_DECEL_DAS_STATIC" 49 "EPB_TRIGGER_ACTIVE_DECEL_CDP_DOWN" 48 "EPB_TRIGGER_AP_IS_LEAVING" 47 "EPB_TRIGGER_RECOVERY_PARK" 46 "EPB_TRIGGER_SPEED_SOURCES_LOST" 45 "EPB_TRIGGER_ACTIVE_DECEL_OKTOPARK" 44 "EPB_TRIGGER_ACTIVE_DECEL_FAST" 43 "EPB_TRIGGER_STEERING_ACTIVE_DECEL" 42 "EPB_TRIGGER_LV_ACTIVE_DECEL" 41 "EPB_TRIGGER_CDP_PANIC_MODE_READY" 40 "EPB_TRIGGER_CDP_PANIC_MODE_TIMEOUT" 39 "EPB_TRIGGER_DI_PARK" 38 "EPB_TRIGGER_FREE_ROLL_PARK_FOR_HANDLE_PULLED" 37 "EPB_TRIGGER_LOW_BRAKE_FLUID_MODE_DYNAMIC" 36 "EPB_TRIGGER_LOW_BRAKE_FLUID_MODE_DYNAMIC_PARK" 35 "EPB_TRIGGER_LOW_BRAKE_FLUID_MODE_PARK" 34 "EPB_TRIGGER_STATIONARY_DETECT" 33 "EPB_TRIGGER_TOUCHSCREEN_INVALID" 32 "EPB_TRIGGER_UI_DOOR_OPEN_REQUEST" 31 "EPB_TRIGGER_AUTOPARK_END" 30 "EPB_TRIGGER_DRIVER_IS_LEAVING" 29 "EPB_TRIGGER_SYSTEM_APPLY" 28 "EPB_TRIGGER_ACCELERATION" 27 "EPB_TRIGGER_EPBM_DISQUALIFIED" 26 "EPB_TRIGGER_DISQUALIFIED" 25 "EPB_TRIGGER_SUMMON_FAULT" 24 "EPB_TRIGGER_FAULT" 23 "EPB_TRIGGER_SUMMON_COMPLETE" 22 "EPB_TRIGGER_REAPPLY" 21 "EPB_TRIGGER_SAVESTATE_ON_BOOT" 20 "EPB_TRIGGER_TIMEOUT" 19 "EPB_TRIGGER_SPEED_FAST" 18 "EPB_TRIGGER_SPEED_OKAYTOPARK" 17 "EPB_TRIGGER_SPEED_STOPPED" 16 "EPB_TRIGGER_USER_CANCEL" 15 "EPB_TRIGGER_USER_CONFIRMED" 14 "EPB_TRIGGER_DIAG_EXIT" 13 "EPB_TRIGGER_DIAG_OPEN" 12 "EPB_TRIGGER_DIAG_CLOSE" 11 "EPB_TRIGGER_SERVICE" 10 "EPB_TRIGGER_WINCHMODE_UNAVAILABLE" 9 "EPB_TRIGGER_WINCHMODE_ENTER" 8 "EPB_TRIGGER_WINCHMODE_EXIT" 7 "EPB_TRIGGER_TOUCHSCREEN" 6 "EPB_TRIGGER_DI_UNPARK" 5 "EPB_TRIGGER_ACTIVE_PARK_REQUEST" 4 "EPB_TRIGGER_PBUTTON_RELEASED" 3 "EPB_TRIGGER_PBUTTON_PRESSED_UNKNOWN" 2 "EPB_TRIGGER_PBUTTON_PRESSED_FAST" 1 "EPB_TRIGGER_PBUTTON_PRESSED_OKTOPARK" 0 "EPB_TRIGGER_PBUTTON_PRESSED_STOPPED" ;
VAL_ 552 EPBR_summonFaultReason 30 "EPB_SUMMONFAULT_MONITOR_TYPE_UNKNOWN" 29 "EPB_SUMMONFAULT_AP_MONITOR" 28 "EPB_SUMMONFAULT_REMOTE_DID_NOT_START" 27 "EPB_SUMMONFAULT_INVALID_REMOTE_STATE" 26 "EPB_SUMMONFAULT_START_IN_UNAVAILABLE" 25 "EPB_SUMMONFAULT_REMOTE_UNIT_FAULTED" 24 "EPB_SUMMONFAULT_LOCAL_UNIT_FAULTED" 23 "EPB_SUMMONFAULT_REMOTE_SUMMON_FAULTED" 22 "EPB_SUMMONFAULT_EPBREMOTE_MIA" 21 "EPB_SUMMONFAULT_PASSIVE_REQUEST" 20 "EPB_SUMMONFAULT_DI_STATE_INVALID" 19 "EPB_SUMMONFAULT_EPB_FAULT" 18 "EPB_SUMMONFAULT_MISMATCH" 17 "EPB_SUMMONFAULT_OOC" 16 "EPB_SUMMONFAULT_PM_REQUEST" 15 "EPB_SUMMONFAULT_PM_MIA" 14 "EPB_SUMMONFAULT_PARK_MIA" 13 "EPB_SUMMONFAULT_EXTERNAL" 12 "EPB_SUMMONFAULT_SPEED" 11 "EPB_SUMMONFAULT_EPBM_REQUEST" 10 "EPB_SUMMONFAULT_EAC_NOT_ALLOWED" 9 "EPB_SUMMONFAULT_VEH_CAN_FAULT" 8 "EPB_SUMMONFAULT_ESP_FAULT" 7 "EPB_SUMMONFAULT_DAS_FAULT" 6 "EPB_SUMMONFAULT_DI_APC_FAULT" 5 "EPB_SUMMONFAULT_DI_FAULT" 4 "EPB_SUMMONFAULT_EPBM_MIA" 3 "EPB_SUMMONFAULT_ESP_MIA" 2 "EPB_SUMMONFAULT_DAS_MIA" 1 "EPB_SUMMONFAULT_DI_MIA" 0 "EPB_SUMMONFAULT_NONE" ;
VAL_ 552 EPBR_localCdpState 2 "EPB_CDP_STATE_FAULT" 1 "EPB_CDP_STATE_VALID" 0 "EPB_CDP_STATE_UNKNOWN" ;
VAL_ 552 EPBR_chimeRequestLocal 4 "EPB_CHIME_REQUEST_ACTIVE_DECEL" 3 "EPB_CHIME_REQUEST_ABOUT_TO_ACTIVE_DECEL" 2 "EPB_CHIME_REQUEST_GPO" 1 "EPB_CHIME_REQUEST_GENERAL" 0 "EPB_CHIME_REQUEST_NONE" ;
VAL_ 552 EPBR_telltaleLocal 7 "EPB_TELLTALE_SNA" 4 "EPB_TELLTALE_LAMP_RED_FLASH" 3 "EPB_TELLTALE_LAMP_AMBER_ON" 2 "EPB_TELLTALE_LAMP_RED_ON" 1 "EPB_TELLTALE_LAMP_RED_PARKED" 0 "EPB_TELLTALE_LAMP_OFF" ;
VAL_ 552 EPBR_internalCDPRequest 1 "EPB_CDP_REQUESTED" 0 "EPB_CDP_NOT_REQUESTED" ;
VAL_ 552 EPBR_esmSpeedClass 4 "ESM_SPEED_CLASS_UNKNOWN" 3 "ESM_SPEED_CLASS_FAST" 2 "ESM_SPEED_CLASS_USER_APPLY_OK" 1 "ESM_SPEED_CLASS_SYSTEM_APPLY_OK" 0 "ESM_SPEED_CLASS_STOPPED" ;
VAL_ 552 EPBR_learnedEpbConfig 11 "EPB_CONFIG_CT_MANDO" 10 "EPB_CONFIG_MODEL3_ZF" 9 "EPB_CONFIG_MODELS_CERAMIC" 8 "EPB_CONFIG_MODELY_PERFORMANCE_V2" 7 "EPB_CONFIG_MODEL3_PERFORMANCE_V2" 6 "EPB_CONFIG_MODELX_BASE" 5 "EPB_CONFIG_MODELY_PERFORMANCE" 4 "EPB_CONFIG_MODELY_BASE" 3 "EPB_CONFIG_MODELS_BASE" 2 "EPB_CONFIG_MODEL3_PERFORMANCE" 1 "EPB_CONFIG_MODEL3_BASE" 0 "EPB_CONFIG_UNKNOWN" ;
VAL_ 744 EPBR_systemStatus 8 "EPB_VEHICLE_STATUS_MISMATCH" 7 "EPB_VEHICLE_STATUS_FAULT_SECURE" 6 "EPB_VEHICLE_STATUS_FAULT" 5 "EPB_VEHICLE_STATUS_RELEASING" 4 "EPB_VEHICLE_STATUS_PARKING" 3 "EPB_VEHICLE_STATUS_DYNAMIC" 2 "EPB_VEHICLE_STATUS_PARKED" 1 "EPB_VEHICLE_STATUS_RELEASED" 0 "EPB_VEHICLE_STATUS_UNKNOWN" ;
VAL_ 744 EPBR_freeRollModeStatus 2 "EPB_FREE_ROLL_MODE_ENABLED" 1 "EPB_FREE_ROLL_MODE_AVAILABLE" 0 "EPB_FREE_ROLL_MODE_UNAVAILABLE" ;
VAL_ 744 EPBR_chimeRequest 4 "EPB_CHIME_REQUEST_ACTIVE_DECEL" 3 "EPB_CHIME_REQUEST_ABOUT_TO_ACTIVE_DECEL" 2 "EPB_CHIME_REQUEST_GPO" 1 "EPB_CHIME_REQUEST_GENERAL" 0 "EPB_CHIME_REQUEST_NONE" ;
VAL_ 744 EPBR_telltale 7 "EPB_TELLTALE_SNA" 4 "EPB_TELLTALE_LAMP_RED_FLASH" 3 "EPB_TELLTALE_LAMP_AMBER_ON" 2 "EPB_TELLTALE_LAMP_RED_ON" 1 "EPB_TELLTALE_LAMP_RED_PARKED" 0 "EPB_TELLTALE_LAMP_OFF" ;
VAL_ 744 EPBR_cdpRequest 1 "EPB_CDP_REQUESTED" 0 "EPB_CDP_NOT_REQUESTED" ;
VAL_ 744 EPBR_uiParkAvailable 2 "EPB_AVAIL_REAPPLIED" 1 "EPB_AVAIL_AVAILABLE" 0 "EPB_AVAIL_NOT_AVAILABLE" ;
VAL_ 744 EPBR_brakeDiscWipeRequest 3 "EPB_BRAKEDISCWIPE_REQUEST_SNA" 2 "EPB_BRAKEDISCWIPE_REQUEST_STRONG" 1 "EPB_BRAKEDISCWIPE_REQUEST_LIGHT" 0 "EPB_BRAKEDISCWIPE_REQUEST_NONE" ;
VAL_ 744 EPBR_uiWinchModeLvStatus 3 "EPB_LV_OK" 2 "EPB_LV_BLOCKED_TIMER_RUNNING" 1 "EPB_LV_BLOCKED_INPUT_VOLTAGE_LOW" 0 "EPB_LV_BLOCKED_BATTERY" ;
VAL_ 744 EPBR_autonomyBehavior 2 "DRIVERLESS_NO_TAKEOVER" 1 "DRIVERLESS_TAKEOVER" 0 "DRIVER" ;
VAL_ 1117 FC_evseBillingDataSelect 1 "1" 0 "0" ;
VAL_ 1334 FC_evseBilling2DataSelect 0 "FC_EVSEBILLING2_DATASELECT_0" ;
VAL_ 1334 FC_evseBillingEnergyHighRes 16777215 "SNA" ;
VAL_ 1310 FC_infoIndex 255 "END_FC" 27 "PART_NUM_3" 26 "PART_NUM_2" 25 "PART_NUM_1" 22 "VARIANT_CRC_FC" 20 "UDS_PROTOCOL_BOOTCRC_FC" 19 "VERSION_DEPRECATED_FC" 18 "BOOTLOADER_GITHASH_FC" 17 "APP_GITHASH_FC" 16 "SUBCOMPONENT_FC" 15 "BOOTLOADER_CRC_FC" 14 "BOOTLOADER_SVN_FC" 13 "APP_CRC_FC" 11 "PCBAID_ASSYID_USAGEID_FC" 10 "BUILD_HWID_COMPONENTID_FC" 9 "DEPRECATED_9_FC" 8 "DEPRECATED_8_FC" 7 "DEPRECATED_7_FC" 6 "DEPRECATED_6_FC" 5 "DEPRECATED_5_FC" 4 "DEPRECATED_4_FC" 3 "DEPRECATED_3_FC" 2 "DEPRECATED_2_FC" 1 "DEPRECATED_1_FC" 0 "DEPRECATED_0_FC" ;
VAL_ 1310 FC_infoBuildType 4 "INFO_MFG_BUILD_FC" 3 "INFO_TRACEABLE_CI_BUILD_FC" 2 "INFO_LOCAL_BUILD_FC" 1 "INFO_PLATFORM_BUILD_FC" 0 "INFO_UNKNOWN_BUILD_FC" ;
VAL_ 580 FC_powerLimit 8191 "SNA" ;
VAL_ 580 FC_currentLimit 8191 "SNA" ;
VAL_ 580 FC_maxVoltageLimit 8191 "SNA" ;
VAL_ 580 FC_minVoltageLimit 8191 "SNA" ;
VAL_ 702 FC_powerLimit_value -32768 "SNA" ;
VAL_ 702 FC_currentLimit_value -32768 "SNA" ;
VAL_ 702 FC_minVoltageLimit_value -32768 "SNA" ;
VAL_ 1345 FC_maxPowerLimit 8191 "SNA" ;
VAL_ 1345 FC_maxCurrentLimit 8191 "SNA" ;
VAL_ 1300 FC_serialDataSelect 2 "Mux2" 1 "Mux1" 0 "Mux0" ;
VAL_ 532 FC_statusCode 15 "FC_STATUS_NODATA" 14 "FC_STATUS_MALFUNCTION" 13 "FC_STATUS_NOTCOMPATIBLE" 7 "FC_STATUS_POST_OUT_OF_SERVICE" 6 "FC_STATUS_EXT_ISOACTIVE" 5 "FC_STATUS_INT_ISOACTIVE" 4 "FC_STATUS_DEPRECATED_4" 3 "FC_STATUS_DEPRECATED_3" 2 "FC_STATUS_UPDATE_IN_PROGRESS" 1 "FC_STATUS_READY" 0 "FC_STATUS_NOTREADY_SNA" ;
VAL_ 532 FC_type 7 "FC_TYPE_SNA" 6 "FC_TYPE_OTHER" 5 "FC_TYPE_MC_EVSE" 4 "FC_TYPE_COMBO" 3 "FC_TYPE_CC_EVSE" 2 "FC_TYPE_GB" 1 "FC_TYPE_CHADEMO" 0 "FC_TYPE_SUPERCHARGER" ;
VAL_ 532 FC_postID 3 "FC_POST_ID_SNA" 2 "FC_POST_ID_2" 1 "FC_POST_SLAVE" 0 "FC_POST_MASTER" ;
VAL_ 533 FC_externalIsolationResistance 255 "SNA" ;
VAL_ 535 FC_status3DataSelect 1 "Mux1" 0 "Mux0" ;
VAL_ 535 FC_class 2 "FC_CLASS_URBANCHARGER" 1 "FC_CLASS_SUPERCHARGER" 0 "FC_CLASS_SNA" ;
VAL_ 535 FC_brand 1 "TESLA" 0 "SNA" ;
VAL_ 535 FC_coolingType 3 "FC_COOLING_TYPE_IMMERSION" 2 "FC_COOLING_TYPE_CONVECTION" 1 "FC_COOLING_TYPE_LIQUID" 0 "FC_COOLING_TYPE_SNA" ;
VAL_ 535 FC_uiStopType 2 "FC_UI_STOP_TYPE_MOMENTARY" 1 "FC_UI_STOP_TYPE_TOGGLE" 0 "FC_UI_STOP_TYPE_SNA" ;
VAL_ 535 FC_generation 0 "GENERATION_SNA" ;
VAL_ 1650 VC_hcmlInfoIndex 9 "END" 8 "ECULESS_MISC" 7 "ECULESS_BOOST" 6 "ECULESS_LED_VOLTAGES" 5 "ECULESS_IC700_SM" 4 "ECULESS_IC600_DRL_TURN" 3 "ECULESS_IC500_LB" 2 "ECULESS_IC400_HB" 1 "HCML_ASSEMBLY_PCBA_USAGE_ID" 0 "HCML_BUILD_CONFIG_ID_LMM_VARIANT" ;
VAL_ 1650 VC_leftHeadlampLMMVariant 2 "LMM_VARIANT_LMM4" 1 "LMM_VARIANT_NOT_LMM4_OR_UNKNOWN" 0 "LMM_VARIANT_SNA" ;
VAL_ 1980 VC_hcmrInfoIndex 9 "END" 8 "ECULESS_MISC" 7 "ECULESS_BOOST" 6 "ECULESS_LED_VOLTAGES" 5 "ECULESS_IC700_SM" 4 "ECULESS_IC600_DRL_TURN" 3 "ECULESS_IC500_LB" 2 "ECULESS_IC400_HB" 1 "HCMR_ASSEMBLY_PCBA_USAGE_ID" 0 "HCMR_BUILD_CONFIG_ID_LMM_VARIANT" ;
VAL_ 1980 VC_rightHeadlampLMMVariant 2 "LMM_VARIANT_LMM4" 1 "LMM_VARIANT_NOT_LMM4_OR_UNKNOWN" 0 "LMM_VARIANT_SNA" ;
VAL_ 522 HVP_packContNegativeState 7 "CONTACTOR_STATE_WELDED" 6 "CONTACTOR_STATE_ECONOMIZED" 5 "CONTACTOR_STATE_OPENING" 4 "CONTACTOR_STATE_PULLED_IN" 3 "CONTACTOR_STATE_BLOCKED" 2 "CONTACTOR_STATE_PRECHARGE" 1 "CONTACTOR_STATE_OPEN" 0 "CONTACTOR_STATE_SNA" ;
VAL_ 522 HVP_packContPositiveState 7 "CONTACTOR_STATE_WELDED" 6 "CONTACTOR_STATE_ECONOMIZED" 5 "CONTACTOR_STATE_OPENING" 4 "CONTACTOR_STATE_PULLED_IN" 3 "CONTACTOR_STATE_BLOCKED" 2 "CONTACTOR_STATE_PRECHARGE" 1 "CONTACTOR_STATE_OPEN" 0 "CONTACTOR_STATE_SNA" ;
VAL_ 522 HVP_packContactorSetState 9 "CONTACTOR_SET_STATE_NEGATIVE_CLOSED" 8 "CONTACTOR_SET_STATE_POSITIVE_CLOSED" 7 "CONTACTOR_SET_STATE_WELDED" 6 "CONTACTOR_SET_STATE_PARTIAL_WELD" 5 "CONTACTOR_SET_STATE_CLOSED" 4 "CONTACTOR_SET_STATE_OPENING" 3 "CONTACTOR_SET_STATE_BLOCKED" 2 "CONTACTOR_SET_STATE_CLOSING" 1 "CONTACTOR_SET_STATE_OPEN" 0 "CONTACTOR_SET_STATE_SNA" ;
VAL_ 522 HVP_fcContNegativeState 7 "CONTACTOR_STATE_WELDED" 6 "CONTACTOR_STATE_ECONOMIZED" 5 "CONTACTOR_STATE_OPENING" 4 "CONTACTOR_STATE_PULLED_IN" 3 "CONTACTOR_STATE_BLOCKED" 2 "CONTACTOR_STATE_PRECHARGE" 1 "CONTACTOR_STATE_OPEN" 0 "CONTACTOR_STATE_SNA" ;
VAL_ 522 HVP_fcContPositiveState 7 "CONTACTOR_STATE_WELDED" 6 "CONTACTOR_STATE_ECONOMIZED" 5 "CONTACTOR_STATE_OPENING" 4 "CONTACTOR_STATE_PULLED_IN" 3 "CONTACTOR_STATE_BLOCKED" 2 "CONTACTOR_STATE_PRECHARGE" 1 "CONTACTOR_STATE_OPEN" 0 "CONTACTOR_STATE_SNA" ;
VAL_ 522 HVP_fcContactorSetState 9 "CONTACTOR_SET_STATE_NEGATIVE_CLOSED" 8 "CONTACTOR_SET_STATE_POSITIVE_CLOSED" 7 "CONTACTOR_SET_STATE_WELDED" 6 "CONTACTOR_SET_STATE_PARTIAL_WELD" 5 "CONTACTOR_SET_STATE_CLOSED" 4 "CONTACTOR_SET_STATE_OPENING" 3 "CONTACTOR_SET_STATE_BLOCKED" 2 "CONTACTOR_SET_STATE_CLOSING" 1 "CONTACTOR_SET_STATE_OPEN" 0 "CONTACTOR_SET_STATE_SNA" ;
VAL_ 522 HVP_fcCtrsRequestStatus 2 "REQUEST_COMPLETED" 1 "REQUEST_ACTIVE" 0 "REQUEST_NOT_ACTIVE" ;
VAL_ 522 HVP_packCtrsRequestStatus 2 "REQUEST_COMPLETED" 1 "REQUEST_ACTIVE" 0 "REQUEST_NOT_ACTIVE" ;
VAL_ 522 HVP_hvilDiag 14 "SNA" 13 "PM_OPEN_FAULT" 12 "DI_OPEN_FAULT" 11 "PM_STATUS_MISSING_FAULT" 10 "DI_STATUS_MISSING_FAULT" 9 "VEHICLE_OR_PENTHOUSE_LID_OPEN_FAULT" 8 "NO_12V_SUPPLY" 7 "VEHICLE_NODE_FAULT" 6 "UNKNOWN_LOCATION_OPEN_FAULT" 5 "PENTHOUSE_LID_OPEN_FAULT" 4 "VEHICLE_OPEN_FAULT" 3 "INTERNAL_OPEN_FAULT" 2 "CURRENT_SOURCE_OR_GROUND_LEAK_FAULT" 1 "OK" 0 "UNKNOWN" ;
VAL_ 522 HVP_fcLinkAllowedToEnergize 2 "FC_LINK_ENERGY_DC" 1 "FC_LINK_ENERGY_AC" 0 "FC_LINK_ENERGY_NONE" ;
VAL_ 1962 HVP_debugMessageMultiplexer 12 "Mux12" 11 "Mux11" 10 "Mux10" 9 "Mux9" 8 "Mux8" 7 "Mux7" 6 "Mux6" 5 "Mux5" 4 "Mux4" 3 "Mux3" 2 "Mux2" 1 "Mux1" 0 "Mux0" ;
VAL_ 1962 HVP_ecuLogUploadRequest 3 "REQUEST_PRIORITY_3" 2 "REQUEST_PRIORITY_2" 1 "REQUEST_PRIORITY_1" 0 "REQUEST_PRIORITY_NONE" ;
VAL_ 1962 HVP_passivePyroRefVoltageMax 1023 "SNA" ;
VAL_ 1962 HVP_passivePyroRefVoltageMin 1023 "SNA" ;
VAL_ 554 HVP_pcsControlRequest 3 "DISCHARGE" 2 "PRECHARGE" 1 "SUPPORT" 0 "SHUTDOWN" ;
VAL_ 554 HVP_dcLinkVoltageFiltered -550 "SNA" ;
VAL_ 784 HVP_infoIndex 255 "END" 31 "SUBCOMPONENT_GITHASH" 30 "PACKAGE_SN_8_14" 29 "PACKAGE_SN_1_7" 27 "PACKAGE_PN_15_20" 26 "PACKAGE_PN_8_14" 25 "PACKAGE_PN_1_7" 23 "SUBCOMPONENT2" 22 "VARIANTCRC" 20 "UDS_PROTOCOL_BOOTCRC" 19 "VERSION_DEPRECATED" 18 "BOOTLOADER_GITHASH" 17 "APP_GITHASH" 16 "SUBCOMPONENT" 15 "BOOTLOADER_CRC" 14 "BOOTLOADER_SVN" 13 "APP_CRC" 11 "PCBAID_ASSYID_USAGEID" 10 "BUILD_HWID_COMPONENTID" 9 "DEPRECATED_9" 8 "DEPRECATED_8" 7 "DEPRECATED_7" 6 "DEPRECATED_6" 5 "DEPRECATED_5" 4 "DEPRECATED_4" 3 "DEPRECATED_3" 2 "DEPRECATED_2" 1 "DEPRECATED_1" 0 "DEPRECATED_0" ;
VAL_ 784 HVP_buildType 4 "INFO_MFG_BUILD" 3 "INFO_TRACEABLE_CI_BUILD" 2 "INFO_LOCAL_BUILD" 1 "INFO_PLATFORM_BUILD" 0 "INFO_UNKNOWN_BUILD" ;
VAL_ 1914 HVP_log1HzIndex 1 "Mux1" 0 "Mux0" ;
VAL_ 1914 HVP_bmbAsicType 3 "BQ796xx" 2 "ADBMS6830" 1 "LTC831" 0 "UNKNOWN" ;
VAL_ 1914 HVP_shuntCurrentAuxLog 8388000 "PACK_CURRENT_SNA" ;
VAL_ 1914 HVP_pyroSquibResistance 65535 "SNA" ;
VAL_ 1914 HVP_hvilCalType 2 "CAN" 1 "LV" 0 "UNKNOWN" ;
VAL_ 941 ICR_infoIndex 255 "END" 31 "SUBCOMPONENT_GITHASH" 30 "PACKAGE_SN_8_14" 29 "PACKAGE_SN_1_7" 27 "PACKAGE_PN_15_20" 26 "PACKAGE_PN_8_14" 25 "PACKAGE_PN_1_7" 23 "SUBCOMPONENT2" 22 "VARIANTCRC" 20 "UDS_PROTOCOL_BOOTCRC" 19 "VERSION_DEPRECATED" 18 "BOOTLOADER_GITHASH" 17 "APP_GITHASH" 16 "SUBCOMPONENT" 15 "BOOTLOADER_CRC" 14 "BOOTLOADER_SVN" 13 "APP_CRC" 11 "PCBAID_ASSYID_USAGEID" 10 "BUILD_HWID_COMPONENTID" 9 "DEPRECATED_9" 8 "DEPRECATED_8" 7 "DEPRECATED_7" 6 "DEPRECATED_6" 5 "DEPRECATED_5" 4 "DEPRECATED_4" 3 "DEPRECATED_3" 2 "DEPRECATED_2" 1 "DEPRECATED_1" 0 "DEPRECATED_0" ;
VAL_ 941 ICR_infoBuildType 4 "INFO_MFG_BUILD" 3 "INFO_TRACEABLE_CI_BUILD" 2 "INFO_LOCAL_BUILD" 1 "INFO_PLATFORM_BUILD" 0 "INFO_UNKNOWN_BUILD" ;
VAL_ 667 ICR_lifePresenceMLOutput 255 "SNA" ;
VAL_ 667 ICR_largeOccupantPresenceMLOutpu 255 "SNA" ;
VAL_ 667 ICR_lifePresenceRaw 2 "LIFE_DETECTED" 1 "LIFE_NOT_DETECTED" 0 "LIFE_DETECTED_SNA" ;
VAL_ 667 ICR_lifePresenceFilt 2 "LIFE_DETECTED" 1 "LIFE_NOT_DETECTED" 0 "LIFE_DETECTED_SNA" ;
VAL_ 667 ICR_largeOccupantPresenceRaw 3 "SBRStatus_SEAT_SNA" 2 "SBRStatus_SEAT_FAULTED" 1 "SBRStatus_SEAT_OCCUPIED" 0 "SBRStatus_SEAT_UNOCCUPIED" ;
VAL_ 667 ICR_largeOccupantPresenceFilt 3 "SBRStatus_SEAT_SNA" 2 "SBRStatus_SEAT_FAULTED" 1 "SBRStatus_SEAT_OCCUPIED" 0 "SBRStatus_SEAT_UNOCCUPIED" ;
VAL_ 667 ICR_childPresenceFunctionality 2 "CHILD_PRESENCE_SNA" 1 "CHILD_PRESENCE_ENABLED" 0 "CHILD_PRESENCE_DISABLED" ;
VAL_ 667 ICR_userPresenceFunctionality 2 "CHILD_PRESENCE_SNA" 1 "CHILD_PRESENCE_ENABLED" 0 "CHILD_PRESENCE_DISABLED" ;
VAL_ 667 ICR_userPresenceMLOutput 255 "SNA" ;
VAL_ 667 ICR_userPresenceRaw 3 "SBRStatus_SEAT_SNA" 2 "SBRStatus_SEAT_FAULTED" 1 "SBRStatus_SEAT_OCCUPIED" 0 "SBRStatus_SEAT_UNOCCUPIED" ;
VAL_ 667 ICR_userPresenceFilt 3 "SBRStatus_SEAT_SNA" 2 "SBRStatus_SEAT_FAULTED" 1 "SBRStatus_SEAT_OCCUPIED" 0 "SBRStatus_SEAT_UNOCCUPIED" ;
VAL_ 536 ICR_occupancy1LRaw 3 "SBRStatus_SEAT_SNA" 2 "SBRStatus_SEAT_FAULTED" 1 "SBRStatus_SEAT_OCCUPIED" 0 "SBRStatus_SEAT_UNOCCUPIED" ;
VAL_ 536 ICR_occupancy1RRaw 3 "SBRStatus_SEAT_SNA" 2 "SBRStatus_SEAT_FAULTED" 1 "SBRStatus_SEAT_OCCUPIED" 0 "SBRStatus_SEAT_UNOCCUPIED" ;
VAL_ 536 ICR_occupancy1LFilt 3 "SBRStatus_SEAT_SNA" 2 "SBRStatus_SEAT_FAULTED" 1 "SBRStatus_SEAT_OCCUPIED" 0 "SBRStatus_SEAT_UNOCCUPIED" ;
VAL_ 536 ICR_occupancy1RFilt 3 "SBRStatus_SEAT_SNA" 2 "SBRStatus_SEAT_FAULTED" 1 "SBRStatus_SEAT_OCCUPIED" 0 "SBRStatus_SEAT_UNOCCUPIED" ;
VAL_ 536 ICR_occupancy2LFilt 3 "SBRStatus_SEAT_SNA" 2 "SBRStatus_SEAT_FAULTED" 1 "SBRStatus_SEAT_OCCUPIED" 0 "SBRStatus_SEAT_UNOCCUPIED" ;
VAL_ 536 ICR_occupancy2CFilt 3 "SBRStatus_SEAT_SNA" 2 "SBRStatus_SEAT_FAULTED" 1 "SBRStatus_SEAT_OCCUPIED" 0 "SBRStatus_SEAT_UNOCCUPIED" ;
VAL_ 536 ICR_occupancy2RFilt 3 "SBRStatus_SEAT_SNA" 2 "SBRStatus_SEAT_FAULTED" 1 "SBRStatus_SEAT_OCCUPIED" 0 "SBRStatus_SEAT_UNOCCUPIED" ;
VAL_ 536 ICR_occupancy1RFiltExp 3 "SBRStatus_SEAT_SNA" 2 "SBRStatus_SEAT_FAULTED" 1 "SBRStatus_SEAT_OCCUPIED" 0 "SBRStatus_SEAT_UNOCCUPIED" ;
VAL_ 670 ICR_classification1RFilt 4 "OCCUPANT_CLASSIFICATION_OCCUPIED_ALLOW" 3 "OCCUPANT_CLASSIFICATION_OCCUPIED_INHIBIT" 2 "OCCUPANT_CLASSIFICATION_EMPTY" 1 "OCCUPANT_CLASSIFICATION_INIT" 0 "OCCUPANT_CLASSIFICATION_SNA" ;
VAL_ 670 ICR_classification1LRaw 4 "OCCUPANT_CLASSIFICATION_OCCUPIED_ALLOW" 3 "OCCUPANT_CLASSIFICATION_OCCUPIED_INHIBIT" 2 "OCCUPANT_CLASSIFICATION_EMPTY" 1 "OCCUPANT_CLASSIFICATION_INIT" 0 "OCCUPANT_CLASSIFICATION_SNA" ;
VAL_ 670 ICR_classification1RRaw 4 "OCCUPANT_CLASSIFICATION_OCCUPIED_ALLOW" 3 "OCCUPANT_CLASSIFICATION_OCCUPIED_INHIBIT" 2 "OCCUPANT_CLASSIFICATION_EMPTY" 1 "OCCUPANT_CLASSIFICATION_INIT" 0 "OCCUPANT_CLASSIFICATION_SNA" ;
VAL_ 670 ICR_classification1LMLOutput 255 "SNA" ;
VAL_ 670 ICR_classification1RMLOutput 255 "SNA" ;
VAL_ 670 ICR_classification1LqF 1 "OCCUPANT_CLASSIFICATION_NOT_FAULTED" 0 "OCCUPANT_CLASSIFICATION_FAULTED" ;
VAL_ 670 ICR_blockageClutterFar -16 "SNA" ;
VAL_ 670 ICR_blockageClutterNear -16 "SNA" ;
VAL_ 670 ICR_classification1LFilt 4 "OCCUPANT_CLASSIFICATION_OCCUPIED_ALLOW" 3 "OCCUPANT_CLASSIFICATION_OCCUPIED_INHIBIT" 2 "OCCUPANT_CLASSIFICATION_EMPTY" 1 "OCCUPANT_CLASSIFICATION_INIT" 0 "OCCUPANT_CLASSIFICATION_SNA" ;
VAL_ 670 ICR_classification1RqF 1 "OCCUPANT_CLASSIFICATION_NOT_FAULTED" 0 "OCCUPANT_CLASSIFICATION_FAULTED" ;
VAL_ 670 ICR_classification1LLatched 4 "OCCUPANT_CLASSIFICATION_OCCUPIED_ALLOW" 3 "OCCUPANT_CLASSIFICATION_OCCUPIED_INHIBIT" 2 "OCCUPANT_CLASSIFICATION_EMPTY" 1 "OCCUPANT_CLASSIFICATION_INIT" 0 "OCCUPANT_CLASSIFICATION_SNA" ;
VAL_ 670 ICR_classification1RLatched 4 "OCCUPANT_CLASSIFICATION_OCCUPIED_ALLOW" 3 "OCCUPANT_CLASSIFICATION_OCCUPIED_INHIBIT" 2 "OCCUPANT_CLASSIFICATION_EMPTY" 1 "OCCUPANT_CLASSIFICATION_INIT" 0 "OCCUPANT_CLASSIFICATION_SNA" ;
VAL_ 664 ICR_sensorMode 15 "ICR_SENSOR_INTERFACE_MODE_ERROR" 7 "ICR_SENSOR_INTERFACE_MODE_LPM_TEST" 6 "ICR_SENSOR_INTERFACE_MODE_OCCUPANCY_DETECTION" 5 "ICR_SENSOR_INTERFACE_MODE_HPM_TEST" 4 "ICR_SENSOR_INTERFACE_MODE_CALIBRATION" 3 "ICR_SENSOR_INTERFACE_MODE_CW" 2 "ICR_SENSOR_MODE_END_OF_LINE_TEST" 1 "ICR_SENSOR_MODE_INTRUSTION" 0 "ICR_SENSOR_MODE_SENSOR_STOPPED" ;
VAL_ 664 ICR_blocked 2 "ICR_BLOCKED_TRUE" 1 "ICR_BLOCKED_FALSE" 0 "ICR_BLOCKED_SNA" ;
VAL_ 664 ICR_algoVersion 37 "ICR_ALGO_VERSION_FUTURE_RELEASE_37" 36 "ICR_ALGO_VERSION_v06112025" 35 "ICR_ALGO_VERSION_v04232025" 34 "ICR_ALGO_VERSION_v03192025" 33 "ICR_ALGO_VERSION_v02142025" 32 "ICR_ALGO_VERSION_v01222025" 31 "ICR_ALGO_VERSION_v10072024" 30 "ICR_ALGO_VERSION_v08282024" 29 "ICR_ALGO_VERSION_v07172024" 28 "ICR_ALGO_VERSION_v06122024" 27 "ICR_ALGO_VERSION_v04242024" 26 "ICR_ALGO_VERSION_v03142024" 25 "ICR_ALGO_VERSION_v01312024" 24 "ICR_ALGO_VERSION_v12192023" 23 "ICR_ALGO_VERSION_v10252023" 22 "ICR_ALGO_VERSION_v10112023" 21 "ICR_ALGO_VERSION_v09222023" 20 "ICR_ALGO_VERSION_V08302023" 19 "ICR_ALGO_VERSION_V07172023" 18 "ICR_ALGO_VERSION_V06152023" 17 "ICR_ALGO_VERSION_V06072023" 16 "ICR_ALGO_VERSION_V05192023" 15 "ICR_ALGO_VERSION_V04262023" 14 "ICR_ALGO_VERSION_V1222" 13 "ICR_ALGO_VERSION_V1125" 12 "ICR_ALGO_VERSION_V1118" 11 "ICR_ALGO_VERSION_V1103" 10 "ICR_ALGO_VERSION_V1013" 9 "ICR_ALGO_VERSION_V1006" 8 "ICR_ALGO_VERSION_V927" 7 "ICR_ALGO_VERSION_V902" 6 "ICR_ALGO_VERSION_V826" 5 "ICR_ALGO_VERSION_V803" 4 "ICR_ALGO_VERSION_V715" 3 "ICR_ALGO_VERSION_V711" 2 "ICR_ALGO_VERSION_V204" 1 "ICR_ALGO_VERSION_EXPERIMENTAL" 0 "ICR_ALGO_VERSION_NONE" ;
VAL_ 664 ICR_intrusionStatus 2 "INSTRUSION_STATUS_INTRUSION_DETECTED" 1 "INSTRUSION_STATUS_NONE" 0 "INSTRUSION_STATUS_UNKNOWN" ;
VAL_ 1012 LS_lightShowIndex 24 "LightShowMux24" 23 "LightShowMux23" 22 "LightShowMux22" 21 "LightShowMux21" 20 "LightShowMux20" 19 "LightShowMux19" 18 "LightShowMux18" 17 "LightShowMux17" 16 "LightShowMux16" 15 "LightShowMux15" 14 "LightShowMux14" 13 "LightShowMux13" 12 "LightShowMux12" 11 "LightShowMux11" 10 "LightShowMux10" 9 "LightShowMux9" 8 "LightShowMux8" 7 "LightShowMux7" 6 "LightShowMux6" 5 "LightShowMux5" 4 "LightShowMux4" 3 "LightShowMux3" 2 "LightShowMux2" 1 "LightShowMux1" 0 "LightShowMux0" ;
VAL_ 1012 LS_lightLeftRampedChannel1Durati 3 "TWO_SECONDS" 2 "ONE_SECOND" 1 "HALF_SECOND" 0 "INSTANT" ;
VAL_ 1012 LS_lightLeftRampedChannel2Durati 3 "TWO_SECONDS" 2 "ONE_SECOND" 1 "HALF_SECOND" 0 "INSTANT" ;
VAL_ 1012 LS_lightLeftRampedChannel3Durati 3 "TWO_SECONDS" 2 "ONE_SECOND" 1 "HALF_SECOND" 0 "INSTANT" ;
VAL_ 1012 LS_lightLeftRampedChannel4Durati 3 "TWO_SECONDS" 2 "ONE_SECOND" 1 "HALF_SECOND" 0 "INSTANT" ;
VAL_ 1012 LS_lightLeftRampedChannel5Durati 3 "TWO_SECONDS" 2 "ONE_SECOND" 1 "HALF_SECOND" 0 "INSTANT" ;
VAL_ 1012 LS_lightLeftRampedChannel6Durati 3 "TWO_SECONDS" 2 "ONE_SECOND" 1 "HALF_SECOND" 0 "INSTANT" ;
VAL_ 1012 LS_lightLeftRampedChannel7Durati 3 "TWO_SECONDS" 2 "ONE_SECOND" 1 "HALF_SECOND" 0 "INSTANT" ;
VAL_ 1012 LS_lightRightRampedChannel1Durat 3 "TWO_SECONDS" 2 "ONE_SECOND" 1 "HALF_SECOND" 0 "INSTANT" ;
VAL_ 1012 LS_lightRightRampedChannel2Durat 3 "TWO_SECONDS" 2 "ONE_SECOND" 1 "HALF_SECOND" 0 "INSTANT" ;
VAL_ 1012 LS_lightRightRampedChannel3Durat 3 "TWO_SECONDS" 2 "ONE_SECOND" 1 "HALF_SECOND" 0 "INSTANT" ;
VAL_ 1012 LS_lightRightRampedChannel4Durat 3 "TWO_SECONDS" 2 "ONE_SECOND" 1 "HALF_SECOND" 0 "INSTANT" ;
VAL_ 1012 LS_lightRightRampedChannel5Durat 3 "TWO_SECONDS" 2 "ONE_SECOND" 1 "HALF_SECOND" 0 "INSTANT" ;
VAL_ 1012 LS_lightRightRampedChannel6Durat 3 "TWO_SECONDS" 2 "ONE_SECOND" 1 "HALF_SECOND" 0 "INSTANT" ;
VAL_ 1012 LS_lightRightRampedChannel7Durat 3 "TWO_SECONDS" 2 "ONE_SECOND" 1 "HALF_SECOND" 0 "INSTANT" ;
VAL_ 1012 LS_mirrorRequestLeft 4 "HOLIDAY_PARTY_STOP" 3 "HOLIDAY_PARTY_CLOSE" 2 "HOLIDAY_PARTY_DANCE" 1 "HOLIDAY_PARTY_OPEN" 0 "HOLIDAY_PARTY_IDLE" ;
VAL_ 1012 LS_mirrorRequestRight 4 "HOLIDAY_PARTY_STOP" 3 "HOLIDAY_PARTY_CLOSE" 2 "HOLIDAY_PARTY_DANCE" 1 "HOLIDAY_PARTY_OPEN" 0 "HOLIDAY_PARTY_IDLE" ;
VAL_ 1012 LS_liftgateRequest 4 "HOLIDAY_PARTY_STOP" 3 "HOLIDAY_PARTY_CLOSE" 2 "HOLIDAY_PARTY_DANCE" 1 "HOLIDAY_PARTY_OPEN" 0 "HOLIDAY_PARTY_IDLE" ;
VAL_ 1012 LS_windowRequestLF 4 "HOLIDAY_PARTY_STOP" 3 "HOLIDAY_PARTY_CLOSE" 2 "HOLIDAY_PARTY_DANCE" 1 "HOLIDAY_PARTY_OPEN" 0 "HOLIDAY_PARTY_IDLE" ;
VAL_ 1012 LS_windowRequestLR 4 "HOLIDAY_PARTY_STOP" 3 "HOLIDAY_PARTY_CLOSE" 2 "HOLIDAY_PARTY_DANCE" 1 "HOLIDAY_PARTY_OPEN" 0 "HOLIDAY_PARTY_IDLE" ;
VAL_ 1012 LS_windowRequestRF 4 "HOLIDAY_PARTY_STOP" 3 "HOLIDAY_PARTY_CLOSE" 2 "HOLIDAY_PARTY_DANCE" 1 "HOLIDAY_PARTY_OPEN" 0 "HOLIDAY_PARTY_IDLE" ;
VAL_ 1012 LS_windowRequestRR 4 "HOLIDAY_PARTY_STOP" 3 "HOLIDAY_PARTY_CLOSE" 2 "HOLIDAY_PARTY_DANCE" 1 "HOLIDAY_PARTY_OPEN" 0 "HOLIDAY_PARTY_IDLE" ;
VAL_ 1012 LS_presentingHandleRequestLF 4 "HOLIDAY_PARTY_STOP" 3 "HOLIDAY_PARTY_CLOSE" 2 "HOLIDAY_PARTY_DANCE" 1 "HOLIDAY_PARTY_OPEN" 0 "HOLIDAY_PARTY_IDLE" ;
VAL_ 1012 LS_presentingHandleRequestLR 4 "HOLIDAY_PARTY_STOP" 3 "HOLIDAY_PARTY_CLOSE" 2 "HOLIDAY_PARTY_DANCE" 1 "HOLIDAY_PARTY_OPEN" 0 "HOLIDAY_PARTY_IDLE" ;
VAL_ 1012 LS_presentingHandleRequestRF 4 "HOLIDAY_PARTY_STOP" 3 "HOLIDAY_PARTY_CLOSE" 2 "HOLIDAY_PARTY_DANCE" 1 "HOLIDAY_PARTY_OPEN" 0 "HOLIDAY_PARTY_IDLE" ;
VAL_ 1012 LS_presentingHandleRequestRR 4 "HOLIDAY_PARTY_STOP" 3 "HOLIDAY_PARTY_CLOSE" 2 "HOLIDAY_PARTY_DANCE" 1 "HOLIDAY_PARTY_OPEN" 0 "HOLIDAY_PARTY_IDLE" ;
VAL_ 1012 LS_powerFrontDoorRequestLeft 4 "HOLIDAY_PARTY_STOP" 3 "HOLIDAY_PARTY_CLOSE" 2 "HOLIDAY_PARTY_DANCE" 1 "HOLIDAY_PARTY_OPEN" 0 "HOLIDAY_PARTY_IDLE" ;
VAL_ 1012 LS_powerFrontDoorRequestRight 4 "HOLIDAY_PARTY_STOP" 3 "HOLIDAY_PARTY_CLOSE" 2 "HOLIDAY_PARTY_DANCE" 1 "HOLIDAY_PARTY_OPEN" 0 "HOLIDAY_PARTY_IDLE" ;
VAL_ 1012 LS_falconDoorRequestLeft 4 "HOLIDAY_PARTY_STOP" 3 "HOLIDAY_PARTY_CLOSE" 2 "HOLIDAY_PARTY_DANCE" 1 "HOLIDAY_PARTY_OPEN" 0 "HOLIDAY_PARTY_IDLE" ;
VAL_ 1012 LS_falconDoorRequestRight 4 "HOLIDAY_PARTY_STOP" 3 "HOLIDAY_PARTY_CLOSE" 2 "HOLIDAY_PARTY_DANCE" 1 "HOLIDAY_PARTY_OPEN" 0 "HOLIDAY_PARTY_IDLE" ;
VAL_ 1012 LS_chargePortRequest 3 "REQUEST_SNA" 2 "REQUEST_CLOSE" 1 "REQUEST_OPEN" 0 "REQUEST_NONE" ;
VAL_ 1012 LS_suspensionRequest 3 "SUSPENSION_REQUEST_SNA" 2 "SUSPENSION_REQUEST_LOWER" 1 "SUSPENSION_REQUEST_RAISE" 0 "SUSPENSION_REQUEST_NONE" ;
VAL_ 740 PCS2_logMessageSelect 208 "PCS2_LOG_NUM_MSGS" 207 "PCS2_LOGGING_SELECT_NUM_CPU3" 206 "CPU3_UTILIZATION" 205 "AC_LINE_DC_OFFSET_PRE_RELAY_VOLT_SENSE" 204 "AC_LINE_DC_OFFSET_VOLT_SENSE" 203 "CYCLO_B_SWITCHING_FREQ" 202 "CYCLO_B_ZCD_STATUS" 201 "MICROGRID_HEARTBEAT" 200 "IPC_CPU3_LOCK_MONITOR" 199 "DCAC_SWITCHING_FREQUENCY" 198 "CYCLO_B_INFO" 197 "CYCLO_B_MODEL_JUNCTION_TEMP_MAX" 196 "CYCLO_B_MODEL_JUNCTION_TEMP" 195 "CYCLO_B_SURGE_DERATING_FACTOR" 194 "CYCLO_B_TANK_PARAMS" 193 "CYCLO_B_TANK_MEASUREMENTS" 192 "CYCLO_LEG_PEAK_CURRENT" 163 "PCS2_LOGGING_SELECT_NUM_CPU2" 162 "EPTO_INFO" 161 "CYCLO_AC_PRE_RELAY_PEAK_V" 160 "CYCLO_AC_LINE_TO_LINE_PEAK_V" 159 "I2T_GENERATED_HEAT_CP_LIMIT" 158 "CPU2_UTILIZATION" 157 "AC_RELAY_INFO" 156 "CYCLO_A_SWITCHING_FREQ" 155 "CYCLO_A_ZCD_STATUS" 154 "IPC_CPU2_LOCK_MONITOR" 153 "CABIN_AND_BED_GRID_FORM_LIFETIME_KVAH" 152 "OUTLET_GRID_FORM_LIFETIME_KVAH" 151 "DCAC_LIFETIME_KVAH" 150 "I2T_GENERATED_HEAT_HW_LIMIT" 149 "DCAC_CURRENT_LIMITS_3" 148 "DCAC_CURRENT_LIMITS_2" 147 "DCAC_CURRENT_LIMITS" 146 "CYCLO_A_INFO" 145 "CYCLO_A_MODEL_JUNCTION_TEMP_MAX" 144 "CYCLO_A_MODEL_JUNCTION_TEMP" 143 "CYCLO_A_SURGE_DERATING_FACTOR" 142 "CYCLO_A_TANK_PARAMS" 141 "AC_LINE_PHASE_ANGLE_DIFF" 140 "AC_LINE_PHASE_STATUS" 139 "DCAC_CHARGING_CURRENT_LIMITS" 138 "AC_LINE_TO_CHASSIS_VOLT_CALCULATED" 137 "CYCLO_A_TANK_MEASUREMENTS" 136 "CYCLO_AC_LINE_TO_NEUTRAL_PEAK_V" 135 "DCAC_STATE_MACHINES" 134 "DCAC_HV_BUS_SENSE" 133 "AC_LINE_TO_LINE_FREQUENCY" 132 "AC_LINE_TO_NEUTRAL_FREQUENCY" 131 "AC_GRID_STATUS" 130 "AC_LINE_CURRENT_SENSE" 129 "AC_LINE_TO_LINE_VOLT_CALCULATED" 128 "AC_LINE_TO_NEUTRAL_VOLT_SENSE" 100 "PCS2_LOGGING_SELECT_NUM_CPU1" 99 "DCDC_B_LV_CURRENT_SENSE" 98 "DCDC_TEMP_AUX" 97 "DCDC_HW_ZCD" 96 "DCDC_B_THERMAL_MODELING_2" 95 "CPU1_UTILIZATION" 94 "ADC_TEMP_SENSE_MIN" 93 "CYCLO_B_TEMP_MAX" 92 "CYCLO_B_TEMP_MIN" 91 "CYCLO_A_TEMP_MAX" 90 "CYCLO_A_TEMP_MIN" 89 "ADC_TEMP_SENSE" 88 "DCDC_TEMP" 87 "CYCLO_B_TEMP" 86 "CYCLO_A_TEMP" 85 "PCS2LITE_TEMP_2" 84 "PCS2LITE_TEMP_1" 83 "DCDC_B_HV_BUS_CURRENT_SENSE" 82 "ADC_TEMP_SENSE_MAX" 81 "PCSCI_DCDC_TEMP" 80 "DCDC_TEMP_MAX" 79 "DCDC_TEMP_MIN" 78 "DCDC_B_SWITCHING_FREQ" 77 "DCDC_B_ZCD_STATUS" 76 "DCDC_B_ARBITRATION_STATUS" 75 "IPC_CPU1_LOCK_MONITOR" 74 "DCDC_B_STAGE_STATUS" 73 "DCDC_B_HV_BUS_IMPEDANCE_ESTIMATION" 72 "DCDC_B_THERMAL_MODELING_1" 71 "DCDC_B_LIFETIME_ENERGY_STATS" 70 "DCDC_B_VOLTAGE_TARGET" 69 "DCDC_B_TANK_MEASUREMENTS" 68 "DCDC_B_HALF_BUS_VOLTAGE_SENSE_MIN_MAX" 67 "DCDC_B_TANK_PARAMS" 66 "DCDC_B_HV_FULL_MIN_MAX" 65 "DCDC_B_CURRENT_COMMAND" 64 "DCDC_B_HV_VOLTAGE_SENSE" 42 "PCS2_LOGGING_SELECT_NUM_CPU0" 41 "DCDC_A_THERMAL_MODELING_2" 40 "DCDC_A_LV_CURRENT_SENSE" 39 "PCS2_WAKE_CONFIG" 38 "BUCK_BOOST_CURRENT_MONITOR" 37 "PCS2_PRU_MONITOR_PCSCI_LOG" 36 "PCS2_PRU_MONITOR_PCS2LITE_LOG" 35 "PCS2_PRU_MONITOR_LOG" 34 "EFUSE_MONITOR" 33 "RAIL_SENSE_LV_BIAS" 32 "BUCK_BOOST_CONTROL_MONITOR" 31 "FC_VOLTAGE_SENSE" 30 "RAIL_SENSE_2V5" 29 "RAIL_SENSE_13V5" 28 "CURRENT_SENSE_48V0_18V0" 27 "RAIL_SENSE_48V0" 26 "RAIL_SENSE_1V6" 25 "RAIL_SENSE_4V5" 24 "RAIL_SENSE_10V0" 23 "CPU0_UTILIZATION" 22 "HEALTH_CHECK_STATUS" 21 "DCDC_A_SWITCHING_FREQ" 20 "DCDC_A_ZCD_STATUS" 19 "DCDC_A_ARBITRATION_STATUS" 18 "IPC_CPU0_LOCK_MONITOR" 17 "DCDC_A_STAGE_STATUS" 16 "RAIL_SENSE_18V0" 15 "MFG_FUNCTIONAL_TEST_IOX" 14 "MFG_FUNCTIONAL_TEST_CALIBRATE_ITERATIVE" 13 "MFG_FUNCTIONAL_TEST_CALIBRATE" 12 "MFG_FUNCTIONAL_TEST_INFO" 11 "DCDC_A_THERMAL_MODELING_1" 10 "DCDC_A_LIFETIME_ENERGY_STATS" 9 "DCDC_A_VOLTAGE_TARGET" 8 "DCDC_A_TANK_MEASUREMENTS" 7 "DCDC_A_HALF_BUS_VOLTAGE_SENSE_MIN_MAX" 6 "DCDC_A_TANK_PARAMS" 5 "DCDC_A_VOLTAGE_SENSE_MIN_MAX" 4 "SYSTEM_STATUS_1" 3 "DCDC_LV_BUS_SENSE" 2 "DCDC_A_CURRENT_COMMAND" 1 "DCDC_STATE_MACHINES" 0 "DCDC_A_HV_VOLTAGE_SENSE" ;
VAL_ 740 PCS2_dcdcAStateMachineState 5 "DCDC_STAGE_STATE_NUM_STATES" 4 "DCDC_STAGE_STATE_FAULTED" 3 "DCDC_STAGE_STATE_ACTIVE" 2 "DCDC_STAGE_STATE_PRECONDITION" 1 "DCDC_STAGE_STATE_STANDBY" 0 "DCDC_STAGE_STATE_POWER_UP_INIT" ;
VAL_ 740 PCS2_dcdcBStateMachineState 5 "DCDC_STAGE_STATE_NUM_STATES" 4 "DCDC_STAGE_STATE_FAULTED" 3 "DCDC_STAGE_STATE_ACTIVE" 2 "DCDC_STAGE_STATE_PRECONDITION" 1 "DCDC_STAGE_STATE_STANDBY" 0 "DCDC_STAGE_STATE_POWER_UP_INIT" ;
VAL_ 740 PCS2_dcdcAStageModeRequest 3 "DCDC_STAGE_MODE_HV_DISCHARGE" 2 "DCDC_STAGE_MODE_HV_PRECHARGE" 1 "DCDC_STAGE_MODE_LV_REGULATION" 0 "DCDC_STAGE_MODE_DISABLE" ;
VAL_ 740 PCS2_dcdcBStageModeRequest 3 "DCDC_STAGE_MODE_HV_DISCHARGE" 2 "DCDC_STAGE_MODE_HV_PRECHARGE" 1 "DCDC_STAGE_MODE_LV_REGULATION" 0 "DCDC_STAGE_MODE_DISABLE" ;
VAL_ 740 PCS2_dcdcALifetimekWh 16777215 "SNA" ;
VAL_ 740 PCS2_dcdcBLifetimekWh 16777215 "SNA" ;
VAL_ 740 PCS2_dcdcA_lv2Temp -1023 "SNA" ;
VAL_ 740 PCS2_dcdcB_lv2Temp -1023 "SNA" ;
VAL_ 740 PCS2_dcdcA_hvTemp -1023 "SNA" ;
VAL_ 740 PCS2_dcdcB_hvTemp -1023 "SNA" ;
VAL_ 740 PCS2_acChargeLifetimekVAh 16777215 "SNA" ;
VAL_ 740 PCS2_v2xGridFormLifetimekVAh 16777215 "SNA" ;
VAL_ 740 PCS2_cabinOnlyL2L3LifetimekVAh 16777215 "SNA" ;
VAL_ 740 PCS2_totalOutletLifetimekVAh 16777215 "SNA" ;
VAL_ 740 PCS2_cabinAndBedL1L2LifetimekVAh 16777215 "SNA" ;
VAL_ 740 PCS2_cabinAndBedL2L3LifetimekVAh 16777215 "SNA" ;
VAL_ 516 PCS_chgMainState 9 "PCS_CHG_STATE_CLEAR_FAULTS" 8 "PCS_CHG_STATE_FAULTED" 7 "PCS_CHG_STATE_SHUTDOWN" 6 "PCS_CHG_STATE_ENABLE" 5 "PCS_CHG_STATE_SYSTEM_CONFIG" 4 "PCS_CHG_STATE_QUALIFY_LINE_CONFIG" 3 "PCS_CHG_STATE_WAIT_FOR_LINE_VOLTAGE" 2 "PCS_CHG_STATE_STARTUP" 1 "PCS_CHG_STATE_IDLE" 0 "PCS_CHG_STATE_INIT" ;
VAL_ 516 PCS_powerTransferStatus 3 "PCS_POWER_TRANSFER_FAULTED" 2 "PCS_POWER_TRANSFER_ENABLED" 1 "PCS_POWER_TRANSFER_BLOCKED" 0 "PCS_POWER_TRANSFER_STANDBY" ;
VAL_ 516 PCS_gridConfig 3 "GRID_CONFIG_THREE_PHASE_DELTA" 2 "GRID_CONFIG_THREE_PHASE" 1 "GRID_CONFIG_SINGLE_PHASE" 0 "GRID_CONFIG_SNA" ;
VAL_ 516 PCS_chgMaxAcPowerAvailable 255 "SNA" ;
VAL_ 516 PCS_powerTransferShutdownRequest 3 "EMERGENCY_SHUTDOWN_REQUESTED" 2 "ESCALATED_SHUTDOWN_REQUESTED" 1 "GRACEFUL_SHUTDOWN_REQUESTED" 0 "NO_SHUTDOWN_REQUESTED" ;
VAL_ 516 PCS_hwVariantType 3 "PCS_HW_VARIANT_TYPE_SNA" 2 "PCS_THREE_PHASES_VARIANT" 1 "PCS_32A_SINGLE_PHASE_VARIANT" 0 "PCS_48A_SINGLE_PHASE_VARIANT" ;
